VERSION "HNNBNNNYNNNNNNNNNNNNNNNNNNNNNNNNNNNNNNNNNN/4/%%%/4/'%**4NNN///"

NS_ :

BS_:

BU_: BAP_Tester BCM1 Gateway Klima_MSB Lift_VA VAS_L VAS_R

BO_ 960 Klemmen_Status_01: 4 Gateway
 SG_ Klemmen_Status_01_CRC : 0|8@1+ (1,0) [0|255] ""  BCM1,Lift_VA
 SG_ Klemmen_Status_01_BZ : 8|4@1+ (1,0) [0|15] ""  BCM1,Lift_VA
 SG_ RSt_Fahrerhinweise : 12|4@1+ (1.0,0.0) [0.0|15] ""  Vector__XXX
 SG_ ZAS_Kl_S : 16|1@1+ (1.0,0.0) [0.0|1] ""  BCM1,Klima_MSB,VAS_L,VAS_R
 SG_ ZAS_Kl_15 : 17|1@1+ (1.0,0.0) [0.0|1] ""  BCM1,Klima_MSB,Lift_VA,VAS_L,VAS_R
 SG_ ZAS_Kl_X : 18|1@1+ (1.0,0.0) [0.0|1] ""  Vector__XXX
 SG_ ZAS_Kl_50_Startanforderung : 19|1@1+ (1.0,0.0) [0.0|1] ""  BCM1,Klima_MSB
 SG_ BCM_Remotestart_Betrieb : 20|1@1+ (1.0,0.0) [0.0|1] ""  BCM1,Klima_MSB
 SG_ ZAS_Kl_Infotainment : 21|1@1+ (1.0,0.0) [0.0|1] ""  Vector__XXX
 SG_ BCM_Remotestart_KL15_Anf : 22|1@1+ (1.0,0.0) [0.0|1] ""  BCM1
 SG_ BCM_Remotestart_MO_Start : 23|1@1+ (1.0,0.0) [0.0|1] ""  Vector__XXX
 SG_ KST_Warn_P1_ZST_def : 24|1@1+ (1.0,0.0) [0.0|1] ""  Vector__XXX
 SG_ KST_Warn_P2_ZST_def : 25|1@1+ (1.0,0.0) [0.0|1] ""  Vector__XXX
 SG_ KST_Fahrerhinweis_1 : 26|1@1+ (1.0,0.0) [0.0|1] ""  Vector__XXX
 SG_ KST_Fahrerhinweis_2 : 27|1@1+ (1.0,0.0) [0.0|1] ""  Vector__XXX
 SG_ BCM_Ausparken_Betrieb : 28|1@1+ (1.0,0.0) [0.0|1] ""  Vector__XXX
 SG_ KST_Fahrerhinweis_4 : 29|1@1+ (1.0,0.0) [0.0|1] ""  Vector__XXX
 SG_ KST_Fahrerhinweis_5 : 30|1@1+ (1.0,0.0) [0.0|1] ""  Vector__XXX
 SG_ KST_Fahrerhinweis_6 : 31|1@1+ (1.0,0.0) [0.0|1] ""  Vector__XXX

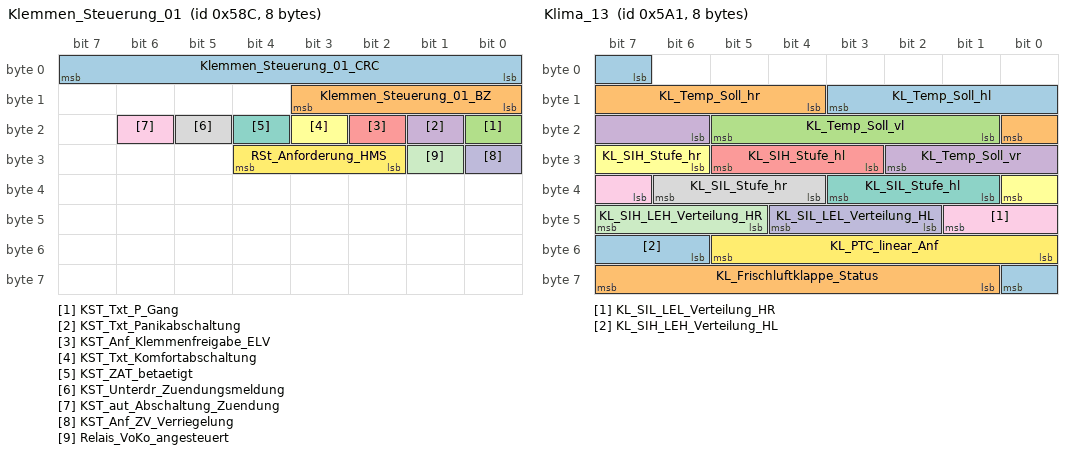
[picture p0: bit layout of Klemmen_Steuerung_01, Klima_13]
BO_ 1420 Klemmen_Steuerung_01: 8 Gateway
 SG_ Klemmen_Steuerung_01_CRC : 0|8@1+ (1,0) [0|255] ""  Vector__XXX
 SG_ Klemmen_Steuerung_01_BZ : 8|4@1+ (1,0) [0|15] ""  Vector__XXX
 SG_ KST_Txt_P_Gang : 16|1@1+ (1.0,0.0) [0.0|1] ""  Vector__XXX
 SG_ KST_Txt_Panikabschaltung : 17|1@1+ (1.0,0.0) [0.0|1] ""  Vector__XXX
 SG_ KST_Anf_Klemmenfreigabe_ELV : 18|1@1+ (1.0,0.0) [0.0|1] ""  Vector__XXX
 SG_ KST_Txt_Komfortabschaltung : 19|1@1+ (1.0,0.0) [0.0|1] ""  Vector__XXX
 SG_ KST_ZAT_betaetigt : 20|1@1+ (1.0,0.0) [0.0|1] ""  Vector__XXX
 SG_ KST_Unterdr_Zuendungsmeldung : 21|1@1+ (1.0,0.0) [0.0|1] ""  Vector__XXX
 SG_ KST_aut_Abschaltung_Zuendung : 22|1@1+ (1.0,0.0) [0.0|1] ""  BCM1
 SG_ KST_Anf_ZV_Verriegelung : 24|1@1+ (1.0,0.0) [0.0|1] ""  Vector__XXX
 SG_ Relais_VoKo_angesteuert : 25|1@1+ (1.0,0.0) [0.0|1] ""  BCM1
 SG_ RSt_Anforderung_HMS : 26|3@1+ (1.0,0.0) [0.0|7] ""  Vector__XXX

BO_ 1646 Klima_03: 8 BCM1
 SG_ KL_STL_aktiv : 0|1@1+ (1.0,0.0) [0.0|1] ""  Gateway
 SG_ KL_STH_aktiv : 1|1@1+ (1.0,0.0) [0.0|1] ""  BCM1,Gateway
 SG_ KL_Solarluefter_aktiv : 2|1@1+ (1.0,0.0) [0.0|1] ""  Gateway
 SG_ KL_Umluft_Taste : 3|1@1+ (1.0,0.0) [0.0|1] ""  Gateway
 SG_ KL_Geblaese_Fond_Status : 4|4@1+ (1.0,0.0) [0.0|15] ""  BCM1,Gateway
 SG_ KL_STH_Ansteuerung : 8|2@1+ (1.0,0.0) [0.0|3] ""  Gateway
 SG_ KL_STH_Betriebsdauer : 10|6@1+ (1,0) [0|60] "Unit_Minut"  Gateway
 SG_ KL_Magnetventil : 16|1@1+ (1.0,0.0) [0.0|1] ""  Gateway
 SG_ KL_WaPu : 17|1@1+ (1.0,0.0) [0.0|1] ""  Gateway
 SG_ KL_Geblaese_Status : 18|4@1+ (1.0,0.0) [0.0|15] ""  BCM1,Gateway
 SG_ KL_Restwaerme_aktiv : 22|1@1+ (1.0,0.0) [0.0|1] ""  Gateway
 SG_ KL_Kompressorkupplung : 23|1@1+ (1.0,0.0) [0.0|1] ""  BCM1,Gateway
 SG_ KL_BCmE_Livetip_Freigabe : 24|1@1+ (1.0,0.0) [0.0|1] ""  Gateway
 SG_ KL_HYB_ASV_hinten_schliessen_Anf : 25|1@1+ (1.0,0.0) [0.0|1] ""  Gateway
 SG_ KL_HYB_ASV_vorne_schliessen_Anf : 26|1@1+ (1.0,0.0) [0.0|1] ""  Gateway
 SG_ KL_ErwVK_Zusatzrelais : 27|1@1+ (1.0,0.0) [0.0|1] ""  Gateway
 SG_ KL_Status_Beduftung : 28|1@1+ (1.0,0.0) [0.0|1] ""  Gateway
 SG_ KL_Status_Ionisator_Front : 29|1@1+ (1.0,0.0) [0.0|1] ""  Gateway
 SG_ KL_STH_Timer_Status : 30|1@1+ (1.0,0.0) [0.0|1] ""  Gateway
 SG_ KL_ErwVK_Anf : 31|1@1+ (1.0,0.0) [0.0|1] ""  BCM1,Gateway
 SG_ KL_Innen_Temp : 32|8@1+ (0.5,-50) [-50.0|76.0] "Unit_DegreCelsi"  BCM1,Gateway
 SG_ KL_I_Geblaese_Fond : 40|8@1+ (0.25,0) [0.00|63.50] "Unit_Amper"  Gateway
 SG_ KL_Anf_AussenspiegelHzg : 48|1@1+ (1.0,0.0) [0.0|1] ""  Gateway
 SG_ KL_Heizkreisventilstellung : 49|2@1+ (1.0,0.0) [0.0|3] ""  Gateway
 SG_ KL_FSH_Automatikbetrieb : 51|1@1+ (1.0,0.0) [0.0|1] ""  Gateway
 SG_ KL_SIH_LEH_Verteilung_VL : 52|3@1+ (1.0,0.0) [0.0|7] ""  BCM1,Gateway
 SG_ KL_SIH_LEL_Verteilung_VL : 55|3@1+ (1.0,0.0) [0.0|7] ""  BCM1,Gateway
 SG_ KL_SIH_LEH_Verteilung_VR : 58|3@1+ (1.0,0.0) [0.0|7] ""  BCM1,Gateway
 SG_ KL_SIH_LEL_Verteilung_VR : 61|3@1+ (1.0,0.0) [0.0|7] ""  BCM1,Gateway

BO_ 1663 Klima_05: 8 BCM1
 SG_ KL_Mod_Display_li : 0|4@1+ (1.0,0.0) [0.0|15] ""  Gateway
 SG_ KL_Mod_Display_re : 4|4@1+ (1.0,0.0) [0.0|15] ""  Gateway
 SG_ KL_Fondbed_vorne_aktiv : 8|1@1+ (1.0,0.0) [0.0|1] ""  Gateway
 SG_ KL_Fond_re_reduziert : 9|1@1+ (1.0,0.0) [0.0|1] ""  Gateway
 SG_ KL_Fond_li_reduziert : 10|1@1+ (1.0,0.0) [0.0|1] ""  Gateway
 SG_ KL_Absperrventil_Fond : 11|1@1+ (1.0,0.0) [0.0|1] ""  Gateway
 SG_ KL_SH_HL_Lastabschaltung : 12|2@1+ (1.0,0.0) [0.0|3] ""  Gateway
 SG_ KL_SH_HR_Lastabschaltung : 14|2@1+ (1.0,0.0) [0.0|3] ""  Gateway
 SG_ KL_Sollausblastemp_HL : 16|10@1+ (0.1,0) [0.0|102.2] "Unit_DegreCelsi"  Gateway
 SG_ KL_Einheiten : 26|1@1+ (1.0,0.0) [0.0|1] ""  Gateway
 SG_ KL_Kindersicherung : 27|1@1+ (1.0,0.0) [0.0|1] ""  Gateway
 SG_ KL_Heizverbraucher_aus : 28|1@1+ (1.0,0.0) [0.0|1] ""  Gateway
 SG_ KL_Heizverbraucher_Notaus : 29|1@1+ (1.0,0.0) [0.0|1] ""  Gateway
 SG_ KL_Gebl_Verst_Abs_Modus : 30|1@1+ (1.0,0.0) [0.0|1] ""  Gateway
 SG_ KL_Sollausblastemp_HR : 32|10@1+ (0.1,0) [0.0|102.2] "Unit_DegreCelsi"  Gateway
 SG_ KL_ICO2_Sensor_defekt : 42|2@1+ (1.0,0.0) [0.0|3] ""  Gateway
 SG_ KL_Umluft : 48|8@1+ (0.5,0) [0.0|100.0] "Unit_PerCent"  Gateway
 SG_ KL_Geblaesespg_Fond : 56|8@1+ (0.1,0) [0.0|25.5] "Unit_Volt"  Gateway

BO_ 1649 Klima_06: 8 BCM1
 SG_ KL_ZZ_Minute : 0|6@1+ (1,0) [0|59] "Unit_Minut"  Gateway
 SG_ KL_ZZ_Status_Timer : 6|2@1+ (1.0,0.0) [0.0|3] ""  Gateway
 SG_ KL_ZZ_Monat : 8|4@1+ (1,0) [1|12] "Unit_Month"  Gateway
 SG_ KL_ZZ_Stunde : 16|5@1+ (1,0) [0|23] "Unit_Hours"  Gateway
 SG_ KL_ZZ_Betriebsmodus : 21|3@1+ (1.0,0.0) [0.0|7] ""  Gateway
 SG_ KL_ZZ_Tag : 24|5@1+ (1,0) [1|31] "Unit_Day"  Gateway
 SG_ KL_Betriebsmodus_FH : 29|3@1+ (1.0,0.0) [0.0|7] ""  Gateway
 SG_ KL_Stopp_Wiederstart_Anz_01 : 32|1@1+ (1.0,0.0) [0.0|1] ""  Gateway
 SG_ KL_Stopp_Wiederstart_Anz_02 : 33|1@1+ (1.0,0.0) [0.0|1] ""  Gateway
 SG_ KL_Stopp_Wiederstart_Anz_03 : 34|1@1+ (1.0,0.0) [0.0|1] ""  Gateway
 SG_ KL_Stopp_Wiederstart_Anz_04 : 35|1@1+ (1.0,0.0) [0.0|1] ""  Gateway
 SG_ KL_Stopp_Wiederstart_Anz_05 : 36|1@1+ (1.0,0.0) [0.0|1] ""  Gateway
 SG_ KL_Stopp_Wiederstart_Anz_06 : 37|1@1+ (1.0,0.0) [0.0|1] ""  Gateway
 SG_ KL_Stopp_Wiederstart_Anz_07 : 38|1@1+ (1.0,0.0) [0.0|1] ""  Gateway
 SG_ KL_Stopp_Wiederstart_Anz_08 : 39|1@1+ (1.0,0.0) [0.0|1] ""  Gateway
 SG_ KL_Stopp_Wiederstart_Anz_09 : 40|1@1+ (1.0,0.0) [0.0|1] ""  Gateway
 SG_ KL_Stopp_Wiederstart_Anz_Std1 : 41|1@1+ (1.0,0.0) [0.0|1] ""  Gateway
 SG_ KL_Stopp_Wiederstart_Anz_Std2 : 42|1@1+ (1.0,0.0) [0.0|1] ""  Gateway

BO_ 1608 Klima_07: 8 BCM1
 SG_ KL_AUTO_HL_Soll : 0|1@1+ (1.0,0.0) [0.0|1] ""  Gateway
 SG_ KL_AUTO_HR_Soll : 1|1@1+ (1.0,0.0) [0.0|1] ""  Gateway
 SG_ KL_AC_Fond_Soll : 2|1@1+ (1.0,0.0) [0.0|1] ""  Gateway
 SG_ KL_Fondbedienung_aktiv : 3|1@1+ (1.0,0.0) [0.0|1] ""  Gateway
 SG_ KL_Status_Soll : 4|1@1+ (1.0,0.0) [0.0|1] ""  Gateway
 SG_ KL_Befehlszaehler_FH : 5|3@1+ (1,0) [0|7] ""  Gateway
 SG_ KL_Luftmenge_HR_Soll : 8|4@1+ (1,0) [0|12] ""  Gateway
 SG_ KL_Luftmenge_HL_Soll : 12|4@1+ (1,0) [0|12] ""  Gateway
 SG_ KL_Luftverteilung_HR_Soll : 16|4@1+ (1.0,0.0) [0.0|15] ""  Gateway
 SG_ KL_Luftverteilung_HL_Soll : 20|4@1+ (1.0,0.0) [0.0|15] ""  Gateway
 SG_ KL_SL_HL_Soll : 24|3@1+ (1,0) [0|6] ""  BCM1,Gateway
 SG_ KL_SL_HR_Soll : 27|3@1+ (1,0) [0|6] ""  BCM1,Gateway
 SG_ KL_SH_HR_Soll : 30|3@1+ (1,0) [0|6] ""  BCM1,Gateway
 SG_ KL_SH_HL_Soll : 33|3@1+ (1,0) [0|6] ""  BCM1,Gateway
 SG_ KL_Temp_HL_Soll : 36|5@1+ (0.5,15.5) [15.5|30.0] "Unit_DegreCelsi"  Gateway
 SG_ KL_Temp_HR_Soll : 41|5@1+ (0.5,15.5) [15.5|30.0] "Unit_DegreCelsi"  Gateway
 SG_ KL_Luftmenge_HR_max : 46|4@1+ (1,0) [0|12] ""  Gateway
 SG_ KL_Luftmenge_HL_max : 50|4@1+ (1,0) [0|12] ""  Gateway
 SG_ KL_Luftmenge_HR_offset : 54|5@1+ (1,-12) [-12|12] ""  Gateway
 SG_ KL_Luftmenge_HL_offset : 59|5@1+ (1,-12) [-12|12] ""  Gateway

BO_ 949 Klima_11: 8 BCM1
 SG_ KL_Drehz_Anh : 0|1@1+ (1.0,0.0) [0.0|1] ""  Gateway
 SG_ KL_Vorwarn_Komp_ein : 1|1@1+ (1.0,0.0) [0.0|1] ""  Gateway
 SG_ KL_AC_Schalter : 2|1@1+ (1.0,0.0) [0.0|1] ""  Gateway
 SG_ KL_Komp_Moment_alt : 3|1@1+ (1.0,0.0) [0.0|1] ""  Gateway
 SG_ KL_Vorwarn_Zuheizer_ein : 6|1@1+ (1.0,0.0) [0.0|1] ""  Gateway
 SG_ KL_Zustand : 7|1@1+ (1.0,0.0) [0.0|1] ""  Gateway
 SG_ KL_Kompressorkupplung_linear : 8|8@1+ (20,0) [0|4000] "Unit_MilliAmper"  BCM1,Gateway
 SG_ KL_Charisma_FahrPr : 16|4@1+ (1.0,0.0) [0.0|15] ""  Gateway
 SG_ KL_Charisma_Status : 20|2@1+ (1.0,0.0) [0.0|3] ""  Gateway
 SG_ KL_nachtr_Stopp_Anf : 22|1@1+ (1.0,0.0) [0.0|1] ""  Gateway
 SG_ KL_T_Charge : 23|1@1+ (1.0,0.0) [0.0|1] ""  Gateway
 SG_ KL_Last_Kompr : 24|8@1+ (0.25,0) [0.00|63.50] "Unit_NewtoMeter"  Gateway
 SG_ KL_Spannungs_Anf : 32|2@1+ (1.0,0.0) [0.0|3] ""  Gateway
 SG_ KL_Thermomanagement : 34|2@1+ (1.0,0.0) [0.0|3] ""  Gateway
 SG_ KL_StartStopp_Info : 36|2@1+ (1.0,0.0) [0.0|3] ""  Gateway
 SG_ KL_Freilauf_Info : 38|2@1+ (1.0,0.0) [0.0|3] ""  Gateway
 SG_ KL_Anf_KL : 40|8@1+ (0.4,0) [0.0|101.6] "Unit_PerCent"  Gateway
 SG_ KL_el_Zuheizer_Stufe : 48|3@1+ (1.0,0.0) [0.0|7] ""  BCM1,Gateway
 SG_ KL_Ausstattung_Klima : 51|3@1+ (1.0,0.0) [0.0|7] ""  BCM1,Gateway
 SG_ KL_Variante_Standheizung : 54|2@1+ (1.0,0.0) [0.0|3] ""  Gateway

BO_ 1640 Klima_12: 8 BCM1
 SG_ KL_LRH_Taster : 0|1@1+ (1.0,0.0) [0.0|1] ""  Gateway
 SG_ KL_LRH_Stufe : 1|2@1+ (1.0,0.0) [0.0|3] ""  Gateway
 SG_ HSH_Taster : 3|2@1+ (1.0,0.0) [0.0|3] ""  Gateway
 SG_ FSH_Taster : 5|1@1+ (1.0,0.0) [0.0|1] ""  Gateway
 SG_ KL_Zuheizer_Freigabe : 6|1@1+ (1.0,0.0) [0.0|1] ""  Gateway
 SG_ KL_Beschlagsgefahr : 7|1@1+ (1.0,0.0) [0.0|1] ""  Gateway
 SG_ KL_SIH_Soll_li : 8|3@1+ (1.0,0.0) [0.0|7] ""  BCM1,Gateway
 SG_ KL_SIH_Soll_re : 11|3@1+ (1.0,0.0) [0.0|7] ""  BCM1,Gateway
 SG_ KRH_Soll_li : 14|2@1+ (1.0,0.0) [0.0|3] ""  Gateway
 SG_ KL_SIL_Soll_li : 16|3@1+ (1.0,0.0) [0.0|7] ""  BCM1,Gateway
 SG_ KL_SIL_Soll_re : 19|3@1+ (1.0,0.0) [0.0|7] ""  BCM1,Gateway
 SG_ KRH_Soll_re : 22|2@1+ (1.0,0.0) [0.0|3] ""  Gateway
 SG_ KL_Geblspng_Soll : 24|8@1+ (0.05,1.45) [1.50|14.00] "Unit_Volt"  Gateway
 SG_ KL_Geblspng_Fond_Soll : 32|8@1+ (0.05,1.45) [1.50|14.00] "Unit_Volt"  Gateway
 SG_ KL_I_Geblaese : 40|8@1+ (0.25,0) [0.00|63.50] "Unit_Amper"  Gateway
 SG_ KL_Kompressorstrom_soll : 48|10@1+ (1,0) [0|1021] ""  BCM1,Gateway
 SG_ KL_Umluftklappe_Status : 58|4@1+ (1.0,0.0) [0.0|15] ""  Gateway
 SG_ KL_PTC_Verbauinfo : 62|2@1+ (1.0,0.0) [0.0|3] ""  Gateway

BO_ 1441 Klima_13: 8 BCM1
 SG_ KL_Temp_Soll_hl : 7|5@1+ (0.5,15.5) [15.5|30.0] "Unit_DegreCelsi"  BCM1,Gateway
 SG_ KL_Temp_Soll_hr : 12|5@1+ (0.5,15.5) [15.5|30.0] "Unit_DegreCelsi"  BCM1,Gateway
 SG_ KL_Temp_Soll_vl : 17|5@1+ (0.5,15.5) [15.5|30.0] "Unit_DegreCelsi"  BCM1,Gateway
 SG_ KL_Temp_Soll_vr : 22|5@1+ (0.5,15.5) [15.5|30.0] "Unit_DegreCelsi"  BCM1,Gateway
 SG_ KL_SIH_Stufe_hl : 27|3@1+ (1,0) [0|6] ""  BCM1,Gateway
 SG_ KL_SIH_Stufe_hr : 30|3@1+ (1,0) [0|6] ""  BCM1,Gateway
 SG_ KL_SIL_Stufe_hl : 33|3@1+ (1,0) [0|6] ""  BCM1,Gateway
 SG_ KL_SIL_Stufe_hr : 36|3@1+ (1,0) [0|6] ""  BCM1,Gateway
 SG_ KL_SIL_LEL_Verteilung_HR : 39|3@1+ (1.0,0.0) [0.0|7] ""  BCM1,Gateway
 SG_ KL_SIL_LEL_Verteilung_HL : 42|3@1+ (1.0,0.0) [0.0|7] ""  BCM1,Gateway
 SG_ KL_SIH_LEH_Verteilung_HR : 45|3@1+ (1.0,0.0) [0.0|7] ""  BCM1,Gateway
 SG_ KL_PTC_linear_Anf : 48|6@1+ (50,0) [0|3100] "Unit_Watt"  Gateway
 SG_ KL_SIH_LEH_Verteilung_HL : 54|3@1+ (1.0,0.0) [0.0|7] ""  BCM1,Gateway
 SG_ KL_Frischluftklappe_Status : 57|7@1+ (1,0) [0|100] "Unit_PerCent"  Gateway

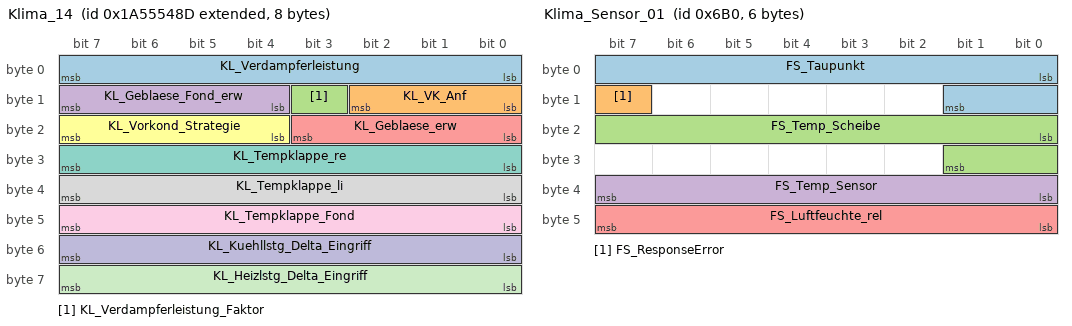
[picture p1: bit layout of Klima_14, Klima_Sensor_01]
BO_ 2589283469 Klima_14: 8 BCM1
 SG_ KL_Verdampferleistung : 0|8@1+ (25,0) [0|6325] "Unit_Watt"  Gateway
 SG_ KL_VK_Anf : 8|3@1+ (1.0,0.0) [0.0|7] ""  Gateway
 SG_ KL_Verdampferleistung_Faktor : 11|1@1+ (1.0,0.0) [0.0|1] ""  Gateway
 SG_ KL_Geblaese_Fond_erw : 12|4@1+ (1.0,0.0) [0.0|15] ""  Gateway
 SG_ KL_Geblaese_erw : 16|4@1+ (1.0,0.0) [0.0|15] ""  Gateway
 SG_ KL_Vorkond_Strategie : 20|4@1+ (1.0,0.0) [0.0|15] ""  Gateway
 SG_ KL_Tempklappe_re : 24|8@1+ (0.5,0) [0.0|100.0] "Unit_PerCent"  Gateway
 SG_ KL_Tempklappe_li : 32|8@1+ (0.5,0) [0.0|100.0] "Unit_PerCent"  Gateway
 SG_ KL_Tempklappe_Fond : 40|8@1+ (0.5,0) [0.0|100.0] "Unit_PerCent"  Gateway
 SG_ KL_Kuehllstg_Delta_Eingriff : 48|8@1+ (50,-6300) [-6300|6350] "Unit_Watt"  Gateway
 SG_ KL_Heizlstg_Delta_Eingriff : 56|8@1+ (50,-6300) [-6300|6350] "Unit_Watt"  Gateway

BO_ 2589283621 Klima_17: 8 BCM1
 SG_ KL_NV_Energie_Anf : 12|8@1+ (10,0) [0|2530] "Unit_WattHour"  Gateway
 SG_ KL_FlHz_Soll_VL : 20|3@1+ (1,0) [0|6] "Unit_None"  BCM1,Gateway
 SG_ KL_FlHz_Soll_HL : 23|3@1+ (1,0) [0|6] "Unit_None"  BCM1,Gateway
 SG_ KL_FlHz_Soll_VR : 26|3@1+ (1,0) [0|6] "Unit_None"  BCM1,Gateway
 SG_ KL_FlHz_Soll_HR : 29|3@1+ (1,0) [0|6] "Unit_None"  BCM1,Gateway
 SG_ KL_Umluft_Connect_status : 32|3@1+ (1.0,0.0) [0.0|7] ""  Gateway
 SG_ KL_ECO_PRO_Aktiv : 35|1@1+ (1.0,0.0) [0.0|1] ""  Gateway
 SG_ KL_QBit_Sonnenintensitaet : 36|1@1+ (1.0,0.0) [0.0|1] ""  Gateway
 SG_ KL_ZR_Anforderung : 37|2@1+ (1.0,0.0) [0.0|3] ""  Gateway
 SG_ KL_ACmax_Aktiv : 39|1@1+ (1.0,0.0) [0.0|1] ""  Gateway
 SG_ KL_Defrost_Aktiv : 40|1@1+ (1.0,0.0) [0.0|1] ""  Gateway
 SG_ KL_ECO_Aktiv : 41|1@1+ (1.0,0.0) [0.0|1] ""  Gateway
 SG_ KL_Status_Klimastil : 42|2@1+ (1.0,0.0) [0.0|3] ""  Gateway
 SG_ KL_Kundeneingriff_Geblaese : 44|1@1+ (1.0,0.0) [0.0|1] ""  Gateway
 SG_ KL_Thermischer_Bedarf : 45|3@1+ (1.0,0.0) [0.0|7] ""  Gateway
 SG_ KL_Eps_Innen : 48|8@1+ (0.5,-50) [-50.0|50.0] "Unit_DegreCelsi"  Gateway
 SG_ KL_Sonnenintensitaet : 56|8@1+ (10,0) [0|1000] "Unit_WattPerMeterSquar"  Gateway

BO_ 992 Klima_hinten_01: 8 BCM1
 SG_ KL_Fond_Fuss_Temp_hl : 0|10@1+ (0.1,-5) [-5.0|97.1] "Unit_DegreCelsi"  Gateway
 SG_ KL_SL_Soll_hl : 10|3@1+ (1.0,0.0) [0.0|7] ""  BCM1,Gateway
 SG_ KL_SL_Soll_hr : 13|3@1+ (1.0,0.0) [0.0|7] ""  BCM1,Gateway
 SG_ KL_Fond_Fuss_Temp_hr : 16|10@1+ (0.1,-5) [-5.0|97.1] "Unit_DegreCelsi"  Gateway
 SG_ KL_SH_Soll_hl : 26|3@1+ (1.0,0.0) [0.0|7] ""  BCM1,Gateway
 SG_ KL_SH_Soll_hr : 29|3@1+ (1.0,0.0) [0.0|7] ""  BCM1,Gateway
 SG_ KL_MA_Temp_hl : 32|10@1+ (0.1,-5) [-5.0|97.1] "Unit_DegreCelsi"  Gateway
 SG_ KL_SIH_Takt_hl : 42|1@1+ (1.0,0.0) [0.0|1] ""  Gateway
 SG_ KL_SIH_Takt_hr : 43|1@1+ (1.0,0.0) [0.0|1] ""  Gateway
 SG_ KL_Fehler_Umluft : 44|1@1+ (1.0,0.0) [0.0|1] ""  Gateway
 SG_ KL_RAB : 45|1@1+ (1.0,0.0) [0.0|1] ""  Gateway
 SG_ KL_Fond_Absperrventil : 46|1@1+ (1.0,0.0) [0.0|1] ""  Gateway
 SG_ KL_Fond_KD_Fehler : 47|1@1+ (1.0,0.0) [0.0|1] ""  Gateway
 SG_ KL_MA_Temp_hr : 48|10@1+ (0.1,-5) [-5.0|97.1] "Unit_DegreCelsi"  Gateway
 SG_ KL_Fehler_Fussraum_Klappen : 58|2@1+ (1.0,0.0) [0.0|3] ""  Gateway
 SG_ KL_Fehler_Temp_Klappen : 60|2@1+ (1.0,0.0) [0.0|3] ""  Gateway
 SG_ KL_Fehler_Temp_MA_Klappen : 62|2@1+ (1.0,0.0) [0.0|3] ""  Gateway

BO_ 1712 Klima_Sensor_01: 6 BCM1
 SG_ FS_Taupunkt : 0|10@1+ (0.1,-39.6) [-39.5|60.4] "Unit_DegreCelsi"  Gateway,Klima_MSB
 SG_ FS_ResponseError : 15|1@1+ (1.0,0.0) [0.0|1] ""  Gateway,Klima_MSB
 SG_ FS_Temp_Scheibe : 16|10@1+ (0.1,-39.6) [-39.5|60.4] "Unit_DegreCelsi"  Gateway,Klima_MSB
 SG_ FS_Temp_Sensor : 32|8@1+ (0.5,-40) [-39.5|87.0] "Unit_DegreCelsi"  Gateway,Klima_MSB
 SG_ FS_Luftfeuchte_rel : 40|8@1+ (0.5,-0.5) [0.0|100.0] "Unit_PerCent"  Gateway,Klima_MSB

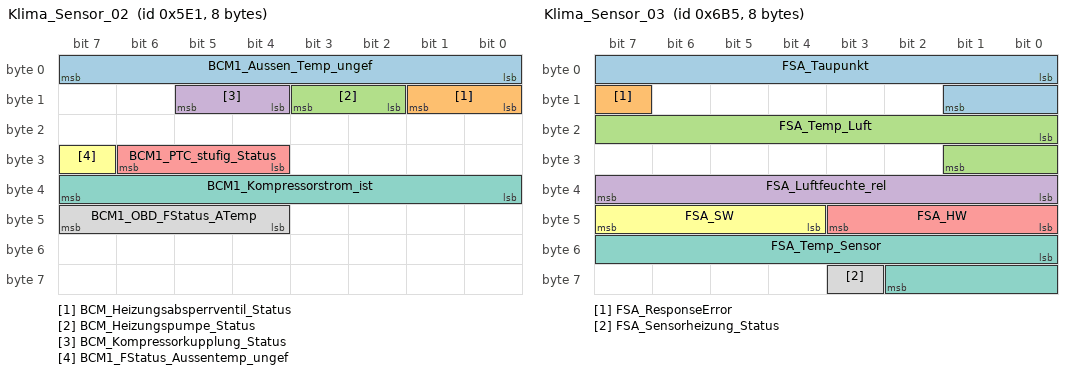
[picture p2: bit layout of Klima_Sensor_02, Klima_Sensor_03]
BO_ 1505 Klima_Sensor_02: 8 BCM1
 SG_ BCM1_Aussen_Temp_ungef : 0|8@1+ (0.5,-50) [-50.0|76.0] "Unit_DegreCelsi"  Gateway,Klima_MSB,VAS_L,VAS_R
 SG_ BCM_Heizungsabsperrventil_Status : 8|2@1+ (1.0,0.0) [0.0|3] ""  Gateway,Klima_MSB
 SG_ BCM_Heizungspumpe_Status : 10|2@1+ (1.0,0.0) [0.0|3] ""  Gateway,Klima_MSB
 SG_ BCM_Kompressorkupplung_Status : 12|2@1+ (1.0,0.0) [0.0|3] ""  Gateway,Klima_MSB
 SG_ BCM1_PTC_stufig_Status : 28|3@1+ (1.0,0.0) [0.0|7] ""  Gateway,Klima_MSB
 SG_ BCM1_FStatus_Aussentemp_ungef : 31|1@1+ (1.0,0.0) [0.0|1] ""  Gateway,Klima_MSB,VAS_L,VAS_R
 SG_ BCM1_Kompressorstrom_ist : 32|8@1+ (4,0) [0|1000] "Unit_MilliAmper"  Gateway,Klima_MSB
 SG_ BCM1_OBD_FStatus_ATemp : 44|4@1+ (1.0,0.0) [0.0|15] ""  Gateway,Klima_MSB

BO_ 1717 Klima_Sensor_03: 8 BCM1
 SG_ FSA_Taupunkt : 0|10@1+ (0.1,-40) [-40.0|60.0] "Unit_DegreCelsi"  Gateway
 SG_ FSA_ResponseError : 15|1@1+ (1.0,0.0) [0.0|1] ""  Gateway
 SG_ FSA_Temp_Luft : 16|10@1+ (0.1,-40) [-40.0|61.0] "Unit_DegreCelsi"  Gateway
 SG_ FSA_Luftfeuchte_rel : 32|8@1+ (0.5,0) [0.0|126.0] "Unit_PerCent"  Gateway
 SG_ FSA_HW : 40|4@1+ (1,0) [0|15] ""  Gateway
 SG_ FSA_SW : 44|4@1+ (1,0) [0|15] ""  Gateway
 SG_ FSA_Temp_Sensor : 48|11@1+ (0.1,-40) [-40.0|90.0] "Unit_DegreCelsi"  Gateway
 SG_ FSA_Sensorheizung_Status : 59|1@1+ (1.0,0.0) [0.0|1] ""  Gateway

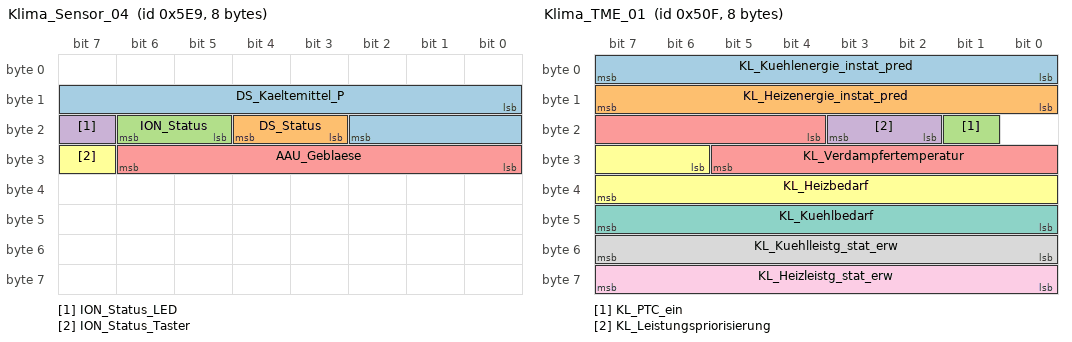
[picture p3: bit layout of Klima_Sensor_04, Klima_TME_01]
BO_ 1513 Klima_Sensor_04: 8 BCM1
 SG_ DS_Kaeltemittel_P : 8|11@1+ (0.0161,0) [0.0000|32.9245] "Unit_Bar"  Gateway
 SG_ DS_Status : 19|2@1+ (1.0,0.0) [0.0|3] ""  Gateway
 SG_ ION_Status : 21|2@1+ (1.0,0.0) [0.0|3] ""  Gateway
 SG_ ION_Status_LED : 23|1@1+ (1.0,0.0) [0.0|1] ""  Gateway
 SG_ AAU_Geblaese : 24|7@1+ (1,0) [0|100] "Unit_PerCent"  Gateway
 SG_ ION_Status_Taster : 31|1@1+ (1.0,0.0) [0.0|1] ""  Gateway

BO_ 1295 Klima_TME_01: 8 BCM1
 SG_ KL_Kuehlenergie_instat_pred : 0|8@1+ (25,0) [0|6325] "Unit_WattHour"  Gateway
 SG_ KL_Heizenergie_instat_pred : 8|8@1+ (25,0) [0|6325] "Unit_WattHour"  Gateway
 SG_ KL_PTC_ein : 17|1@1+ (1.0,0.0) [0.0|1] ""  Gateway
 SG_ KL_Leistungspriorisierung : 18|2@1+ (1.0,0.0) [0.0|3] ""  Gateway
 SG_ KL_Verdampfertemperatur : 20|10@1+ (0.1,-20) [-20.0|70.0] "Unit_DegreCelsi"  Gateway
 SG_ KL_Heizbedarf : 30|10@1+ (0.1,0) [0.1|90.0] "Unit_DegreCelsi"  Gateway
 SG_ KL_Kuehlbedarf : 40|8@1+ (0.1,0) [0.0|25.0] "Unit_DegreCelsi"  Gateway
 SG_ KL_Kuehlleistg_stat_erw : 48|8@1+ (50,0) [0|12650] "Unit_Watt"  Gateway
 SG_ KL_Heizleistg_stat_erw : 56|8@1+ (50,0) [0|12650] "Unit_Watt"  Gateway

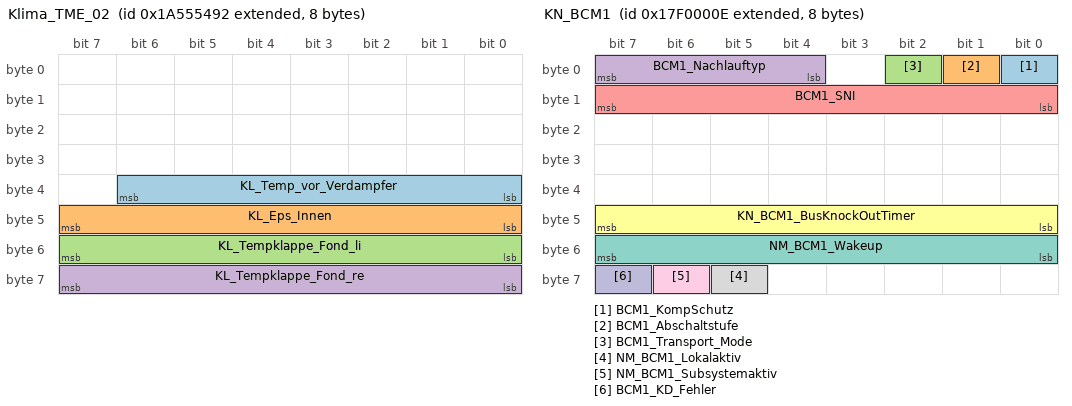
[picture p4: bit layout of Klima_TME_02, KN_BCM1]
BO_ 2589283474 Klima_TME_02: 8 BCM1
 SG_ KL_Temp_vor_Verdampfer : 32|7@1+ (1,-20) [-20|70] "Unit_DegreCelsi"  Gateway
 SG_ KL_Eps_Innen : 40|8@1+ (0.5,-50) [-50.0|50.0] "Unit_DegreCelsi"  Gateway
 SG_ KL_Tempklappe_Fond_li : 48|8@1+ (0.5,0) [0.0|100.0] "Unit_PerCent"  Gateway
 SG_ KL_Tempklappe_Fond_re : 56|8@1+ (0.5,0) [0.0|100.0] "Unit_PerCent"  Gateway

BO_ 2549088270 KN_BCM1: 8 BCM1
 SG_ BCM1_KompSchutz : 0|1@1+ (1.0,0.0) [0.0|1] ""  Vector__XXX
 SG_ BCM1_Abschaltstufe : 1|1@1+ (1.0,0.0) [0.0|1] ""  Vector__XXX
 SG_ BCM1_Transport_Mode : 2|1@1+ (1.0,0.0) [0.0|1] ""  Vector__XXX
 SG_ BCM1_Nachlauftyp : 4|4@1+ (1.0,0.0) [0.0|15] ""  Gateway
 SG_ BCM1_SNI : 8|8@1+ (1.0,0.0) [0.0|255] ""  Gateway
 SG_ KN_BCM1_BusKnockOutTimer : 40|8@1+ (1,0) [0|254] ""  Gateway
 SG_ NM_BCM1_Wakeup : 48|8@1+ (1.0,0.0) [0.0|255] ""  Vector__XXX
 SG_ NM_BCM1_Lokalaktiv : 61|1@1+ (1.0,0.0) [0.0|1] ""  Gateway
 SG_ NM_BCM1_Subsystemaktiv : 62|1@1+ (1.0,0.0) [0.0|1] ""  Gateway
 SG_ BCM1_KD_Fehler : 63|1@1+ (1.0,0.0) [0.0|1] ""  Gateway

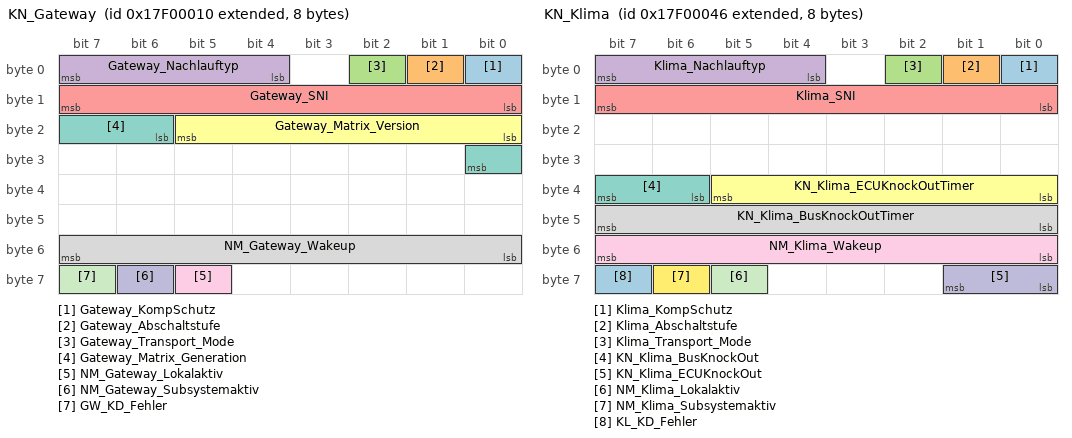
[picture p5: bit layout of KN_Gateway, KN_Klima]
BO_ 2549088272 KN_Gateway: 8 Gateway
 SG_ Gateway_KompSchutz : 0|1@1+ (1.0,0.0) [0.0|1] ""  Vector__XXX
 SG_ Gateway_Abschaltstufe : 1|1@1+ (1.0,0.0) [0.0|1] ""  Vector__XXX
 SG_ Gateway_Transport_Mode : 2|1@1+ (1.0,0.0) [0.0|1] ""  Vector__XXX
 SG_ Gateway_Nachlauftyp : 4|4@1+ (1.0,0.0) [0.0|15] ""  Vector__XXX
 SG_ Gateway_SNI : 8|8@1+ (1.0,0.0) [0.0|255] ""  Vector__XXX
 SG_ Gateway_Matrix_Version : 16|6@1+ (1,0) [0|63] "Unit_None"  Vector__XXX
 SG_ Gateway_Matrix_Generation : 22|3@1+ (1,0) [0|7] "Unit_None"  Vector__XXX
 SG_ NM_Gateway_Wakeup : 48|8@1+ (1.0,0.0) [0.0|255] ""  Vector__XXX
 SG_ NM_Gateway_Lokalaktiv : 61|1@1+ (1.0,0.0) [0.0|1] ""  Vector__XXX
 SG_ NM_Gateway_Subsystemaktiv : 62|1@1+ (1.0,0.0) [0.0|1] ""  Vector__XXX
 SG_ GW_KD_Fehler : 63|1@1+ (1.0,0.0) [0.0|1] ""  Vector__XXX

BO_ 2549088326 KN_Klima: 8 Klima_MSB
 SG_ Klima_KompSchutz : 0|1@1+ (1.0,0.0) [0.0|1] ""  Vector__XXX
 SG_ Klima_Abschaltstufe : 1|1@1+ (1.0,0.0) [0.0|1] ""  Vector__XXX
 SG_ Klima_Transport_Mode : 2|1@1+ (1.0,0.0) [0.0|1] ""  Vector__XXX
 SG_ Klima_Nachlauftyp : 4|4@1+ (1.0,0.0) [0.0|15] ""  Gateway
 SG_ Klima_SNI : 8|8@1+ (1.0,0.0) [0.0|255] ""  Gateway
 SG_ KN_Klima_ECUKnockOutTimer : 32|6@1+ (1,0) [0|62] "Unit_Minut"  Gateway
 SG_ KN_Klima_BusKnockOut : 38|2@1+ (1.0,0.0) [0.0|3] ""  Gateway
 SG_ KN_Klima_BusKnockOutTimer : 40|8@1+ (1,0) [0|254] ""  Gateway
 SG_ NM_Klima_Wakeup : 48|8@1+ (1.0,0.0) [0.0|255] ""  Vector__XXX
 SG_ KN_Klima_ECUKnockOut : 56|2@1+ (1.0,0.0) [0.0|3] ""  Gateway
 SG_ NM_Klima_Lokalaktiv : 61|1@1+ (1.0,0.0) [0.0|1] ""  Gateway
 SG_ NM_Klima_Subsystemaktiv : 62|1@1+ (1.0,0.0) [0.0|1] ""  Gateway
 SG_ KL_KD_Fehler : 63|1@1+ (1.0,0.0) [0.0|1] ""  Gateway

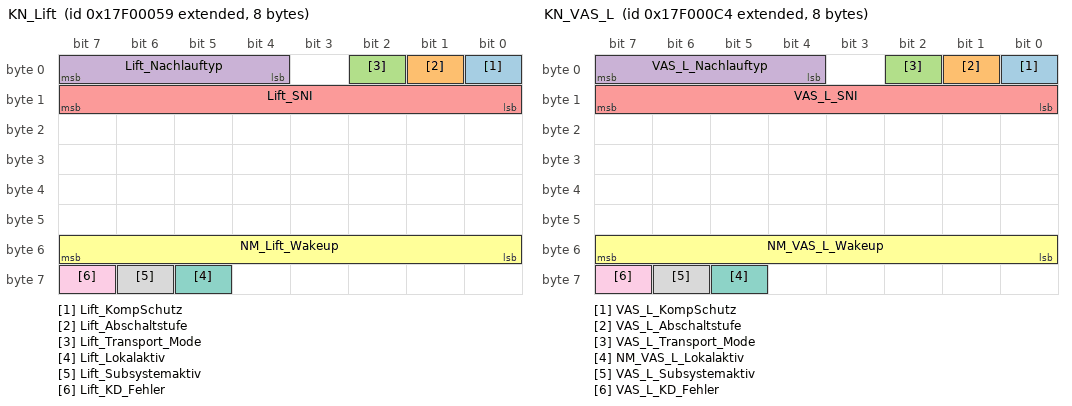
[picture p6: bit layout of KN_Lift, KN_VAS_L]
BO_ 2549088345 KN_Lift: 8 Lift_VA
 SG_ Lift_KompSchutz : 0|1@1+ (1.0,0.0) [0.0|1] ""  Vector__XXX
 SG_ Lift_Abschaltstufe : 1|1@1+ (1.0,0.0) [0.0|1] ""  Vector__XXX
 SG_ Lift_Transport_Mode : 2|1@1+ (1.0,0.0) [0.0|1] ""  Vector__XXX
 SG_ Lift_Nachlauftyp : 4|4@1+ (1.0,0.0) [0.0|15] ""  Gateway
 SG_ Lift_SNI : 8|8@1+ (1.0,0.0) [0.0|255] ""  Gateway
 SG_ NM_Lift_Wakeup : 48|8@1+ (1.0,0.0) [0.0|255] ""  Vector__XXX
 SG_ Lift_Lokalaktiv : 61|1@1+ (1.0,0.0) [0.0|1] ""  Gateway
 SG_ Lift_Subsystemaktiv : 62|1@1+ (1.0,0.0) [0.0|1] ""  Gateway
 SG_ Lift_KD_Fehler : 63|1@1+ (1.0,0.0) [0.0|1] ""  Gateway

BO_ 2549088452 KN_VAS_L: 8 VAS_L
 SG_ VAS_L_KompSchutz : 0|1@1+ (1.0,0.0) [0.0|1] ""  Vector__XXX
 SG_ VAS_L_Abschaltstufe : 1|1@1+ (1.0,0.0) [0.0|1] ""  Vector__XXX
 SG_ VAS_L_Transport_Mode : 2|1@1+ (1.0,0.0) [0.0|1] ""  Vector__XXX
 SG_ VAS_L_Nachlauftyp : 4|4@1+ (1.0,0.0) [0.0|15] ""  Gateway
 SG_ VAS_L_SNI : 8|8@1+ (1.0,0.0) [0.0|255] ""  Gateway
 SG_ NM_VAS_L_Wakeup : 48|8@1+ (1.0,0.0) [0.0|255] ""  Vector__XXX
 SG_ NM_VAS_L_Lokalaktiv : 61|1@1+ (1.0,0.0) [0.0|1] ""  Gateway
 SG_ VAS_L_Subsystemaktiv : 62|1@1+ (1.0,0.0) [0.0|1] ""  Vector__XXX
 SG_ VAS_L_KD_Fehler : 63|1@1+ (1.0,0.0) [0.0|1] ""  Gateway

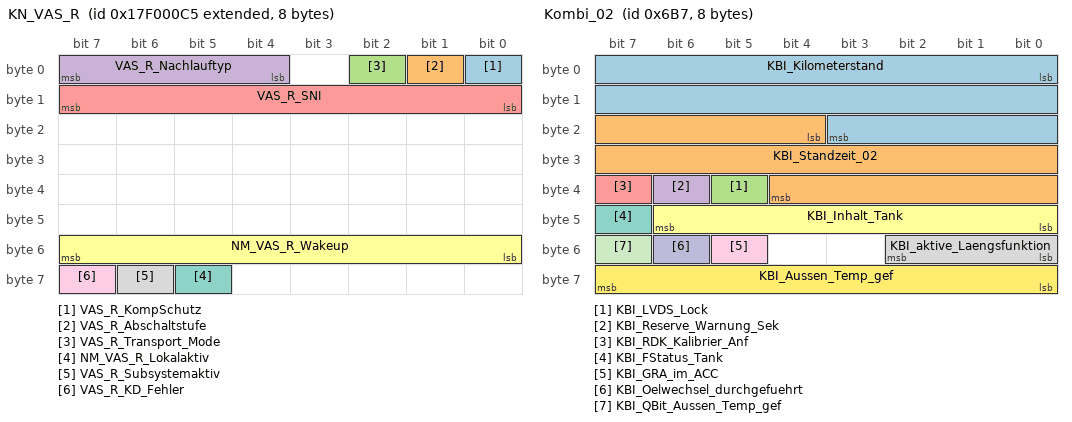
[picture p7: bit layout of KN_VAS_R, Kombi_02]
BO_ 2549088453 KN_VAS_R: 8 VAS_R
 SG_ VAS_R_KompSchutz : 0|1@1+ (1.0,0.0) [0.0|1] ""  Vector__XXX
 SG_ VAS_R_Abschaltstufe : 1|1@1+ (1.0,0.0) [0.0|1] ""  Vector__XXX
 SG_ VAS_R_Transport_Mode : 2|1@1+ (1.0,0.0) [0.0|1] ""  Vector__XXX
 SG_ VAS_R_Nachlauftyp : 4|4@1+ (1.0,0.0) [0.0|15] ""  Gateway
 SG_ VAS_R_SNI : 8|8@1+ (1.0,0.0) [0.0|255] ""  Gateway
 SG_ NM_VAS_R_Wakeup : 48|8@1+ (1.0,0.0) [0.0|255] ""  Vector__XXX
 SG_ NM_VAS_R_Lokalaktiv : 61|1@1+ (1.0,0.0) [0.0|1] ""  Gateway
 SG_ VAS_R_Subsystemaktiv : 62|1@1+ (1.0,0.0) [0.0|1] ""  Vector__XXX
 SG_ VAS_R_KD_Fehler : 63|1@1+ (1.0,0.0) [0.0|1] ""  Gateway

BO_ 779 Kombi_01: 8 Gateway
 SG_ KBI_ABS_Lampe : 0|1@1+ (1.0,0.0) [0.0|1] ""  Vector__XXX
 SG_ KBI_ESP_Lampe : 1|1@1+ (1.0,0.0) [0.0|1] ""  BCM1
 SG_ KBI_BKL_Lampe : 2|1@1+ (1.0,0.0) [0.0|1] ""  Vector__XXX
 SG_ KBI_Airbag_Lampe : 3|1@1+ (1.0,0.0) [0.0|1] ""  Vector__XXX
 SG_ KBI_SILA_gueltig : 4|1@1+ (1.0,0.0) [0.0|1] ""  Vector__XXX
 SG_ KBI_Lenkung_Lampe : 5|1@1+ (1,0) [0|1] ""  Vector__XXX
 SG_ KBI_Vorglueh_System_Lampe : 6|1@1+ (1.0,0.0) [0.0|1] ""  Vector__XXX
 SG_ KBI_NV_in_Anzeige : 7|1@1+ (1.0,0.0) [0.0|1] ""  Vector__XXX
 SG_ Kombi_01_BZ : 8|4@1+ (1,0) [0|15] ""  Vector__XXX
 SG_ KBI_Anzeigestatus_ACC : 12|1@1+ (1.0,0.0) [0.0|1] ""  Vector__XXX
 SG_ KBI_Anzeigestatus_GRA : 13|2@1+ (1.0,0.0) [0.0|3] ""  Vector__XXX
 SG_ KBI_Tankwarnung : 16|1@1+ (1.0,0.0) [0.0|1] ""  BCM1,Klima_MSB
 SG_ KBI_MFA_v_Einheit_01 : 17|1@1+ (1.0,0.0) [0.0|1] ""  Vector__XXX
 SG_ KBI_im_Stellgliedtest : 18|1@1+ (1.0,0.0) [0.0|1] ""  Vector__XXX
 SG_ KBI_Anzeigefehler_LDW : 19|2@1+ (1.0,0.0) [0.0|3] ""  Vector__XXX
 SG_ KBI_Tankwarnung_ungueltig : 21|1@1+ (1.0,0.0) [0.0|1] ""  Vector__XXX
 SG_ KBI_Handbremse : 23|1@1+ (1.0,0.0) [0.0|1] ""  Vector__XXX
 SG_ KBI_V_Digital : 24|9@1+ (1,0) [0|511] ""  Vector__XXX
 SG_ KBI_PLA_in_Anzeige : 33|1@1+ (1.0,0.0) [0.0|1] ""  BCM1
 SG_ KBI_Anzeigefehler_NV : 34|1@1+ (1.0,0.0) [0.0|1] ""  Vector__XXX
 SG_ KBI_Anzeigestatus_LIM : 35|2@1+ (1.0,0.0) [0.0|3] ""  Vector__XXX
 SG_ KBI_ARA_in_Anzeige : 37|1@1+ (1.0,0.0) [0.0|1] ""  BCM1
 SG_ KBI_Taster_Lift : 38|1@1+ (1.0,0.0) [0.0|1] ""  Vector__XXX
 SG_ KBI_Taster_Fahrwerk : 39|1@1+ (1.0,0.0) [0.0|1] ""  Vector__XXX
 SG_ KBI_angez_Geschw : 48|10@1+ (0.32,0) [0.00|325.12] "Unit_KiloMeterPerHour"  Vector__XXX
 SG_ KBI_Einheit_Tacho : 58|1@1+ (1.0,0.0) [0.0|1] ""  Vector__XXX
 SG_ KBI_Konsistenz_ACC : 59|1@1+ (1.0,0.0) [0.0|1] ""  Vector__XXX
 SG_ KBI_Fehler_Anzeige_ACC : 60|1@1+ (1.0,0.0) [0.0|1] ""  Vector__XXX
 SG_ KBI_Anzeigefehler_SWA : 61|2@1+ (1.0,0.0) [0.0|3] ""  Vector__XXX
 SG_ KBI_Systemstatus : 63|1@1+ (1.0,0.0) [0.0|1] ""  Vector__XXX

BO_ 1719 Kombi_02: 8 Gateway
 SG_ KBI_Kilometerstand : 0|20@1+ (1,0) [0|1048573] "Unit_KiloMeter"  VAS_R
 SG_ KBI_Standzeit_02 : 20|17@1+ (1,0) [0|131068] "Unit_Secon"  BCM1,Klima_MSB
 SG_ KBI_LVDS_Lock : 37|1@1+ (1.0,0.0) [0.0|1] ""  Vector__XXX
 SG_ KBI_Reserve_Warnung_Sek : 38|1@1+ (1.0,0.0) [0.0|1] ""  Vector__XXX
 SG_ KBI_RDK_Kalibrier_Anf : 39|1@1+ (1.0,0.0) [0.0|1] ""  Vector__XXX
 SG_ KBI_Inhalt_Tank : 40|7@1+ (1,0) [0|125] "Unit_Liter"  Vector__XXX
 SG_ KBI_FStatus_Tank : 47|1@1+ (1.0,0.0) [0.0|1] ""  Vector__XXX
 SG_ KBI_aktive_Laengsfunktion : 48|3@1+ (1.0,0.0) [0.0|7] ""  Vector__XXX
 SG_ KBI_GRA_im_ACC : 53|1@1+ (1.0,0.0) [0.0|1] ""  Vector__XXX
 SG_ KBI_Oelwechsel_durchgefuehrt : 54|1@1+ (1.0,0.0) [0.0|1] ""  Vector__XXX
 SG_ KBI_QBit_Aussen_Temp_gef : 55|1@1+ (1.0,0.0) [0.0|1] ""  BCM1,Klima_MSB
 SG_ KBI_Aussen_Temp_gef : 56|8@1+ (0.5,-50) [-50.0|75.0] "Unit_DegreCelsi"  BCM1,Klima_MSB,Lift_VA,VAS_L,VAS_R

BO_ 2549874958 KS_BCM1_Req: 8 Gateway
 SG_ KS_BCM1_Req_Data : 0|64@1+ (1.0,0.0) [0.0|18446744073709551615] ""  BCM1

BO_ 2550006030 KS_BCM1_Resp: 8 BCM1
 SG_ KS_BCM1_Resp_Data : 0|64@1+ (1.0,0.0) [0.0|18446744073709551615] ""  Gateway

BO_ 2549875140 KS_VAS_L_Req: 8 Gateway
 SG_ KS_VAS_L_Req_Data : 0|64@1+ (1,0) [0|1] ""  VAS_L

BO_ 2550006212 KS_VAS_L_Resp: 8 VAS_L
 SG_ KS_VAS_L_Resp_Data : 0|64@1+ (1,0) [0|1] ""  Gateway

BO_ 2549875141 KS_VAS_R_Req: 8 Gateway
 SG_ KS_VAS_R_Req_Data : 0|64@1+ (1,0) [0|1] ""  VAS_R

BO_ 2550006213 KS_VAS_R_Resp: 8 VAS_R
 SG_ KS_VAS_R_Resp_Data : 0|64@1+ (1,0) [0|1] ""  Gateway

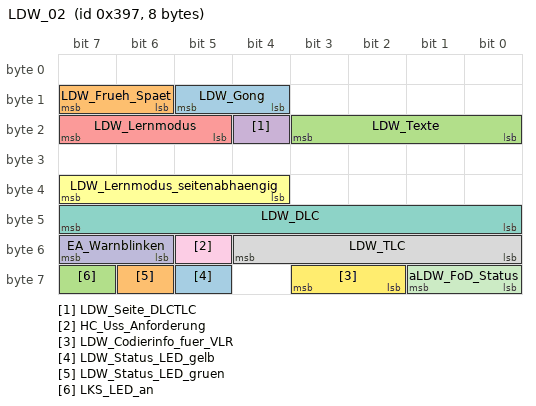
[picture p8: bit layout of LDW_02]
BO_ 919 LDW_02: 8 Gateway
 SG_ LDW_Gong : 12|2@1+ (1.0,0.0) [0.0|3] ""  Vector__XXX
 SG_ LDW_Frueh_Spaet : 14|2@1+ (1.0,0.0) [0.0|3] ""  Vector__XXX
 SG_ LDW_Texte : 16|4@1+ (1.0,0.0) [0.0|15] ""  Vector__XXX
 SG_ LDW_Seite_DLCTLC : 20|1@1+ (1.0,0.0) [0.0|1] ""  Vector__XXX
 SG_ LDW_Lernmodus : 21|3@1+ (1.0,0.0) [0.0|7] ""  Vector__XXX
 SG_ LDW_Lernmodus_seitenabhaengig : 36|4@1+ (1.0,0.0) [0.0|15] ""  Vector__XXX
 SG_ LDW_DLC : 40|8@1+ (0.01,-1.25) [-1.25|1.25] "Unit_Meter"  Vector__XXX
 SG_ LDW_TLC : 48|5@1+ (0.1,0) [0.0|3.0] "Unit_Secon"  Vector__XXX
 SG_ HC_Uss_Anforderung : 53|1@1+ (1.0,0.0) [0.0|1] ""  BCM1
 SG_ EA_Warnblinken : 54|2@1+ (1.0,0.0) [0.0|3] ""  Vector__XXX
 SG_ aLDW_FoD_Status : 56|2@1+ (1.0,0.0) [0.0|3] ""  Vector__XXX
 SG_ LDW_Codierinfo_fuer_VLR : 58|2@1+ (1.0,0.0) [0.0|3] ""  Vector__XXX
 SG_ LDW_Status_LED_gelb : 61|1@1+ (1.0,0.0) [0.0|1] ""  Vector__XXX
 SG_ LDW_Status_LED_gruen : 62|1@1+ (1.0,0.0) [0.0|1] ""  Vector__XXX
 SG_ LKS_LED_an : 63|1@1+ (1.0,0.0) [0.0|1] ""  BCM1

BO_TX_BU_ 1646 :BCM1,Klima_MSB;
BO_TX_BU_ 1649 :BCM1,Klima_MSB;
BO_TX_BU_ 1608 :BCM1,Klima_MSB;
BO_TX_BU_ 949 :BCM1,Klima_MSB;
BO_TX_BU_ 1640 :BCM1,Klima_MSB;
BO_TX_BU_ 1441 :BCM1,Klima_MSB;
BO_TX_BU_ 2589283469 :BCM1,Klima_MSB;
BO_TX_BU_ 2589283621 :BCM1,Klima_MSB;
BO_TX_BU_ 1717 :BCM1,Klima_MSB;
BO_TX_BU_ 1513 :BCM1,Klima_MSB;
BO_TX_BU_ 1295 :BCM1,Klima_MSB;
BO_TX_BU_ 2589283474 :BCM1,Klima_MSB;
CM_ BO_ 960 "MQB";
CM_ BO_ 1646 "ab MQB 7.3";
CM_ BO_ 1663 "Klima";
CM_ BO_ 949 "ab MQB 7.4";
CM_ BO_ 1640 "ab MQB IS-4";
CM_ BO_ 1712 "D4 und B8-PA

1:1 LIN-CAN Botschaft, nur bei Kl.15 EIN gesendet";
CM_ BO_ 1505 "ab MQB 7.3";
CM_ BO_ 1717 "ab D4 gültig  --  geänderter Wertebereich und Signalnamen
1:1 LIN-CAN Botschaft vom BCM1, nur bei Kl.15 EIN gesendet";
CM_ BO_ 779 "MQB";
CM_ BO_ 919 "ab MQB ohne CHK/BZ, LDW_SW_Warnung_links/rechts, KD-Fehler und mit Zyklus 100ms";

CM_ SG_ 960 BCM_Ausparken_Betrieb "Anforderung zur erneuten Lampenaufprüfung und Anzeige von Warnhinweisen nach einem pilotierten Ausparkvorgang (Trigger: fallende Flanke)";
CM_ SG_ 960 BCM_Remotestart_Betrieb "Zeigt den Status des RemoteStarts an, d.h. KL15_RSt ist aktiviert und der Motorlauf ist im RSt-Betrieb aktiv.";
CM_ SG_ 960 BCM_Remotestart_KL15_Anf "Zeigt den Status der Aktivierung der KL15_RST durch das BCM an.";
CM_ SG_ 960 BCM_Remotestart_MO_Start "Nachdem das BCM die Remotestart MSG Freigabe sicher erkannt hat, fordert das BCM wiederum über dieses Signal vom MSG einen Motorstart durchzuführen.";
CM_ SG_ 960 Klemmen_Status_01_BZ "4bit Botschaftszaehler; wird in jeder Sendebotschaft inkrementiert";
CM_ SG_ 960 Klemmen_Status_01_CRC "Für MLB:
'Berechnung siehe Lastenheft 'Kommunikationsabsicherung für FlexRay und CAN''

Ab MQB und MLBevo:
'Berechnung siehe Lastenheft 'End-to-End Kommunikationsabsicherung''

Endwerte siehe Begleitdokument 'S-PDU Kennungsfolgen'";
CM_ SG_ 960 KST_Fahrerhinweis_1 "Signalisierung Fahrerhinweis 1 der Klemmensteuerung an das Kombi";
CM_ SG_ 960 KST_Fahrerhinweis_2 "Signalisierung Fahrerhinweis 2 der Klemmensteuerung an das Kombi";
CM_ SG_ 960 KST_Fahrerhinweis_4 "Signalisierung Fahrerhinweis 4 der Klemmensteuerung an das Kombi";
CM_ SG_ 960 KST_Fahrerhinweis_5 "Anzeigesignal für RemoteStart";
CM_ SG_ 960 KST_Fahrerhinweis_6 "Signal aktiviert die Kombi-Anzeigeinstrumente (Drehzahl, Tankinhalt, Kühlmitteltemperatur) während aktiviertem RemoteStart-Betrieb";
CM_ SG_ 960 KST_Warn_P1_ZST_def "Kombi Prio Warnung Klemmensteuerung 
Zündschloß defekt, Service aufsuchen!";
CM_ SG_ 960 KST_Warn_P2_ZST_def "Kombi Prio Warnung Klemmensteuerung
Zündschloß defekt!
";
CM_ SG_ 960 RSt_Fahrerhinweise "Über das Signal fordert das BCM Fahrerhinweise im Kombi für die Funktion RemoteStart an.";
CM_ SG_ 960 ZAS_Kl_15 "Klemme 15: Zuendung (SW-Kl.15)
";
CM_ SG_ 960 ZAS_Kl_50_Startanforderung "Klemme 50: Startwunsch Fahrer
";
CM_ SG_ 960 ZAS_Kl_Infotainment "Separate Klemmeninformation für das Infotainment. Signal entspricht im wesentlichen einer Klemme S Information, kann aber über einen Vor - bzw. Nachlauf zu Klemme S verfügen. 
Ein konkreter Anwendungsfall für einen Nachlauf ist die Abschaltung der Klemme";
CM_ SG_ 960 ZAS_Kl_S "Klemme S: S-Kontakt (Schluessel steckt)
";
CM_ SG_ 960 ZAS_Kl_X "Klemme 75
";

CM_ SG_ 1420 Klemmen_Steuerung_01_BZ "4bit Botschaftszaehler; wird in jeder Sendebotschaft inkrementiert";
CM_ SG_ 1420 Klemmen_Steuerung_01_CRC "Ab MQB und MLBevo:
'Berechnung siehe Lastenheft 'End-to-End Kommunikationsabsicherung''

Endwerte siehe Begleitdokument 'S-PDU Kennungsfolgen'";
CM_ SG_ 1420 KST_Anf_Klemmenfreigabe_ELV "Klemmensteuerung fordert Klemmen-Freigabe durch die ELV an.";
CM_ SG_ 1420 KST_Anf_ZV_Verriegelung "Neuer Verriegelungstrigger für die ZV nach der automatischen Klemmenabschaltung.

Wird bei Kessyfahrzeugen mit StartStop ein aktiver Stop-Mode und Fahrerverlassen erkannt, startet ein 30 Sekunden-Timer. Innerhalb dieser 30 Sekunden hat der Fahrer die Mö";
CM_ SG_ 1420 KST_aut_Abschaltung_Zuendung "Falls bei eingeschalteter Zündung das Abblendlicht aktiv war, muss nach der automatischen Abschaltung der Kl_15 & Kl_S, dass Standlicht aktiv bleiben. Das Signal sendet die Information, dass eine automatische Abschaltung der Kl_15 und Kl_S erfogt.";
CM_ SG_ 1420 KST_Txt_Komfortabschaltung "Dieses Signal fordert im Kombi die Meldung an, die den Fahrer über die ausgeführte automatische Zündungsabschaltung informiert. Signal wird für10s gesendet.";
CM_ SG_ 1420 KST_Txt_P_Gang "Text: 'Wählhebel in Position P bringen!'";
CM_ SG_ 1420 KST_Txt_Panikabschaltung "Text: 'Notabschaltung''";
CM_ SG_ 1420 KST_Unterdr_Zuendungsmeldung "Bei aktivem Signal soll die Zündungsmeldung durch das Kombi unterdrückt werden.";
CM_ SG_ 1420 KST_ZAT_betaetigt "Zündanlass-Taster (ZAT) betätigt";
CM_ SG_ 1420 Relais_VoKo_angesteuert "Signal zur Rückmeldung, ob das Relais für die Verbraucher von erweiterte Voko / RemoteStart angesteuert wird.";
CM_ SG_ 1420 RSt_Anforderung_HMS "Anforderung vom RSt (Remote Start) an das HMS (Haltemanagement System)";

CM_ SG_ 1646 KL_Anf_AussenspiegelHzg "Anforderung Außenspiegelheizung seitens Klimafunktion (z.B. bei Erweiterter VoKo)";
CM_ SG_ 1646 KL_BCmE_Livetip_Freigabe "Status der Klimaanlage. 
Zeigt an, ob der Livetip 'Fenster schließen wegen Ineffizienz Klimaanlage' sinvollerweise angezeigt werden soll

MQB: nur Audi relevant";
CM_ SG_ 1646 KL_ErwVK_Anf "Erweiterte Voko angefordertert / aktiv";
CM_ SG_ 1646 KL_ErwVK_Zusatzrelais "Steuerung Zusatzrelais für Erweiterte Voko";
CM_ SG_ 1646 KL_FSH_Automatikbetrieb "Ermöglicht eine Unterscheidung von Anforderung FSH durch Kundenwunsch und Anforderung FSH durch Regelung des Klimasteuergeräts.
Das Signal liegt als Pegel an.";
CM_ SG_ 1646 KL_Geblaese_Fond_Status "Status Geblaese









";
CM_ SG_ 1646 KL_Geblaese_Status "Status Geblaese









";
CM_ SG_ 1646 KL_Heizkreisventilstellung "Bei MQB PHEV: Stellung Heizkreisventil Motor";
CM_ SG_ 1646 KL_HYB_ASV_hinten_schliessen_Anf "Anforderung der Klima an das BMS, das Absperrventil des Kältemittelkreislaufs zur Batteriekühlung zu schliessen";
CM_ SG_ 1646 KL_HYB_ASV_vorne_schliessen_Anf "Anforderung der Klima an das BMS, das Absperrventil des Kältemittelkreislaufs der Klimaanlage zu schliessen";
CM_ SG_ 1646 KL_I_Geblaese_Fond "Stromaufnahme Gebläse Heck";
CM_ SG_ 1646 KL_Innen_Temp "Innentemperatur

";
CM_ SG_ 1646 KL_Kompressorkupplung "Signal zur Aktivierung/Deaktivierung der Kompressorkupplung";
CM_ SG_ 1646 KL_Magnetventil "Anforderung des Bypassventils.";
CM_ SG_ 1646 KL_Restwaerme_aktiv "Signal zur Aktivierung/Deaktivierung der Wasserpumpe bei Restwärme; 
reduzierte IRÜ Empfindlichkeit";
CM_ SG_ 1646 KL_SIH_LEH_Verteilung_VL "Vom Kunden eingestellte Aufteilung der Heizleistung auf Sitzfläche und Lehnefläche für Sitz vorne links";
CM_ SG_ 1646 KL_SIH_LEH_Verteilung_VR "Vom Kunden eingestellte Aufteilung der Heizleistung auf Sitzfläche und Lehnefläche für Sitz vorne rechts";
CM_ SG_ 1646 KL_SIH_LEL_Verteilung_VL "Vom Kunden eingestellte Aufteilung der Lüftungsleistung auf Sitzfläche und Lehnenfläche für Sitz vorne links";
CM_ SG_ 1646 KL_SIH_LEL_Verteilung_VR "Vom Kunden eingestellte Aufteilung der Lüftungsleistung auf Sitzfläche und Lehnenfläche für Sitz vorne rechts";
CM_ SG_ 1646 KL_Solarluefter_aktiv "Betriebsstatus Solarluefter
";
CM_ SG_ 1646 KL_Status_Beduftung "Status der Beduftung";
CM_ SG_ 1646 KL_Status_Ionisator_Front "Status des Ionisator Front";
CM_ SG_ 1646 KL_STH_aktiv "Betriebsstatus Standheizung
";
CM_ SG_ 1646 KL_STH_Ansteuerung "Ansteuerung STH

";
CM_ SG_ 1646 KL_STH_Betriebsdauer "Betriebsdauer STH";
CM_ SG_ 1646 KL_STH_Timer_Status "Status des Standheizungstimers (für VW621 initial zur Übermittelung der Information von KlimaMSB zu Kombi)
Zur Anzeige im Kombi für 10 Sekunden nach Kl.15 aus;";
CM_ SG_ 1646 KL_STL_aktiv "Betriebsstatus Standlueftung
";
CM_ SG_ 1646 KL_Umluft_Taste "Betaetigung Umlufttaste
";
CM_ SG_ 1646 KL_WaPu "Ansteuerung der Standheizungswasserpumpe";

CM_ SG_ 1663 KL_Absperrventil_Fond "nur im D4 verwendet";
CM_ SG_ 1663 KL_Fond_li_reduziert "Vorhalt fuer VW, nicht B8";
CM_ SG_ 1663 KL_Fond_re_reduziert "Vorhalt fuer VW, nicht B8";
CM_ SG_ 1663 KL_Fondbed_vorne_aktiv "Fondbedienung von vorne
Im D4 nicht unterstützt    siehe Klima_07, Synchronisierunganforderung
";
CM_ SG_ 1663 KL_Gebl_Verst_Abs_Modus "Gebläseverstellung im Absolutmodus";
CM_ SG_ 1663 KL_Geblaesespg_Fond "Geläsespannung Fond";
CM_ SG_ 1663 KL_Heizverbraucher_aus "Signal ans Fondgerät, alle Heizverbraucher zu deaktivieren";
CM_ SG_ 1663 KL_Heizverbraucher_Notaus "Signal ans Fondgerät, alle Heizverbraucher zu deaktivieren";
CM_ SG_ 1663 KL_ICO2_Sensor_defekt "Funktionszustand vom CO2 Sensor";
CM_ SG_ 1663 KL_Mod_Display_li "Modus des Display links";
CM_ SG_ 1663 KL_Mod_Display_re "Modus des Display rechts
";
CM_ SG_ 1663 KL_SH_HL_Lastabschaltung "Abschaltung der Sitzheizung hinten links wegen BEM, auch Taktung möglich
";
CM_ SG_ 1663 KL_SH_HR_Lastabschaltung "Abschaltung der Sitzheizung hinten rechts wegen BEM, auch Taktung möglich
";
CM_ SG_ 1663 KL_Sollausblastemp_HL "Sollausblastemperatur hinten links (0°C .. 85°C)

Vorhalt";
CM_ SG_ 1663 KL_Sollausblastemp_HR "Sollausblastemperatur hinten rechts (0°C .. 85°C)

Vorhalt";
CM_ SG_ 1663 KL_Umluft "Sollwert für Umluftklappe Fondraum";

CM_ SG_ 1649 KL_Betriebsmodus_FH "Synchronisation des Betriebsmodus zwischen Front und Fond";
CM_ SG_ 1649 KL_Stopp_Wiederstart_Anz_01 "Dieses Signal gibt die detaillierte Begründung für eine Stoppverbot-/Wiederstartanfrage der Klima-SG an.";
CM_ SG_ 1649 KL_Stopp_Wiederstart_Anz_02 "Dieses Signal gibt die detaillierte Begründung für eine Stoppverbot-/Wiederstartanfrage der Klima-SG an.";
CM_ SG_ 1649 KL_Stopp_Wiederstart_Anz_03 "Dieses Signal gibt die detaillierte Begründung für eine Stoppverbot-/Wiederstartanfrage der Klima-SG an.";
CM_ SG_ 1649 KL_Stopp_Wiederstart_Anz_04 "Dieses Signal gibt die detaillierte Begründung für eine Stoppverbot-/Wiederstartanfrage der Klima-SG an.";
CM_ SG_ 1649 KL_Stopp_Wiederstart_Anz_05 "Dieses Signal gibt die detaillierte Begründung für eine Stoppverbot-/Wiederstartanfrage der Klima-SG an.";
CM_ SG_ 1649 KL_Stopp_Wiederstart_Anz_06 "Dieses Signal gibt die detaillierte Begründung für eine Stoppverbot-/Wiederstartanfrage der Klima-SG an.";
CM_ SG_ 1649 KL_Stopp_Wiederstart_Anz_07 "Dieses Signal gibt die detaillierte Begründung für eine Stoppverbot-/Wiederstartanfrage der Klima-SG an.";
CM_ SG_ 1649 KL_Stopp_Wiederstart_Anz_08 "Dieses Signal gibt die detaillierte Begründung für eine Stoppverbot-/Wiederstartanfrage der Klima-SG an.";
CM_ SG_ 1649 KL_Stopp_Wiederstart_Anz_09 "Dieses Signal gibt die detaillierte Begründung für eine Stoppverbot-/Wiederstartanfrage der Klima-SG an.";
CM_ SG_ 1649 KL_Stopp_Wiederstart_Anz_Std1 "Dieses Signal gibt die detaillierte Begründung für eine Stoppverbot-/Wiederstartanfrage der Klima-SG an.";
CM_ SG_ 1649 KL_Stopp_Wiederstart_Anz_Std2 "Dieses Signal gibt die detaillierte Begründung für eine Stoppverbot-/Wiederstartanfrage der Klima-SG an.";
CM_ SG_ 1649 KL_ZZ_Betriebsmodus "Betriebsdauerberechnung anhand Aussentemperaturauswertung mit Faktor 'ZZ_Betriebsmodus'";
CM_ SG_ 1649 KL_ZZ_Minute "Zielzeittimeranzeige im Display der Funkfernbedienung (Minute); Initwert ist der zuletzt gültige Wert";
CM_ SG_ 1649 KL_ZZ_Monat "Zielzeittimeranzeige im Display der Funkfernbedienung (Datum, Monat); Initwert ist der zuletzt gültige Wert";
CM_ SG_ 1649 KL_ZZ_Status_Timer "Timerstatusanzeige im Display der Funkfernbedienung (Timer aktiv/n.aktiv)";
CM_ SG_ 1649 KL_ZZ_Stunde "Zielzeittimeranzeige im Display der Funkfernbedienung (Stunde); Initwert ist der zuletzt gültige Wert";
CM_ SG_ 1649 KL_ZZ_Tag "Zielzeittimeranzeige im Display der Funkfernbedienung (Datum, Tag); Initwert ist der zuletzt gültige Wert";

CM_ SG_ 1608 KL_Befehlszaehler_FH "Befehlszähler zur Synchronisation Front & Fond";
CM_ SG_ 1608 KL_Luftmenge_HL_max "Vorgabe der maximal auswählbaren Gebläsestufe für Zone HL";
CM_ SG_ 1608 KL_Luftmenge_HL_offset "Abweichung der Gebläsespannung bei manueller Gebläsevorgabe zum Arbeitspunkt im Auto-Modus für Zone HL";
CM_ SG_ 1608 KL_Luftmenge_HL_Soll "Sollwertvorgabe für Luftmenge hinten links";
CM_ SG_ 1608 KL_Luftmenge_HR_max "Vorgabe der maximal auswählbaren Gebläsestufe für Zone HR";
CM_ SG_ 1608 KL_Luftmenge_HR_offset "Abweichung der Gebläsespannung bei manueller Gebläsevorgabe zum Arbeitspunkt im Auto-Modus für Zone HR";
CM_ SG_ 1608 KL_Luftmenge_HR_Soll "Sollwertvorgabe für Luftmenge hinten rechts";
CM_ SG_ 1608 KL_SH_HL_Soll "Sollwertvorgabe für Sitzheizung hinten links";
CM_ SG_ 1608 KL_SH_HR_Soll "Sollwertvorgabe für Sitzheizung hinten rechts";
CM_ SG_ 1608 KL_SL_HL_Soll "Sollwertvorgabe für Sitzlüftung hinten links";
CM_ SG_ 1608 KL_SL_HR_Soll "Sollwertvorgabe für Sitzlüftung hinten rechts";
CM_ SG_ 1608 KL_Temp_HL_Soll "Audi  bis   28°C
VW    bis   29,5°C";
CM_ SG_ 1608 KL_Temp_HR_Soll "Audi  bis   28°C
VW    bis   29,5°C";

CM_ SG_ 949 KL_AC_Schalter "AC Schalter
";
CM_ SG_ 949 KL_Anf_KL "Anforderung Kühlerlüfter der Klimaanlage in Prozent

";
CM_ SG_ 949 KL_Ausstattung_Klima "Austtattungsart der Klimabedienung";
CM_ SG_ 949 KL_Charisma_FahrPr "MLBevo: Aktuelles Fahrprogramm des Charisma-Teilnehmers (siehe Systemlastenheft Drive Select)
MQB: Istwert der Kennlinie (siehe Systemlastenheft MQB FPA)";
CM_ SG_ 949 KL_Charisma_Status "Charisma Systemstatus des Charisma-Teilnehmers

Wert 0x3 ist nur für Fahrzeuge ab MQB relevant";
CM_ SG_ 949 KL_Drehz_Anh "Drehzahlanhebung vom Motor angefordert

";
CM_ SG_ 949 KL_el_Zuheizer_Stufe "Vorgabe für Motorsteuergeraet PTC-Stufe; im MLB-B8 und MQB nur Stufe 0...3

";
CM_ SG_ 949 KL_Freilauf_Info "Freilauf Informationssignal von Klima zum Freilaufkoordinator. Klima kann über dieses Signal den Freilauf freigeben, verhindern bzw. explizit anfordern.";
CM_ SG_ 949 KL_Kompressorkupplung_linear "Sollwert zur Ansteuerung der Kompressorkupplung";
CM_ SG_ 949 KL_Last_Kompr "Aktuelles Verlustmoment der Klimaanlage bezogen auf die Kurbelwelle. Wird der Klimakompressor nicht angesteuert, ist das Schleppmoment bezogen auf die Kurbelwelle zu senden.";
CM_ SG_ 949 KL_nachtr_Stopp_Anf "Dieses Signal dient dem Motor als Trigger, dass ein nachträglicher Motorstopp eingeleitet werden kann, wenn es die Bedingungen des StSt Koordinators dies zulassen. ";
CM_ SG_ 949 KL_Spannungs_Anf "Forderung des Klima-SG's zur Spannungsanhebung.";
CM_ SG_ 949 KL_StartStopp_Info "Stopp-Freigabe und Start-Anforderung an den Start-Stopp-Koordinator";
CM_ SG_ 949 KL_T_Charge "Signal für Tastenbetätigung Charge-Taste (SOC Increasing)";
CM_ SG_ 949 KL_Thermomanagement "Stufen des Thermomanagements;
Bei Klemme 15 AUS und erkannten Timeout zum Klimabedienteil (z.B. Klimabedienteil während des Motorsteuergeräte-Kommunikations-Nachlaufs bereits im NM-Zustand ¿Bus Sleep¿)
erfolgt keine Ansteuerung der Wasserpumpe durch die";
CM_ SG_ 949 KL_Variante_Standheizung "Identifikation der Variante der Standheizungen zur Berechnung der energetischen Zielzeit";
CM_ SG_ 949 KL_Vorwarn_Komp_ein "Vorwarnung Kompressor ein; 140ms vorher; Information für Motor zum Aufbau Momentenreserve";
CM_ SG_ 949 KL_Vorwarn_Zuheizer_ein "Vorwarnung Zuheizerbetrieb
";
CM_ SG_ 949 KL_Zustand "Beschreibt den Zustand des Klima-/Heizungsbedienteils. (OFF-Mode Bedienteil)

PAG (MLB): Beschreibt den Zustand des Kompressors";

CM_ SG_ 1640 FSH_Taster "Tasterbetätigung Frontscheibenheizung
";
CM_ SG_ 1640 HSH_Taster "An-/Abforderung Heckscheibenheizung über spezielles Tastersignal
";
CM_ SG_ 1640 KL_Beschlagsgefahr "Beschlagsgefahr auf der Frontscheibe im Bereich des Spiegelfusses. Dient zur präventiven Ansteuerung der  Kamera-Scheibenheizung, um Kamera-Blindheit zu vermeiden
PHEV: volle Leistungsfreigabe 
HV Heizer und HV EKK bei Scheibenbeschlag ";
CM_ SG_ 1640 KL_Geblspng_Fond_Soll "Ausgabe des Sollwertes für die Spannung des Klimagebläsemotores hinten.






";
CM_ SG_ 1640 KL_Geblspng_Soll "Ausgabe des Sollwertes für die Spannung des Klimagebläsemotores vorne.







";
CM_ SG_ 1640 KL_I_Geblaese "Stromaufnahme Gebläse";
CM_ SG_ 1640 KL_Kompressorstrom_soll "Sollvorgabe Klima-Kompressorstrom";
CM_ SG_ 1640 KL_LRH_Stufe "Eingestellte Temperaturstufe der Lenkradheizung";
CM_ SG_ 1640 KL_LRH_Taster "Tasterbetätigung Lenkradheizung";
CM_ SG_ 1640 KL_PTC_Verbauinfo "Im Klima- bzw. Heizungsbedienteil wird der Verbau eines PTCs und dessen elektr. Leistungsklasse codiert";
CM_ SG_ 1640 KL_SIH_Soll_li "Einstellung Sitzheizung Fahrer (0...6)";
CM_ SG_ 1640 KL_SIH_Soll_re "Einstellung Sitzheizung Beifahrer (0...6)";
CM_ SG_ 1640 KL_SIL_Soll_li "Einstellung Sitzlüftung Fahrer (0...6)";
CM_ SG_ 1640 KL_SIL_Soll_re "Einstellung Sitzlüftung Beifahrer (0...6)";
CM_ SG_ 1640 KL_Umluftklappe_Status "Status Umluftklappe";
CM_ SG_ 1640 KL_Zuheizer_Freigabe "Freigabe Zuheizer
";
CM_ SG_ 1640 KRH_Soll_li "Ausgabe des Sollwertes für die Kopfraumheizung links.";
CM_ SG_ 1640 KRH_Soll_re "Ausgabe des Sollwertes für die Kopfraumheizung rechts.";

CM_ SG_ 1441 KL_Frischluftklappe_Status "Aktuelle Position der Frischluftklappe";
CM_ SG_ 1441 KL_PTC_linear_Anf "Kundenanforderung des PTC (linear)";
CM_ SG_ 1441 KL_SIH_LEH_Verteilung_HL "Vom Kunden eingestellte Aufteilung der Heizleistung auf Sitz und Lehne für Sitz hinten links";
CM_ SG_ 1441 KL_SIH_LEH_Verteilung_HR "Vom Kunden eingestellte Aufteilung der Heizleistung auf Sitz und Lehne für Sitz hinten rechts.";
CM_ SG_ 1441 KL_SIH_Stufe_hl "Eingestellte Sitzheizungsstufe hinten links für verteilte Komfortfunktionen";
CM_ SG_ 1441 KL_SIH_Stufe_hr "Eingestellte Sitzheizungsstufe hinten rechts für verteilte Komfortfunktionen";
CM_ SG_ 1441 KL_SIL_LEL_Verteilung_HL "Vom Kunden eingestellte Aufteilung der Lüftungsleistung auf Sitzfläche und Lehnenfläche für Sitz hinten links";
CM_ SG_ 1441 KL_SIL_LEL_Verteilung_HR "Vom Kunden eingestellte Aufteilung der Lüftungsleistung auf Sitzfläche und Lehnenfläche für Sitz hinten rechts";
CM_ SG_ 1441 KL_SIL_Stufe_hl "Eingestellte Sitzlüftungsstufe hinten links für verteilte Komfortfunktionen";
CM_ SG_ 1441 KL_SIL_Stufe_hr "Eingestellte Sitzlüftungsstufe hinten rechts für verteilte Komfortfunktionen";
CM_ SG_ 1441 KL_Temp_Soll_hl "Eingestellte Solltemperatur hinten links für verteilte Komfortfunktionen";
CM_ SG_ 1441 KL_Temp_Soll_hr "Eingestellte Solltemperatur hinten rechts für verteilte Komfortfunktionen";
CM_ SG_ 1441 KL_Temp_Soll_vl "Eingestellte Solltemperatur vorne links für verteilte Komfortfunktionen";
CM_ SG_ 1441 KL_Temp_Soll_vr "Eingestellte Solltemperatur vorne rechts für verteilte Komfortfunktionen";

CM_ SG_ 2589283469 KL_Geblaese_erw "Erwarteter Gebläsestatus im eingeschwungenen Zustand";
CM_ SG_ 2589283469 KL_Geblaese_Fond_erw "Erwarteter Fond-Gebläsestatus im eingeschwungenen Zustand";
CM_ SG_ 2589283469 KL_Heizlstg_Delta_Eingriff "Durch Kundeneingriff erwartete Veränderung der  Heizleistung bei aktuellen klimatischen Bedingungen";
CM_ SG_ 2589283469 KL_Kuehllstg_Delta_Eingriff "Durch Kundeneingriff erwartete Veränderung der  Kühlleistung bei aktuellen klimatischen Bedingungen";
CM_ SG_ 2589283469 KL_Tempklappe_Fond "Sollwert der Temperaturklappe Fond";
CM_ SG_ 2589283469 KL_Tempklappe_li "Sollwert der Temperaturklappe links (2 zonig)
Sollwert der Temperaturklappe (1-zonig)";
CM_ SG_ 2589283469 KL_Tempklappe_re "Sollwert der Temperaturklappe rechts";
CM_ SG_ 2589283469 KL_Verdampferleistung "Ist-Kühlleistung am Verdampfer
Bei KL_Verdampferleistung_Faktor = 1 wird der Signalwert mit dem Faktor 2 multipliziert.";
CM_ SG_ 2589283469 KL_Verdampferleistung_Faktor "Faktor für Signal KL_Verdampferleistung, 
Bei Signalwert 1 wird das Signal KL_Verdampferleistung mit dem Faktor 2 Multipliziert";
CM_ SG_ 2589283469 KL_VK_Anf "Starten einer Standklimatisierung ausgehend von der Climatronic Richtung Lademanagment.";
CM_ SG_ 2589283469 KL_Vorkond_Strategie "Strategie der Vorkonditionierung des Innenraums";

CM_ SG_ 2589283621 KL_ACmax_Aktiv "Funktion ACmax durch Kundeneingriff aktiviert";
CM_ SG_ 2589283621 KL_Defrost_Aktiv "Funktion Defrost durch Kundeneingriff aktiviert";
CM_ SG_ 2589283621 KL_ECO_Aktiv "Funktion Eco durch Kundeneingriff aktiviert";
CM_ SG_ 2589283621 KL_ECO_PRO_Aktiv "Funktion ECO-PRO durch Kundeneingriff aktiviert";
CM_ SG_ 2589283621 KL_Eps_Innen "mittlerer Wert der Klima Regelabweichung";
CM_ SG_ 2589283621 KL_FlHz_Soll_HL "Sollwertvorgabe für Flächenheizung hinten links";
CM_ SG_ 2589283621 KL_FlHz_Soll_HR "Sollwertvorgabe für Flächenheizung hinten rechts";
CM_ SG_ 2589283621 KL_FlHz_Soll_VL "Sollwertvorgabe für Flächenheizung vorne links";
CM_ SG_ 2589283621 KL_FlHz_Soll_VR "Sollwertvorgabe für Flächenheizung vorne rechts";
CM_ SG_ 2589283621 KL_Kundeneingriff_Geblaese "Manueller Kundeneingriff in die Geblaeseregelung";
CM_ SG_ 2589283621 KL_NV_Energie_Anf "Benötigte Energie (12V) für die Erweiterte Vorkonditionierung";
CM_ SG_ 2589283621 KL_QBit_Sonnenintensitaet "Gültigkeitsbit für Signal KL_Sonenintensität
Gesetzt bei Ersatzwert, Init oder Fehler.";
CM_ SG_ 2589283621 KL_Sonnenintensitaet "gemittelte eingestrahlte Leistung in W/m2";
CM_ SG_ 2589283621 KL_Status_Klimastil "Signal für aktuelles Programm des KBT";
CM_ SG_ 2589283621 KL_Thermischer_Bedarf "Temperierungsbedarf zur Innenraumklimatisierung";
CM_ SG_ 2589283621 KL_Umluft_Connect_status "Umluft Status zum Backend Server";
CM_ SG_ 2589283621 KL_ZR_Anforderung "Anforderung an MIB die Displays zu aktivieren";

CM_ SG_ 992 KL_Fehler_Fussraum_Klappen "Fehler in den Fußraumklappen werden gemeldet";
CM_ SG_ 992 KL_Fehler_Temp_Klappen "Fehler in den Temperaturklappen werden gemeldet";
CM_ SG_ 992 KL_Fehler_Temp_MA_Klappen "Fehler in den MA-Klappen werden gemeldet";
CM_ SG_ 992 KL_Fehler_Umluft "Status Umluftklappe";
CM_ SG_ 992 KL_Fond_Absperrventil "Absperrventil";
CM_ SG_ 992 KL_Fond_Fuss_Temp_hl "Fussraumtemperatur hinten links";
CM_ SG_ 992 KL_Fond_Fuss_Temp_hr "Fussraumtemperatur hinten rechts";
CM_ SG_ 992 KL_Fond_KD_Fehler "Status Kundendienstfehlerspeichereinträge

";
CM_ SG_ 992 KL_MA_Temp_hl "Mannanstroemer hinten links Temperatur";
CM_ SG_ 992 KL_MA_Temp_hr "Mannanstroemer hinten rechts Temperatur";
CM_ SG_ 992 KL_RAB "Risiko-Abschätzungs- und Bewertungs-Bit";
CM_ SG_ 992 KL_SH_Soll_hl "Einstellung Sitzheizung hinten links (0...6)";
CM_ SG_ 992 KL_SH_Soll_hr "Einstellung Sitzheizung hinten rechts (0...6)";
CM_ SG_ 992 KL_SIH_Takt_hl "Ein-Aus Taktung Sitzheizung hinten links";
CM_ SG_ 992 KL_SIH_Takt_hr "Ein-Aus Taktung Sitzheizung hinten rechts";
CM_ SG_ 992 KL_SL_Soll_hl "Einstellung Sitzlüftung hinten links (0...6)";
CM_ SG_ 992 KL_SL_Soll_hr "Einstellung Sitzlüftung hinten rechts (0...6)";

CM_ SG_ 1712 FS_ResponseError "siehe LIN2.0-Specification
(Darf nicht über ein Fehlergueltigkeitsbit abgesichtert werden!)";

CM_ SG_ 1505 BCM1_Aussen_Temp_ungef "ungefilterter Wert des Aussentemperatursensors
";
CM_ SG_ 1505 BCM1_FStatus_Aussentemp_ungef "Fehlerstatus für Aussentemperatur (Kombianzeige)";
CM_ SG_ 1505 BCM1_Kompressorstrom_ist "IST-Strom vom Klima-Kompressor";
CM_ SG_ 1505 BCM1_OBD_FStatus_ATemp "Fehlerstatus Umgebungstemperatursensor (OBD relevanter Sensor)
";
CM_ SG_ 1505 BCM1_PTC_stufig_Status "Status des BCM1-Heizverbrauchers PTC (stufig)";
CM_ SG_ 1505 BCM_Heizungsabsperrventil_Status "Das Signal beschreibt den Zustand des Heizungsabsperrventils, welches als Portexpander vom BCM1 elektrisch angesteuert wird.";
CM_ SG_ 1505 BCM_Heizungspumpe_Status "Das Signal beschreibt den Zustand der Heizungspumpe, welche als Portexpander vom BCM1 elektrisch angesteuert wird.";
CM_ SG_ 1505 BCM_Kompressorkupplung_Status "Das Signal beschreibt den Zustand der Klimakompressorkupplung, welche als Portexpander vom BCM1 elektrisch angesteuert wird.";

CM_ SG_ 1717 FSA_HW "Hardwarestand";
CM_ SG_ 1717 FSA_Luftfeuchte_rel "Maximaler Feuchtebereich bis 126% für theoretisch errechnete Feuchtewerte des Sensors. Signalwerte >100% bedeuten  rel. Feuchte = 100%";
CM_ SG_ 1717 FSA_ResponseError "siehe LIN2.0-Specification
(Darf nicht über ein Fehlergueltigkeitsbit abgesichtert werden!)";
CM_ SG_ 1717 FSA_Sensorheizung_Status "Status der Heizung im Feuchteelement (z.B. SHT10).
0 (=inaktiv) auch bei nicht verbaut";
CM_ SG_ 1717 FSA_SW "Softwarestand";
CM_ SG_ 1717 FSA_Taupunkt "'Init' falls nicht verbaut";
CM_ SG_ 1717 FSA_Temp_Luft "gemessene Temperatur im Luftstrom (z.B. NTC am Sensor)
'Init' falls nicht verbaut
(+61°C bedeutet: Temp_Luft > 60,9°C !)";

CM_ SG_ 1513 AAU_Geblaese "Ansteuergrad des Gebläses";
CM_ SG_ 1513 DS_Kaeltemittel_P "Drucksensor Kältemittel Druck, das Signal wird bei Kl.15 AUS mit dem letzten empfangenen Wert gesendet";
CM_ SG_ 1513 DS_Status "Status des Drucksensors (= LIN-Slave BCM1);
bei Kl.15 AUS wird für 4s noch der letzte Wert gesendet, danach wird das Signal mit dem Wert 3 (= Fehler) gesendet";
CM_ SG_ 1513 ION_Status_LED "Status Funktions LED";
CM_ SG_ 1513 ION_Status_Taster "Status Kundenwunsch (Bedientaster) Ionisator";

CM_ SG_ 1295 KL_Heizbedarf "Bedarf an Heizmenge für Innenraumklimatisierung";
CM_ SG_ 1295 KL_Heizenergie_instat_pred "Erwartete thermische Energie für den instationären Heizbetrieb bis zum Übergang in den stationären Betrieb";
CM_ SG_ 1295 KL_Heizleistg_stat_erw "Erwartete thermische Heizleistungsaufnahme für den stationären Klimabetrieb bei aktuellen klimatischen Bedingungen";
CM_ SG_ 1295 KL_Kuehlbedarf "Bedarf an Kühlmenge für Innenraumklimatisierung";
CM_ SG_ 1295 KL_Kuehlenergie_instat_pred "Erwartete thermische Energie für den instationären Kühlbetrieb bis zum Übergang in den stationären Betrieb";
CM_ SG_ 1295 KL_Kuehlleistg_stat_erw "Erwartete thermische Kühlleistungsaufnahme für den stationären Klimabetrieb bei aktuellen klimatischen Bedingungen";
CM_ SG_ 1295 KL_Leistungspriorisierung "Priorisierungsvorgaben";
CM_ SG_ 1295 KL_PTC_ein "PTC Aus/Ein";
CM_ SG_ 1295 KL_Verdampfertemperatur "Istwert der Verdampfertemperatur";

CM_ SG_ 2589283474 KL_Eps_Innen "mittlerer Wert der Klima Regelabweichung";
CM_ SG_ 2589283474 KL_Temp_vor_Verdampfer "Ist Lufttemperatur vor Verdampfer";
CM_ SG_ 2589283474 KL_Tempklappe_Fond_li "Sollwert der Temperaturklappe Fond links";
CM_ SG_ 2589283474 KL_Tempklappe_Fond_re "Sollwert der Temperaturklappe Fond rechts";

CM_ SG_ 2549088270 BCM1_Abschaltstufe "Funktionseinschränkung aufgrund aktiver Abschaltstufe";
CM_ SG_ 2549088270 BCM1_KD_Fehler "Status Kundendienstfehlerspeichereinträge
";
CM_ SG_ 2549088270 BCM1_KompSchutz "Funktionseinschränkung aufgrund Komponentenschutz aktiv";
CM_ SG_ 2549088270 BCM1_Nachlauftyp "Abgebildet wird die von der Hardware vorgegebene Möglichkeit, die Kommunikation nach Klemme 15 = AUS aufrecht zu erhalten. Es wird ein Init-Wert gesendet.
0 = Kommunikation nur bei KL15=EIN (kein Nachlauf, nicht weckfähig)
1 = Kommunikation nach KL15=AU";
CM_ SG_ 2549088270 BCM1_SNI "Das Signal beinhaltet den Source Node Identifier (Knotenadresse, die auch in der Abbildungsvorschrift zur CAN-ID für die NM-High Botschaft verwendet wird).";
CM_ SG_ 2549088270 BCM1_Transport_Mode "Funktionseinschränkung aufgrund aktivem Transport Mode und/oder Transport Schutz";
CM_ SG_ 2549088270 KN_BCM1_BusKnockOutTimer "Ausgabe des BusKnockOut-Timer in der Knotenbotschaft";
CM_ SG_ 2549088270 NM_BCM1_Lokalaktiv "Zeigt an ob das SG nach Klemme15 AUS und nach entsprechender MAX Aktivzeit noch aktiv war";
CM_ SG_ 2549088270 NM_BCM1_Subsystemaktiv "Zeigt an ob ein Subsystem des SGs nach Klemme15 AUS und nach entsprechender MAX Aktivzeit noch aktiv war";
CM_ SG_ 2549088270 NM_BCM1_Wakeup "enthält die Weckursache; stehen mehrere Weckursachen parallel an, dann muss der kleinste Wert übertragen werden";

CM_ SG_ 2549088272 Gateway_Abschaltstufe "Funktionseinschränkung aufgrund aktiver Abschaltstufe";
CM_ SG_ 2549088272 Gateway_KompSchutz "Funktionseinschränkung aufgrund Komponentenschutz aktiv";
CM_ SG_ 2549088272 Gateway_Matrix_Generation "Signal gibt an welche Matrix-Generation umgesetzt ist";
CM_ SG_ 2549088272 Gateway_Matrix_Version "Signal gibt an welche Matrix-Version des Baukasten umgesetzt ist.
z.B. V.08.xx, das Signal gibt den Wert für xx an";
CM_ SG_ 2549088272 Gateway_Nachlauftyp "Abgebildet wird die von der Hardware vorgegebene Möglichkeit, die Kommunikation nach Klemme 15 = AUS aufrecht zu erhalten. Es wird ein Init-Wert gesendet.
0 = Kommunikation nur bei KL15=EIN (kein Nachlauf, nicht weckfähig)
1 = Kommunikation nach KL15=AU";
CM_ SG_ 2549088272 Gateway_SNI "Das Signal beinhaltet den Source Node Identifier (Knotenadresse, die auch in der Abbildungsvorschrift zur CAN-ID für die NM-High Botschaft verwendet wird).";
CM_ SG_ 2549088272 Gateway_Transport_Mode "Funktionseinschränkung aufgrund aktivem Transport Mode und/oder Transport Schutz";
CM_ SG_ 2549088272 GW_KD_Fehler "Kundendienstfehlerbit Gateway zur Anzeige eines im Gateway abgelegten Fehlerspeichereintrages.";
CM_ SG_ 2549088272 NM_Gateway_Lokalaktiv "Zeigt an ob das SG nach Klemme15 AUS und nach entsprechender MAX Aktivzeit noch aktiv war";
CM_ SG_ 2549088272 NM_Gateway_Subsystemaktiv "Zeigt an ob ein Subsystem des SGs nach Klemme15 AUS und nach entsprechender MAX Aktivzeit noch aktiv war";
CM_ SG_ 2549088272 NM_Gateway_Wakeup "enthält die Weckursache; stehen mehrere Weckursachen parallel an, dann muss der kleinste Wert übertragen werden";

CM_ SG_ 2549088326 KL_KD_Fehler "Status Kundendienstfehlerspeichereinträge

";
CM_ SG_ 2549088326 Klima_Abschaltstufe "Funktionseinschränkung aufgrund aktiver Abschaltstufe";
CM_ SG_ 2549088326 Klima_KompSchutz "Funktionseinschränkung aufgrund Komponentenschutz aktiv";
CM_ SG_ 2549088326 Klima_Nachlauftyp "Abgebildet wird die von der Hardware vorgegebene Möglichkeit, die Kommunikation nach Klemme 15 = AUS aufrecht zu erhalten. Es wird ein Init-Wert gesendet.
0 = Kommunikation nur bei KL15=EIN (kein Nachlauf, nicht weckfähig)
1 = Kommunikation nach KL15=AU";
CM_ SG_ 2549088326 Klima_SNI "Das Signal beinhaltet den Source Node Identifier (Knotenadresse, die auch in der Abbildungsvorschrift zur CAN-ID für die NM-High Botschaft verwendet wird).";
CM_ SG_ 2549088326 Klima_Transport_Mode "Funktionseinschränkung aufgrund aktivem Transport Mode und/oder Transport Schutz";
CM_ SG_ 2549088326 KN_Klima_BusKnockOut "Ausgabe des BusKnockout-Status in der Knotenbotschaft";
CM_ SG_ 2549088326 KN_Klima_BusKnockOutTimer "Ausgabe des BusKnockOut-Timer in der Knotenbotschaft";
CM_ SG_ 2549088326 KN_Klima_ECUKnockOut "Ausgabe des ECUKnockout-Status in der Knotenbotschaft";
CM_ SG_ 2549088326 KN_Klima_ECUKnockOutTimer "Ausgabe des ECUKnockOut-Timer in der Knotenbotschaft";
CM_ SG_ 2549088326 NM_Klima_Lokalaktiv "Zeigt an ob das SG nach Klemme15 AUS und nach entsprechender MAX Aktivzeit noch aktiv war";
CM_ SG_ 2549088326 NM_Klima_Subsystemaktiv "Zeigt an ob ein Subsystem des SGs nach Klemme15 AUS und nach entsprechender MAX Aktivzeit noch aktiv war";
CM_ SG_ 2549088326 NM_Klima_Wakeup "enthält die Weckursache; stehen mehrere Weckursachen parallel an, dann muss der kleinste Wert übertragen werden";

CM_ SG_ 2549088345 Lift_Abschaltstufe "Funktionseinschränkung aufgrund aktiver Abschaltstufe";
CM_ SG_ 2549088345 Lift_KompSchutz "Funktionseinschränkung aufgrund Komponentenschutz aktiv";
CM_ SG_ 2549088345 Lift_Lokalaktiv "Zeigt an ob das SG nach Klemme15 AUS und nach entsprechender MAX Aktivzeit noch aktiv war";
CM_ SG_ 2549088345 Lift_Nachlauftyp "Abgebildet wird die von der Hardware vorgegebene Möglichkeit, die Kommunikation nach Klemme 15 = AUS aufrecht zu erhalten. Es wird ein Init-Wert gesendet.
0 = Kommunikation nur bei KL15=EIN (kein Nachlauf, nicht weckfähig)
1 = Kommunikation nach KL15=AU";
CM_ SG_ 2549088345 Lift_SNI "Das Signal beinhaltet den Source Node Identifier (Knotenadresse, die auch in der Abbildungsvorschrift zur CAN-ID für die NM-High Botschaft verwendet wird).";
CM_ SG_ 2549088345 Lift_Subsystemaktiv "Zeigt an ob ein Subsystem des SGs nach Klemme15 AUS und nach entsprechender MAX Aktivzeit noch aktiv war";
CM_ SG_ 2549088345 Lift_Transport_Mode "Funktionseinschränkung aufgrund aktivem Transport Mode und/oder Transport Schutz";
CM_ SG_ 2549088345 NM_Lift_Wakeup "enthält die Weckursache; stehen mehrere Weckursachen parallel an, dann muss der kleinste Wert übertragen werden";

CM_ SG_ 2549088452 NM_VAS_L_Lokalaktiv "Zeigt an, ob das SG nach Klemme15 AUS noch aktiv war. LAH.DUM.907.T.1_Abschaltungen Ruhestrommgm MLBevo";
CM_ SG_ 2549088452 NM_VAS_L_Wakeup "enthält die Weckursache; stehen mehrere Weckursachen parallel an, dann muss der kleinste Wert übertragen werden";
CM_ SG_ 2549088452 VAS_L_Abschaltstufe "Funktionseinschränkung aufgrund aktiver Abschaltstufe";
CM_ SG_ 2549088452 VAS_L_KD_Fehler "Bei gesetztem Bit ist mindestens ein Kundendienstfehler eingetragen";
CM_ SG_ 2549088452 VAS_L_KompSchutz "Funktionseinschränkung aufgrund Komponentenschutz aktiv";
CM_ SG_ 2549088452 VAS_L_Nachlauftyp "Abgebildet wird die von der Hardware vorgegebene Möglichkeit, die Kommunikation nach Klemme 15 = AUS aufrecht zu erhalten. Es wird ein Init-Wert gesendet.
0 = Kommunikation nur bei KL15=EIN (kein Nachlauf, nicht weckfähig)
1 = Kommunikation nach KL15=AU";
CM_ SG_ 2549088452 VAS_L_SNI "Das Signal beinhaltet den Source Node Identifier (Knotenadresse, die auch in der Abbildungsvorschrift zur CAN-ID für die NM-High Botschaft verwendet wird).";
CM_ SG_ 2549088452 VAS_L_Subsystemaktiv "Zeigt an ob ein Subsystem des SGs nach Klemme15 AUS und nach entsprechender MAX Aktivzeit noch aktiv war";
CM_ SG_ 2549088452 VAS_L_Transport_Mode "Funktionseinschränkung aufgrund aktivem Transport Mode und/oder Transport Schutz";

CM_ SG_ 2549088453 NM_VAS_R_Lokalaktiv "Zeigt an, ob das SG nach Klemme15 AUS noch aktiv war. LAH.DUM.907.T.1_Abschaltungen Ruhestrommgm MLBevo";
CM_ SG_ 2549088453 NM_VAS_R_Wakeup "enthält die Weckursache; stehen mehrere Weckursachen parallel an, dann muss der kleinste Wert übertragen werden";
CM_ SG_ 2549088453 VAS_R_Abschaltstufe "Funktionseinschränkung aufgrund aktiver Abschaltstufe";
CM_ SG_ 2549088453 VAS_R_KD_Fehler "Bei gesetztem Bit ist mindestens ein Kundendienstfehler eingetragen";
CM_ SG_ 2549088453 VAS_R_KompSchutz "Funktionseinschränkung aufgrund Komponentenschutz aktiv";
CM_ SG_ 2549088453 VAS_R_Nachlauftyp "Abgebildet wird die von der Hardware vorgegebene Möglichkeit, die Kommunikation nach Klemme 15 = AUS aufrecht zu erhalten. Es wird ein Init-Wert gesendet.
0 = Kommunikation nur bei KL15=EIN (kein Nachlauf, nicht weckfähig)
1 = Kommunikation nach KL15=AU";
CM_ SG_ 2549088453 VAS_R_SNI "Das Signal beinhaltet den Source Node Identifier (Knotenadresse, die auch in der Abbildungsvorschrift zur CAN-ID für die NM-High Botschaft verwendet wird).";
CM_ SG_ 2549088453 VAS_R_Subsystemaktiv "Zeigt an ob ein Subsystem des SGs nach Klemme15 AUS und nach entsprechender MAX Aktivzeit noch aktiv war";
CM_ SG_ 2549088453 VAS_R_Transport_Mode "Funktionseinschränkung aufgrund aktivem Transport Mode und/oder Transport Schutz";

CM_ SG_ 779 KBI_ABS_Lampe "ABS-Sicherheits-Lampe wurde eingeschaltet.";
CM_ SG_ 779 KBI_Airbag_Lampe "Airbag Sicherheits-Lampe wurde eingeschaltet ";
CM_ SG_ 779 KBI_angez_Geschw "Im Tacho angezeigte Geschwindigkeit inklusive der Voreilung

";
CM_ SG_ 779 KBI_Anzeigefehler_NV "Über dieses Signal teilt das Kombiinstrument dem Nightvision-Steuergerät mit, dass ein Fehler vom Kombiinstrument diagnostiziert wurde, der zur Abschaltung der Nightvision-Funktion führen muss.";
CM_ SG_ 779 KBI_Anzeigefehler_SWA "Signal bezieht sich nur auf die SWA-Lampe, Vorhalt für Kombis mit SWA-Lampe. ";
CM_ SG_ 779 KBI_Anzeigestatus_ACC "Status der ACC-Anzeige im nicht permanenten Displaybereich";
CM_ SG_ 779 KBI_Anzeigestatus_GRA "Anzeigestatus der GRA High Wunschgeschwindigkeitsanzeige im Kombiinstrument.
Bei VW bedeutet 'nicht vorhanden' GRA-low fähig (LED immer verbaut).
0 = nicht vorhanden
1 = Wunschgeschwindigkeits-Anzeigemöglichkeit vorhanden
2 = reserviert
3 = Fehler (B";
CM_ SG_ 779 KBI_Anzeigestatus_LIM "Anzeigestatus der Speedlimiter Wunschgeschwindigkeitsanzeige im Kombiinstrument (permanenter Anzeigebereich)
0 = nicht vorhanden
1 = Wunschgeschwindigkeits-Anzeigemöglichkeit vorhanden
2 = reserviert
3 = Fehler (Botschaftsüberwachung, Timeout, Akustik";
CM_ SG_ 779 KBI_ARA_in_Anzeige "Anzeige von ARA im Kombi aktiv";
CM_ SG_ 779 KBI_BKL_Lampe "Sicherheits-Lampe Bremskontrolle wurde eingeschaltet;
";
CM_ SG_ 779 KBI_Einheit_Tacho "Information, ob es sich um Meilen- oder Kmh-Kombi handelt, Einheit des Tachos entspricht dem Zifferblatt, Grösse ist nicht veränderlich";
CM_ SG_ 779 KBI_ESP_Lampe "ESP-Sicherheits-Lampe wurde eingeschaltet ";
CM_ SG_ 779 KBI_Fehler_Anzeige_ACC "Rückmeldung an ACC, dass mindestens eine der ACC-relevanten Anzeigen -rote Fahrerübernahme, Mitteldisplay, Gong - fehlerhaft sind.";
CM_ SG_ 779 KBI_Handbremse "Handbremsen-Information vom Kombi.
Das Signal bezieht sich ausschließlich auf den Zustand der konventionellen Handbremse.";
CM_ SG_ 779 KBI_im_Stellgliedtest "Kombi im Stellgliedtest, Signal muss eingelesen werden, um Fehlfunktion aufgrund der Bewegung der Stellglieder (Drehzahlmesser, Tacho) des Kombis zu verhindern";
CM_ SG_ 779 KBI_Konsistenz_ACC "Rückmeldung an ACC, dass die Botschaften zur Ansteuerung von Anzeigen nicht bzw. nicht konsistent empfangen wurden (Timeout-, BZ-, CHK- und DLC-Fehler)                                                                                                        ";
CM_ SG_ 779 KBI_Lenkung_Lampe "Sicherheits-Lampe der Lenkung (Lenkhilfe EPS, Audi-Dynamic-Steering ...) wurde eingeschaltet.

0x0 = Lenkungs-Lampe aus
0x1 = Lenkungs-Lampe ein";
CM_ SG_ 779 KBI_MFA_v_Einheit_01 "Einheit der Geschwindigkeit, die vom Fahrer im Car-Menü gewählt wurde. Veränderliche Grösse, im Gegensatz zur Einheit des Tachokranzes.";
CM_ SG_ 779 KBI_NV_in_Anzeige "Das Bit gibt dem NV die Information, ob NV-Bild im Kombi in der Anzeige ist. (Information ist notwendig um Kontrasverstellungen nur dann zuzulassen, wenn der Fahrer das Feedback über das  Kombidisplay bekommt.)";
CM_ SG_ 779 KBI_PLA_in_Anzeige "Das Signal wird als aktive Rückmeldung genutzt, ob die Info des PLA im Kombi angezeigt wird. Wenn nach Anforderung des Displays das Signal zweimal auf 0 ist, wird der Parkvorgang abgebrochen.
Ein Kombi, dass PLA Anzeige nicht unterstützt, schickt dauerha";
CM_ SG_ 779 KBI_SILA_gueltig "Rückmeldeinformation (Bit 1-6) ist gültig";
CM_ SG_ 779 KBI_Systemstatus "Signalisiert erkannte FuSi-relevante Fehler im Kombi
(keinen Ausfall der Akustik oder des Displays)";
CM_ SG_ 779 KBI_Tankwarnung "Fahrer wird gewarnt, dass er den Reservebereich erreicht hat. Fzg.spezifische Warnschwelle";
CM_ SG_ 779 KBI_Tankwarnung_ungueltig "Validiert den Inhalt des Signales KBI_Tankwarnung";
CM_ SG_ 779 KBI_Taster_Fahrwerk "Betätigung Taster 'Fahrwerk' im Kombi";
CM_ SG_ 779 KBI_Taster_Lift "Betätigung Taster 'Lift' im Kombi J1 zur Verarbeitung im Porsche EFP Steuergerät";
CM_ SG_ 779 KBI_V_Digital "Ausgabe der im Kombi angezeigten digitalen Geschwindigkeit.

Einheit ist im KBI_MFA_v_Einheit_01 definiert";
CM_ SG_ 779 KBI_Vorglueh_System_Lampe "Rückmeldung der Vorglühlampe bzw. Motor Systemlampe (MO_Systemlampe) an den Motor (bei Diesel und Otto!). Hardwaremässig gleiche LED im Kombi (EPC- oder Glühwendel), Unterscheidung nur über Ziffernblatt.";
CM_ SG_ 779 Kombi_01_BZ "Botschaft asynchron geroutet. Zählerwert kann springen.";

CM_ SG_ 1719 KBI_aktive_Laengsfunktion "Auswahl, der vom Fahrer gewünschten Laengsregelfunktion";
CM_ SG_ 1719 KBI_FStatus_Tank "Signal wird gesetzt:

a) Während der Fehlerentprellzeit (20 s Entprellung)

b) Bei erkanntem Fehler wird der Tankinhalt während der laufenden KL15-Phase über den 
    Verbrauch zurückgerechnet. In dieser Zeit ist das Bit ebenfalls gesetzt. Nach einem";
CM_ SG_ 1719 KBI_GRA_im_ACC "Gibt den vom Fahrer ausgewählten Modus (ACC oder GRA_im_ACC) an.";
CM_ SG_ 1719 KBI_Inhalt_Tank "Restmenge 2 bzw. 2,5l nicht auflösbar

";
CM_ SG_ 1719 KBI_Kilometerstand "Fehler wird ausgegeben, falls Kilometerstand nicht restaurierbar
";
CM_ SG_ 1719 KBI_LVDS_Lock "Dient zur Synchronisation der Anzeige zwischen Kombi und ZR";
CM_ SG_ 1719 KBI_Oelwechsel_durchgefuehrt "Nach einen Ölwechsel (Service) ist die Ethanol Warmfahrwarnung zu unterdrücken.";
CM_ SG_ 1719 KBI_QBit_Aussen_Temp_gef "0x0 = gültiger Wert
0x1 = Ersatz-, Init- oder Fehlerwert";
CM_ SG_ 1719 KBI_RDK_Kalibrier_Anf "Bei gesetztem Bit soll die RDK die aktuellen Istdrücke zu Solldrücken übernehmen (nur bei Nichtverbau einer Headunit erforderlich).";
CM_ SG_ 1719 KBI_Reserve_Warnung_Sek "Signalisiert die Reservewarnung für die Energiespeicher CNG, LPG, HV-Batterie.
Fahrer wird gewarnt, dass er den Reservebereich erreicht hat. Fzg.spezifische Warnschwelle.";
CM_ SG_ 1719 KBI_Standzeit_02 "Zähler welcher die Standzeit des Motors wiedergibt.
Das Signal beschreibt den Anteil der Motor-Standzeit zwischen Zündung aus und nächstem Motorstart.";

CM_ SG_ 2549874958 KS_BCM1_Req_Data "Komponentenschutz (Funktion 01h). Request mit NA des Slaves.";

CM_ SG_ 2550006030 KS_BCM1_Resp_Data "Komponentenschutz (Funktion 01h). Response mit eigener NA.";

CM_ SG_ 2549875140 KS_VAS_L_Req_Data "Komponentenschutz (Funktion 01h). Request mit NA des Slaves.";

CM_ SG_ 2550006212 KS_VAS_L_Resp_Data "Komponentenschutz (Funktion 01h). Response mit eigener NA.";

CM_ SG_ 2549875141 KS_VAS_R_Req_Data "Komponentenschutz (Funktion 01h). Request mit NA des Slaves.";

CM_ SG_ 2550006213 KS_VAS_R_Resp_Data "Komponentenschutz (Funktion 01h). Response mit eigener NA.";

CM_ SG_ 919 aLDW_FoD_Status "Im CBEV wird aLDW durch FoD geschützt sein und so reicht für Kombi und HUd die PR/Zieldatencontainer basierte Codierung nicht mehr aus.

Aus diesem Grund brauch wir ein separates Signal, dass uns den Freischaltezustand mitteilt.";
CM_ SG_ 919 EA_Warnblinken "Anforderung Warnblinken durch Funktion Emergency Alert";
CM_ SG_ 919 HC_Uss_Anforderung "Ansteuerung der vorderen PLA (VLS, VRS) und APS Sensoren (VL, VR)
0 = Ultraschallsensoren Aus
1 = Ultraschallsensoren An";
CM_ SG_ 919 LDW_Codierinfo_fuer_VLR "Vorhalt LDW-Codierinfo";
CM_ SG_ 919 LDW_DLC "distance to line, Abstand vom Fahrzeug zur Fahrbahnmarkierung
Der Wert gibt die Breite der Restspur zur Linie wieder (Abstand vom Fahrzeugäußerem zur Linie) (Wert POSITIV wenn Fahrzeug in der Spur - Wert NEGATIV wenn Fahrzeug über der Linie)";
CM_ SG_ 919 LDW_Frueh_Spaet "Im MMI eingestellter, aktiver Lenkeingriffszeitpunkt:
0: frueh, frueh aktiv
1: frueh, spaet aktiv
2: spaet, spaet aktiv
3: Fehler";
CM_ SG_ 919 LDW_Gong "Löst ein definiertes akustisches Signal aus.";
CM_ SG_ 919 LDW_Lernmodus "Signal dient zur Ansteuerung von Funktionsanzeigen im Mitteldisplay des Kombiinstruments (neue Funktion im MLB)";
CM_ SG_ 919 LDW_Lernmodus_seitenabhaengig "Signal dient zur Ansteuerung von Funktionsanzeigen im Mitteldisplay des Kombiinstruments für die Seitenabhänige Liniendetektion (neue Funktion ab D4)";
CM_ SG_ 919 LDW_Seite_DLCTLC "Zuordnung auf welche Seite sich LDW_DLC bzw. LDW_TLC beziehen";
CM_ SG_ 919 LDW_Status_LED_gruen " ";
CM_ SG_ 919 LDW_Texte "Bei Anzeige eines Fehlertextes im Kombi ertönt ein akustisches Signal";
CM_ SG_ 919 LDW_TLC "time to line, Zeit bis das Fahrzeug die Fahrbahnmarkierung überquert";
CM_ SG_ 919 LKS_LED_an "Ansteuerung LED auf LKS-Taste im Lichtassistenzmodul";
BA_DEF_REL_ BU_SG_REL_  "GenSigTimeoutTime" INT 0 65535;
BA_DEF_ BO_  "DiagRequest" ENUM "No", "Yes";
BA_DEF_ BO_  "DiagResponse" ENUM "No", "Yes";
BA_DEF_ BO_  "DiagState" ENUM "No", "Yes";
BA_DEF_ BO_  "GenMsgChkConstant" HEX 0 4095;
BA_DEF_ BO_  "GenMsgCycleTime" INT 0 65535;
BA_DEF_ BO_  "GenMsgCycleTimeFast" INT 0 65535;
BA_DEF_ BO_  "GenMsgDelayTime" INT 0 100000;
BA_DEF_ BO_  "GenMsgILSupport" ENUM "No", "Yes";
BA_DEF_ BO_  "GenMsgNrOfRepetition" INT 0 100;
BA_DEF_ BO_  "GenMsgPDUConstants" STRING;
BA_DEF_ BO_  "GenMsgSendType" ENUM "Cyclic", "not_used", "not_used", "not_used", "not_used", "not_used", "not_used", "IfActive", "NoMsgSendType";
BA_DEF_ BO_  "GenMsgStartDelayTime" INT 0 100000;
BA_DEF_ BO_  "NmMessage" ENUM "No", "Yes";
BA_DEF_ BO_  "NmhMessage" ENUM "No", "Yes";
BA_DEF_ BO_  "MsgType" ENUM "Application", "NM ", "NMH", "TP2.0", "ISO-TP ", "BAP", "EID", "KS";
BA_DEF_ BO_  "VAGTP20_API" HEX 0 255;
BA_DEF_ BO_  "VAGTP20_DynConnection" ENUM "No", "Yes";
BA_DEF_ BO_  "VAGTP20_DynSetup" ENUM "No", "Yes";
BA_DEF_ BO_  "VAGTP20_StatConnection" ENUM "No", "Yes";
BA_DEF_ SG_  "GenSigActiveRepetitions" INT -2147483648 2147483647;
BA_DEF_ SG_  "GenSigInactiveValue" INT -2147483648 2147483647;
BA_DEF_ SG_  "GenSigSendType" ENUM "Cyclic", "OnWrite", "OnWriteWithRepetition", "OnChange", "OnChangeWithRepetition", "IfActive", "IfActiveWithRepetition", "NoSigSendType", "OnChangeAndIfActive", "OnChangeAndIfActiveWithRepetition";
BA_DEF_ SG_  "GenSigStartValue" INT -2147483648 2147483647;
BA_DEF_ SG_  "NWM-WakeupAllowed" ENUM "No", "Yes";
BA_DEF_ SG_  "GenSigFuncType" ENUM "NoFunction", "MsgCounter", "CRC-8", "XOR", "XOR-2", "DatedBit", "SW-Kl15", "CHK", "Constant", "Protocol", "CRC-8-SAE_J1850";
BA_DEF_ SG_  "GenSigSwitchedByIgnition" ENUM "No", "Yes";
BA_DEF_ SG_  "Fehlerwert" HEX 0 2147483647;
BA_DEF_ SG_  "GenSigMissingSourceValue" HEX 0 2147483647;
BA_DEF_DEF_REL_  "GenSigTimeoutTime" 0;
BA_DEF_DEF_  "DiagRequest" "No";
BA_DEF_DEF_  "DiagResponse" "No";
BA_DEF_DEF_  "DiagState" "No";
BA_DEF_DEF_  "GenMsgChkConstant" 0;
BA_DEF_DEF_  "GenMsgCycleTime" 0;
BA_DEF_DEF_  "GenMsgCycleTimeFast" 0;
BA_DEF_DEF_  "GenMsgDelayTime" 0;
BA_DEF_DEF_  "GenMsgILSupport" "No";
BA_DEF_DEF_  "GenMsgNrOfRepetition" 0;
BA_DEF_DEF_  "GenMsgPDUConstants" "";
BA_DEF_DEF_  "GenMsgSendType" "NoMsgSendType";
BA_DEF_DEF_  "GenMsgStartDelayTime" 0;
BA_DEF_DEF_  "NmMessage" "No";
BA_DEF_DEF_  "NmhMessage" "No";
BA_DEF_DEF_  "MsgType" "Application";
BA_DEF_DEF_  "VAGTP20_API" 0;
BA_DEF_DEF_  "VAGTP20_DynConnection" "No";
BA_DEF_DEF_  "VAGTP20_DynSetup" "No";
BA_DEF_DEF_  "VAGTP20_StatConnection" "No";
BA_DEF_DEF_  "GenSigActiveRepetitions" 0;
BA_DEF_DEF_  "GenSigInactiveValue" 0;
BA_DEF_DEF_  "GenSigSendType" "NoSigSendType";
BA_DEF_DEF_  "GenSigStartValue" 0;
BA_DEF_DEF_  "NWM-WakeupAllowed" "No";
BA_DEF_DEF_  "GenSigFuncType" "NoFunction";
BA_DEF_DEF_  "GenSigSwitchedByIgnition" "Yes";
BA_DEF_DEF_  "Fehlerwert" 0;
BA_DEF_DEF_  "GenSigMissingSourceValue" 0;
BA_ "GenMsgChkConstant" BO_ 960 195;
BA_ "GenMsgCycleTime" BO_ 960 100;
BA_ "GenMsgDelayTime" BO_ 960 10;
BA_ "GenMsgILSupport" BO_ 960 1;
BA_ "GenMsgPDUConstants" BO_ 960 "0xc3,0xc3,0xc3,0xc3,0xc3,0xc3,0xc3,0xc3,0xc3,0xc3,0xc3,0xc3,0xc3,0xc3,0xc3,0xc3";
BA_ "GenMsgSendType" BO_ 960 0;
BA_ "GenMsgCycleTime" BO_ 1420 1000;
BA_ "GenMsgCycleTimeFast" BO_ 1420 100;
BA_ "GenMsgDelayTime" BO_ 1420 50;
BA_ "GenMsgILSupport" BO_ 1420 1;
BA_ "GenMsgNrOfRepetition" BO_ 1420 3;
BA_ "GenMsgPDUConstants" BO_ 1420 "0x9b,0xb5,0x9d,0x06,0x01,0xe7,0x8f,0xc1,0xd0,0x10,0x47,0xe9,0xd3,0xca,0x05,0xf0";
BA_ "GenMsgSendType" BO_ 1420 0;
BA_ "GenMsgCycleTime" BO_ 1646 2000;
BA_ "GenMsgDelayTime" BO_ 1646 200;
BA_ "GenMsgILSupport" BO_ 1646 1;
BA_ "GenMsgSendType" BO_ 1646 0;
BA_ "GenMsgCycleTime" BO_ 1663 1000;
BA_ "GenMsgDelayTime" BO_ 1663 50;
BA_ "GenMsgILSupport" BO_ 1663 1;
BA_ "GenMsgSendType" BO_ 1663 0;
BA_ "GenMsgCycleTime" BO_ 1649 2000;
BA_ "GenMsgDelayTime" BO_ 1649 200;
BA_ "GenMsgILSupport" BO_ 1649 1;
BA_ "GenMsgSendType" BO_ 1649 0;
BA_ "GenMsgCycleTime" BO_ 1608 1000;
BA_ "GenMsgDelayTime" BO_ 1608 50;
BA_ "GenMsgILSupport" BO_ 1608 1;
BA_ "GenMsgSendType" BO_ 1608 0;
BA_ "GenMsgCycleTime" BO_ 949 100;
BA_ "GenMsgILSupport" BO_ 949 1;
BA_ "GenMsgSendType" BO_ 949 0;
BA_ "GenMsgCycleTime" BO_ 1640 200;
BA_ "GenMsgCycleTimeFast" BO_ 1640 100;
BA_ "GenMsgDelayTime" BO_ 1640 25;
BA_ "GenMsgILSupport" BO_ 1640 1;
BA_ "GenMsgNrOfRepetition" BO_ 1640 5;
BA_ "GenMsgSendType" BO_ 1640 0;
BA_ "GenMsgCycleTime" BO_ 1441 500;
BA_ "GenMsgILSupport" BO_ 1441 1;
BA_ "GenMsgSendType" BO_ 1441 0;
BA_ "GenMsgCycleTime" BO_ 2589283469 1000;
BA_ "GenMsgDelayTime" BO_ 2589283469 100;
BA_ "GenMsgILSupport" BO_ 2589283469 1;
BA_ "GenMsgSendType" BO_ 2589283469 0;
BA_ "GenMsgCycleTime" BO_ 2589283621 1000;
BA_ "GenMsgDelayTime" BO_ 2589283621 100;
BA_ "GenMsgILSupport" BO_ 2589283621 1;
BA_ "GenMsgSendType" BO_ 2589283621 0;
BA_ "GenMsgCycleTime" BO_ 992 100;
BA_ "GenMsgILSupport" BO_ 992 1;
BA_ "GenMsgSendType" BO_ 992 0;
BA_ "GenMsgCycleTime" BO_ 1712 500;
BA_ "GenMsgILSupport" BO_ 1712 1;
BA_ "GenMsgSendType" BO_ 1712 0;
BA_ "GenMsgCycleTime" BO_ 1505 200;
BA_ "GenMsgILSupport" BO_ 1505 1;
BA_ "GenMsgSendType" BO_ 1505 0;
BA_ "GenMsgCycleTime" BO_ 1717 500;
BA_ "GenMsgILSupport" BO_ 1717 1;
BA_ "GenMsgSendType" BO_ 1717 0;
BA_ "GenMsgCycleTime" BO_ 1513 200;
BA_ "GenMsgILSupport" BO_ 1513 1;
BA_ "GenMsgSendType" BO_ 1513 0;
BA_ "GenMsgCycleTime" BO_ 1295 100;
BA_ "GenMsgILSupport" BO_ 1295 1;
BA_ "GenMsgSendType" BO_ 1295 0;
BA_ "GenMsgCycleTime" BO_ 2589283474 1000;
BA_ "GenMsgDelayTime" BO_ 2589283474 100;
BA_ "GenMsgILSupport" BO_ 2589283474 1;
BA_ "GenMsgSendType" BO_ 2589283474 0;
BA_ "GenMsgCycleTime" BO_ 2549088270 500;
BA_ "GenMsgILSupport" BO_ 2549088270 1;
BA_ "GenMsgSendType" BO_ 2549088270 0;
BA_ "GenMsgCycleTime" BO_ 2549088272 500;
BA_ "GenMsgILSupport" BO_ 2549088272 1;
BA_ "GenMsgSendType" BO_ 2549088272 0;
BA_ "GenMsgStartDelayTime" BO_ 2549088272 75;
BA_ "GenMsgCycleTime" BO_ 2549088326 500;
BA_ "GenMsgILSupport" BO_ 2549088326 1;
BA_ "GenMsgSendType" BO_ 2549088326 0;
BA_ "GenMsgCycleTime" BO_ 2549088345 500;
BA_ "GenMsgILSupport" BO_ 2549088345 1;
BA_ "GenMsgSendType" BO_ 2549088345 0;
BA_ "GenMsgCycleTime" BO_ 2549088452 500;
BA_ "GenMsgILSupport" BO_ 2549088452 1;
BA_ "GenMsgSendType" BO_ 2549088452 0;
BA_ "GenMsgCycleTime" BO_ 2549088453 500;
BA_ "GenMsgILSupport" BO_ 2549088453 1;
BA_ "GenMsgSendType" BO_ 2549088453 0;
BA_ "GenMsgCycleTime" BO_ 779 200;
BA_ "GenMsgDelayTime" BO_ 779 50;
BA_ "GenMsgILSupport" BO_ 779 1;
BA_ "GenMsgSendType" BO_ 779 0;
BA_ "GenMsgCycleTime" BO_ 1719 1000;
BA_ "GenMsgDelayTime" BO_ 1719 100;
BA_ "GenMsgILSupport" BO_ 1719 1;
BA_ "GenMsgSendType" BO_ 1719 0;
BA_ "MsgType" BO_ 2549874958 4;
BA_ "MsgType" BO_ 2550006030 4;
BA_ "MsgType" BO_ 2549875140 4;
BA_ "MsgType" BO_ 2550006212 4;
BA_ "MsgType" BO_ 2549875141 4;
BA_ "MsgType" BO_ 2550006213 4;
BA_ "GenMsgCycleTime" BO_ 919 80;
BA_ "GenMsgDelayTime" BO_ 919 40;
BA_ "GenMsgILSupport" BO_ 919 1;
BA_ "GenMsgSendType" BO_ 919 0;
BA_ "GenSigSendType" SG_ 960 BCM_Ausparken_Betrieb 3;
BA_ "GenSigSwitchedByIgnition" SG_ 960 BCM_Ausparken_Betrieb 0;
BA_ "GenSigSendType" SG_ 960 BCM_Remotestart_Betrieb 3;
BA_ "GenSigSwitchedByIgnition" SG_ 960 BCM_Remotestart_Betrieb 0;
BA_ "GenSigSendType" SG_ 960 BCM_Remotestart_KL15_Anf 3;
BA_ "GenSigSwitchedByIgnition" SG_ 960 BCM_Remotestart_KL15_Anf 0;
BA_ "GenSigSendType" SG_ 960 BCM_Remotestart_MO_Start 3;
BA_ "GenSigSwitchedByIgnition" SG_ 960 BCM_Remotestart_MO_Start 0;
BA_ "GenSigSendType" SG_ 960 Klemmen_Status_01_BZ 0;
BA_ "GenSigFuncType" SG_ 960 Klemmen_Status_01_BZ 1;
BA_ "GenSigSwitchedByIgnition" SG_ 960 Klemmen_Status_01_BZ 0;
BA_ "GenSigSendType" SG_ 960 Klemmen_Status_01_CRC 0;
BA_ "GenSigFuncType" SG_ 960 Klemmen_Status_01_CRC 2;
BA_ "GenSigSwitchedByIgnition" SG_ 960 Klemmen_Status_01_CRC 0;
BA_ "GenSigSendType" SG_ 960 KST_Fahrerhinweis_1 3;
BA_ "GenSigSwitchedByIgnition" SG_ 960 KST_Fahrerhinweis_1 0;
BA_ "GenSigSendType" SG_ 960 KST_Fahrerhinweis_2 3;
BA_ "GenSigSwitchedByIgnition" SG_ 960 KST_Fahrerhinweis_2 0;
BA_ "GenSigSendType" SG_ 960 KST_Fahrerhinweis_4 3;
BA_ "GenSigSwitchedByIgnition" SG_ 960 KST_Fahrerhinweis_4 0;
BA_ "GenSigSendType" SG_ 960 KST_Fahrerhinweis_5 3;
BA_ "GenSigSwitchedByIgnition" SG_ 960 KST_Fahrerhinweis_5 0;
BA_ "GenSigSendType" SG_ 960 KST_Fahrerhinweis_6 3;
BA_ "GenSigSwitchedByIgnition" SG_ 960 KST_Fahrerhinweis_6 0;
BA_ "GenSigSendType" SG_ 960 KST_Warn_P1_ZST_def 3;
BA_ "GenSigSwitchedByIgnition" SG_ 960 KST_Warn_P1_ZST_def 0;
BA_ "GenSigSendType" SG_ 960 KST_Warn_P2_ZST_def 3;
BA_ "GenSigSwitchedByIgnition" SG_ 960 KST_Warn_P2_ZST_def 0;
BA_ "GenSigSendType" SG_ 960 RSt_Fahrerhinweise 3;
BA_ "GenSigSwitchedByIgnition" SG_ 960 RSt_Fahrerhinweise 0;
BA_ "GenSigSendType" SG_ 960 ZAS_Kl_15 3;
BA_ "NWM-WakeupAllowed" SG_ 960 ZAS_Kl_15 1;
BA_ "GenSigFuncType" SG_ 960 ZAS_Kl_15 6;
BA_ "GenSigSwitchedByIgnition" SG_ 960 ZAS_Kl_15 0;
BA_ "GenSigSendType" SG_ 960 ZAS_Kl_50_Startanforderung 3;
BA_ "GenSigSwitchedByIgnition" SG_ 960 ZAS_Kl_50_Startanforderung 0;
BA_ "GenSigSendType" SG_ 960 ZAS_Kl_Infotainment 3;
BA_ "GenSigSwitchedByIgnition" SG_ 960 ZAS_Kl_Infotainment 0;
BA_ "GenSigSendType" SG_ 960 ZAS_Kl_S 3;
BA_ "GenSigSwitchedByIgnition" SG_ 960 ZAS_Kl_S 0;
BA_ "GenSigSendType" SG_ 960 ZAS_Kl_X 3;
BA_ "GenSigSwitchedByIgnition" SG_ 960 ZAS_Kl_X 0;
BA_ "GenSigSendType" SG_ 1420 Klemmen_Steuerung_01_BZ 0;
BA_ "GenSigFuncType" SG_ 1420 Klemmen_Steuerung_01_BZ 1;
BA_ "GenSigSwitchedByIgnition" SG_ 1420 Klemmen_Steuerung_01_BZ 0;
BA_ "GenSigSendType" SG_ 1420 Klemmen_Steuerung_01_CRC 0;
BA_ "GenSigFuncType" SG_ 1420 Klemmen_Steuerung_01_CRC 2;
BA_ "GenSigSwitchedByIgnition" SG_ 1420 Klemmen_Steuerung_01_CRC 0;
BA_ "GenSigSendType" SG_ 1420 KST_Anf_Klemmenfreigabe_ELV 8;
BA_ "GenSigSwitchedByIgnition" SG_ 1420 KST_Anf_Klemmenfreigabe_ELV 0;
BA_ "GenSigSendType" SG_ 1420 KST_Anf_ZV_Verriegelung 3;
BA_ "GenSigSwitchedByIgnition" SG_ 1420 KST_Anf_ZV_Verriegelung 0;
BA_ "GenSigActiveRepetitions" SG_ 1420 KST_aut_Abschaltung_Zuendung 3;
BA_ "GenSigSendType" SG_ 1420 KST_aut_Abschaltung_Zuendung 4;
BA_ "GenSigSwitchedByIgnition" SG_ 1420 KST_aut_Abschaltung_Zuendung 0;
BA_ "GenSigSendType" SG_ 1420 KST_Txt_Komfortabschaltung 3;
BA_ "GenSigSwitchedByIgnition" SG_ 1420 KST_Txt_Komfortabschaltung 0;
BA_ "GenSigSendType" SG_ 1420 KST_Txt_P_Gang 3;
BA_ "GenSigSwitchedByIgnition" SG_ 1420 KST_Txt_P_Gang 0;
BA_ "GenSigSendType" SG_ 1420 KST_Txt_Panikabschaltung 3;
BA_ "GenSigSwitchedByIgnition" SG_ 1420 KST_Txt_Panikabschaltung 0;
BA_ "GenSigSendType" SG_ 1420 KST_Unterdr_Zuendungsmeldung 3;
BA_ "GenSigSwitchedByIgnition" SG_ 1420 KST_Unterdr_Zuendungsmeldung 0;
BA_ "GenSigSendType" SG_ 1420 KST_ZAT_betaetigt 3;
BA_ "GenSigSwitchedByIgnition" SG_ 1420 KST_ZAT_betaetigt 0;
BA_ "GenSigSendType" SG_ 1420 Relais_VoKo_angesteuert 3;
BA_ "GenSigSwitchedByIgnition" SG_ 1420 Relais_VoKo_angesteuert 0;
BA_ "GenSigSendType" SG_ 1420 RSt_Anforderung_HMS 3;
BA_ "GenSigSwitchedByIgnition" SG_ 1420 RSt_Anforderung_HMS 0;
BA_ "GenSigSendType" SG_ 1646 KL_Anf_AussenspiegelHzg 3;
BA_ "GenSigSwitchedByIgnition" SG_ 1646 KL_Anf_AussenspiegelHzg 0;
BA_ "GenSigSendType" SG_ 1646 KL_BCmE_Livetip_Freigabe 3;
BA_ "GenSigSwitchedByIgnition" SG_ 1646 KL_BCmE_Livetip_Freigabe 0;
BA_ "GenSigSendType" SG_ 1646 KL_ErwVK_Anf 3;
BA_ "GenSigSwitchedByIgnition" SG_ 1646 KL_ErwVK_Anf 0;
BA_ "GenSigSendType" SG_ 1646 KL_ErwVK_Zusatzrelais 3;
BA_ "GenSigSwitchedByIgnition" SG_ 1646 KL_ErwVK_Zusatzrelais 0;
BA_ "GenSigSendType" SG_ 1646 KL_FSH_Automatikbetrieb 3;
BA_ "GenSigSwitchedByIgnition" SG_ 1646 KL_FSH_Automatikbetrieb 0;
BA_ "GenSigSendType" SG_ 1646 KL_Geblaese_Fond_Status 0;
BA_ "GenSigStartValue" SG_ 1646 KL_Geblaese_Fond_Status 14;
BA_ "GenSigSwitchedByIgnition" SG_ 1646 KL_Geblaese_Fond_Status 0;
BA_ "Fehlerwert" SG_ 1646 KL_Geblaese_Fond_Status 15;
BA_ "GenSigSendType" SG_ 1646 KL_Geblaese_Status 0;
BA_ "GenSigStartValue" SG_ 1646 KL_Geblaese_Status 14;
BA_ "GenSigSwitchedByIgnition" SG_ 1646 KL_Geblaese_Status 0;
BA_ "Fehlerwert" SG_ 1646 KL_Geblaese_Status 15;
BA_ "GenSigSendType" SG_ 1646 KL_Heizkreisventilstellung 0;
BA_ "GenSigSwitchedByIgnition" SG_ 1646 KL_Heizkreisventilstellung 0;
BA_ "Fehlerwert" SG_ 1646 KL_Heizkreisventilstellung 3;
BA_ "GenSigSendType" SG_ 1646 KL_HYB_ASV_hinten_schliessen_Anf 3;
BA_ "GenSigSwitchedByIgnition" SG_ 1646 KL_HYB_ASV_hinten_schliessen_Anf 0;
BA_ "GenSigSendType" SG_ 1646 KL_HYB_ASV_vorne_schliessen_Anf 3;
BA_ "GenSigSwitchedByIgnition" SG_ 1646 KL_HYB_ASV_vorne_schliessen_Anf 0;
BA_ "GenSigSendType" SG_ 1646 KL_I_Geblaese_Fond 3;
BA_ "GenSigSwitchedByIgnition" SG_ 1646 KL_I_Geblaese_Fond 0;
BA_ "Fehlerwert" SG_ 1646 KL_I_Geblaese_Fond 255;
BA_ "GenSigSendType" SG_ 1646 KL_Innen_Temp 0;
BA_ "GenSigStartValue" SG_ 1646 KL_Innen_Temp 254;
BA_ "GenSigSwitchedByIgnition" SG_ 1646 KL_Innen_Temp 0;
BA_ "Fehlerwert" SG_ 1646 KL_Innen_Temp 255;
BA_ "GenSigSendType" SG_ 1646 KL_Kompressorkupplung 3;
BA_ "GenSigSwitchedByIgnition" SG_ 1646 KL_Kompressorkupplung 0;
BA_ "GenSigSendType" SG_ 1646 KL_Magnetventil 3;
BA_ "GenSigSwitchedByIgnition" SG_ 1646 KL_Magnetventil 0;
BA_ "GenSigSendType" SG_ 1646 KL_Restwaerme_aktiv 3;
BA_ "GenSigSwitchedByIgnition" SG_ 1646 KL_Restwaerme_aktiv 0;
BA_ "GenSigSendType" SG_ 1646 KL_SIH_LEH_Verteilung_VL 3;
BA_ "GenSigSwitchedByIgnition" SG_ 1646 KL_SIH_LEH_Verteilung_VL 0;
BA_ "GenSigSendType" SG_ 1646 KL_SIH_LEH_Verteilung_VR 3;
BA_ "GenSigSwitchedByIgnition" SG_ 1646 KL_SIH_LEH_Verteilung_VR 0;
BA_ "GenSigSendType" SG_ 1646 KL_SIH_LEL_Verteilung_VL 3;
BA_ "GenSigSwitchedByIgnition" SG_ 1646 KL_SIH_LEL_Verteilung_VL 0;
BA_ "GenSigSendType" SG_ 1646 KL_SIH_LEL_Verteilung_VR 3;
BA_ "GenSigSwitchedByIgnition" SG_ 1646 KL_SIH_LEL_Verteilung_VR 0;
BA_ "GenSigSendType" SG_ 1646 KL_Solarluefter_aktiv 3;
BA_ "GenSigSwitchedByIgnition" SG_ 1646 KL_Solarluefter_aktiv 0;
BA_ "GenSigSendType" SG_ 1646 KL_Status_Beduftung 3;
BA_ "GenSigSwitchedByIgnition" SG_ 1646 KL_Status_Beduftung 0;
BA_ "GenSigSendType" SG_ 1646 KL_Status_Ionisator_Front 3;
BA_ "GenSigSwitchedByIgnition" SG_ 1646 KL_Status_Ionisator_Front 0;
BA_ "GenSigSendType" SG_ 1646 KL_STH_aktiv 3;
BA_ "GenSigSwitchedByIgnition" SG_ 1646 KL_STH_aktiv 0;
BA_ "GenSigSendType" SG_ 1646 KL_STH_Ansteuerung 3;
BA_ "GenSigSwitchedByIgnition" SG_ 1646 KL_STH_Ansteuerung 0;
BA_ "GenSigSendType" SG_ 1646 KL_STH_Betriebsdauer 3;
BA_ "GenSigSwitchedByIgnition" SG_ 1646 KL_STH_Betriebsdauer 0;
BA_ "GenSigSendType" SG_ 1646 KL_STH_Timer_Status 3;
BA_ "GenSigSwitchedByIgnition" SG_ 1646 KL_STH_Timer_Status 0;
BA_ "GenSigSendType" SG_ 1646 KL_STL_aktiv 3;
BA_ "GenSigSwitchedByIgnition" SG_ 1646 KL_STL_aktiv 0;
BA_ "GenSigSendType" SG_ 1646 KL_Umluft_Taste 3;
BA_ "GenSigSwitchedByIgnition" SG_ 1646 KL_Umluft_Taste 0;
BA_ "GenSigSendType" SG_ 1646 KL_WaPu 3;
BA_ "GenSigSwitchedByIgnition" SG_ 1646 KL_WaPu 0;
BA_ "GenSigSendType" SG_ 1663 KL_Absperrventil_Fond 3;
BA_ "GenSigSwitchedByIgnition" SG_ 1663 KL_Absperrventil_Fond 0;
BA_ "GenSigSendType" SG_ 1663 KL_Einheiten 3;
BA_ "GenSigSwitchedByIgnition" SG_ 1663 KL_Einheiten 0;
BA_ "GenSigSendType" SG_ 1663 KL_Fond_li_reduziert 3;
BA_ "GenSigSwitchedByIgnition" SG_ 1663 KL_Fond_li_reduziert 0;
BA_ "GenSigSendType" SG_ 1663 KL_Fond_re_reduziert 3;
BA_ "GenSigSwitchedByIgnition" SG_ 1663 KL_Fond_re_reduziert 0;
BA_ "GenSigSendType" SG_ 1663 KL_Fondbed_vorne_aktiv 3;
BA_ "GenSigSwitchedByIgnition" SG_ 1663 KL_Fondbed_vorne_aktiv 0;
BA_ "GenSigSendType" SG_ 1663 KL_Gebl_Verst_Abs_Modus 0;
BA_ "GenSigSwitchedByIgnition" SG_ 1663 KL_Gebl_Verst_Abs_Modus 0;
BA_ "GenSigSendType" SG_ 1663 KL_Geblaesespg_Fond 3;
BA_ "GenSigStartValue" SG_ 1663 KL_Geblaesespg_Fond 254;
BA_ "GenSigSwitchedByIgnition" SG_ 1663 KL_Geblaesespg_Fond 0;
BA_ "GenSigSendType" SG_ 1663 KL_Heizverbraucher_aus 3;
BA_ "GenSigSwitchedByIgnition" SG_ 1663 KL_Heizverbraucher_aus 0;
BA_ "GenSigSendType" SG_ 1663 KL_Heizverbraucher_Notaus 3;
BA_ "GenSigSwitchedByIgnition" SG_ 1663 KL_Heizverbraucher_Notaus 0;
BA_ "GenSigSendType" SG_ 1663 KL_ICO2_Sensor_defekt 3;
BA_ "GenSigSwitchedByIgnition" SG_ 1663 KL_ICO2_Sensor_defekt 0;
BA_ "GenSigSendType" SG_ 1663 KL_Kindersicherung 3;
BA_ "GenSigSwitchedByIgnition" SG_ 1663 KL_Kindersicherung 0;
BA_ "GenSigSendType" SG_ 1663 KL_Mod_Display_li 3;
BA_ "GenSigSwitchedByIgnition" SG_ 1663 KL_Mod_Display_li 0;
BA_ "GenSigSendType" SG_ 1663 KL_Mod_Display_re 3;
BA_ "GenSigSwitchedByIgnition" SG_ 1663 KL_Mod_Display_re 0;
BA_ "GenSigSendType" SG_ 1663 KL_SH_HL_Lastabschaltung 3;
BA_ "GenSigSwitchedByIgnition" SG_ 1663 KL_SH_HL_Lastabschaltung 0;
BA_ "GenSigSendType" SG_ 1663 KL_SH_HR_Lastabschaltung 3;
BA_ "GenSigSwitchedByIgnition" SG_ 1663 KL_SH_HR_Lastabschaltung 0;
BA_ "GenSigSendType" SG_ 1663 KL_Sollausblastemp_HL 3;
BA_ "GenSigStartValue" SG_ 1663 KL_Sollausblastemp_HL 1022;
BA_ "GenSigSwitchedByIgnition" SG_ 1663 KL_Sollausblastemp_HL 0;
BA_ "Fehlerwert" SG_ 1663 KL_Sollausblastemp_HL 1023;
BA_ "GenSigSendType" SG_ 1663 KL_Sollausblastemp_HR 3;
BA_ "GenSigStartValue" SG_ 1663 KL_Sollausblastemp_HR 1022;
BA_ "GenSigSwitchedByIgnition" SG_ 1663 KL_Sollausblastemp_HR 0;
BA_ "Fehlerwert" SG_ 1663 KL_Sollausblastemp_HR 1023;
BA_ "GenSigSendType" SG_ 1663 KL_Umluft 3;
BA_ "GenSigStartValue" SG_ 1663 KL_Umluft 254;
BA_ "GenSigSwitchedByIgnition" SG_ 1663 KL_Umluft 0;
BA_ "Fehlerwert" SG_ 1663 KL_Umluft 255;
BA_ "GenSigSendType" SG_ 1649 KL_Betriebsmodus_FH 3;
BA_ "GenSigSwitchedByIgnition" SG_ 1649 KL_Betriebsmodus_FH 0;
BA_ "GenSigSendType" SG_ 1649 KL_Stopp_Wiederstart_Anz_01 3;
BA_ "GenSigSwitchedByIgnition" SG_ 1649 KL_Stopp_Wiederstart_Anz_01 0;
BA_ "GenSigSendType" SG_ 1649 KL_Stopp_Wiederstart_Anz_02 3;
BA_ "GenSigSwitchedByIgnition" SG_ 1649 KL_Stopp_Wiederstart_Anz_02 0;
BA_ "GenSigSendType" SG_ 1649 KL_Stopp_Wiederstart_Anz_03 3;
BA_ "GenSigSwitchedByIgnition" SG_ 1649 KL_Stopp_Wiederstart_Anz_03 0;
BA_ "GenSigSendType" SG_ 1649 KL_Stopp_Wiederstart_Anz_04 3;
BA_ "GenSigSwitchedByIgnition" SG_ 1649 KL_Stopp_Wiederstart_Anz_04 0;
BA_ "GenSigSendType" SG_ 1649 KL_Stopp_Wiederstart_Anz_05 3;
BA_ "GenSigSwitchedByIgnition" SG_ 1649 KL_Stopp_Wiederstart_Anz_05 0;
BA_ "GenSigSendType" SG_ 1649 KL_Stopp_Wiederstart_Anz_06 3;
BA_ "GenSigSwitchedByIgnition" SG_ 1649 KL_Stopp_Wiederstart_Anz_06 0;
BA_ "GenSigSendType" SG_ 1649 KL_Stopp_Wiederstart_Anz_07 3;
BA_ "GenSigSwitchedByIgnition" SG_ 1649 KL_Stopp_Wiederstart_Anz_07 0;
BA_ "GenSigSendType" SG_ 1649 KL_Stopp_Wiederstart_Anz_08 3;
BA_ "GenSigSwitchedByIgnition" SG_ 1649 KL_Stopp_Wiederstart_Anz_08 0;
BA_ "GenSigSendType" SG_ 1649 KL_Stopp_Wiederstart_Anz_09 3;
BA_ "GenSigSwitchedByIgnition" SG_ 1649 KL_Stopp_Wiederstart_Anz_09 0;
BA_ "GenSigSendType" SG_ 1649 KL_Stopp_Wiederstart_Anz_Std1 3;
BA_ "GenSigSwitchedByIgnition" SG_ 1649 KL_Stopp_Wiederstart_Anz_Std1 0;
BA_ "GenSigSendType" SG_ 1649 KL_Stopp_Wiederstart_Anz_Std2 3;
BA_ "GenSigSwitchedByIgnition" SG_ 1649 KL_Stopp_Wiederstart_Anz_Std2 0;
BA_ "GenSigSendType" SG_ 1649 KL_ZZ_Betriebsmodus 3;
BA_ "GenSigSwitchedByIgnition" SG_ 1649 KL_ZZ_Betriebsmodus 0;
BA_ "GenSigSendType" SG_ 1649 KL_ZZ_Minute 3;
BA_ "GenSigSwitchedByIgnition" SG_ 1649 KL_ZZ_Minute 0;
BA_ "GenSigSendType" SG_ 1649 KL_ZZ_Monat 3;
BA_ "GenSigSwitchedByIgnition" SG_ 1649 KL_ZZ_Monat 0;
BA_ "GenSigSendType" SG_ 1649 KL_ZZ_Status_Timer 3;
BA_ "GenSigSwitchedByIgnition" SG_ 1649 KL_ZZ_Status_Timer 0;
BA_ "GenSigSendType" SG_ 1649 KL_ZZ_Stunde 3;
BA_ "GenSigSwitchedByIgnition" SG_ 1649 KL_ZZ_Stunde 0;
BA_ "GenSigSendType" SG_ 1649 KL_ZZ_Tag 3;
BA_ "GenSigSwitchedByIgnition" SG_ 1649 KL_ZZ_Tag 0;
BA_ "GenSigSendType" SG_ 1608 KL_AC_Fond_Soll 3;
BA_ "GenSigSwitchedByIgnition" SG_ 1608 KL_AC_Fond_Soll 0;
BA_ "GenSigSendType" SG_ 1608 KL_AUTO_HL_Soll 3;
BA_ "GenSigSwitchedByIgnition" SG_ 1608 KL_AUTO_HL_Soll 0;
BA_ "GenSigSendType" SG_ 1608 KL_AUTO_HR_Soll 3;
BA_ "GenSigSwitchedByIgnition" SG_ 1608 KL_AUTO_HR_Soll 0;
BA_ "GenSigSendType" SG_ 1608 KL_Befehlszaehler_FH 3;
BA_ "GenSigSwitchedByIgnition" SG_ 1608 KL_Befehlszaehler_FH 0;
BA_ "GenSigSendType" SG_ 1608 KL_Fondbedienung_aktiv 3;
BA_ "GenSigSwitchedByIgnition" SG_ 1608 KL_Fondbedienung_aktiv 0;
BA_ "GenSigSendType" SG_ 1608 KL_Luftmenge_HL_max 3;
BA_ "GenSigSwitchedByIgnition" SG_ 1608 KL_Luftmenge_HL_max 0;
BA_ "GenSigSendType" SG_ 1608 KL_Luftmenge_HL_offset 3;
BA_ "GenSigSwitchedByIgnition" SG_ 1608 KL_Luftmenge_HL_offset 0;
BA_ "GenSigSendType" SG_ 1608 KL_Luftmenge_HL_Soll 3;
BA_ "GenSigSwitchedByIgnition" SG_ 1608 KL_Luftmenge_HL_Soll 0;
BA_ "GenSigSendType" SG_ 1608 KL_Luftmenge_HR_max 3;
BA_ "GenSigSwitchedByIgnition" SG_ 1608 KL_Luftmenge_HR_max 0;
BA_ "GenSigSendType" SG_ 1608 KL_Luftmenge_HR_offset 3;
BA_ "GenSigSwitchedByIgnition" SG_ 1608 KL_Luftmenge_HR_offset 0;
BA_ "GenSigSendType" SG_ 1608 KL_Luftmenge_HR_Soll 3;
BA_ "GenSigSwitchedByIgnition" SG_ 1608 KL_Luftmenge_HR_Soll 0;
BA_ "GenSigSendType" SG_ 1608 KL_Luftverteilung_HL_Soll 3;
BA_ "GenSigSwitchedByIgnition" SG_ 1608 KL_Luftverteilung_HL_Soll 0;
BA_ "GenSigSendType" SG_ 1608 KL_Luftverteilung_HR_Soll 3;
BA_ "GenSigSwitchedByIgnition" SG_ 1608 KL_Luftverteilung_HR_Soll 0;
BA_ "GenSigSendType" SG_ 1608 KL_SH_HL_Soll 3;
BA_ "GenSigSwitchedByIgnition" SG_ 1608 KL_SH_HL_Soll 0;
BA_ "GenSigSendType" SG_ 1608 KL_SH_HR_Soll 3;
BA_ "GenSigSwitchedByIgnition" SG_ 1608 KL_SH_HR_Soll 0;
BA_ "GenSigSendType" SG_ 1608 KL_SL_HL_Soll 3;
BA_ "GenSigSwitchedByIgnition" SG_ 1608 KL_SL_HL_Soll 0;
BA_ "GenSigSendType" SG_ 1608 KL_SL_HR_Soll 3;
BA_ "GenSigSwitchedByIgnition" SG_ 1608 KL_SL_HR_Soll 0;
BA_ "GenSigSendType" SG_ 1608 KL_Status_Soll 3;
BA_ "GenSigSwitchedByIgnition" SG_ 1608 KL_Status_Soll 0;
BA_ "GenSigSendType" SG_ 1608 KL_Temp_HL_Soll 3;
BA_ "GenSigSwitchedByIgnition" SG_ 1608 KL_Temp_HL_Soll 0;
BA_ "GenSigSendType" SG_ 1608 KL_Temp_HR_Soll 3;
BA_ "GenSigSwitchedByIgnition" SG_ 1608 KL_Temp_HR_Soll 0;
BA_ "GenSigSendType" SG_ 949 KL_AC_Schalter 0;
BA_ "GenSigSwitchedByIgnition" SG_ 949 KL_AC_Schalter 0;
BA_ "GenSigSendType" SG_ 949 KL_Anf_KL 0;
BA_ "GenSigSwitchedByIgnition" SG_ 949 KL_Anf_KL 0;
BA_ "Fehlerwert" SG_ 949 KL_Anf_KL 255;
BA_ "GenSigSendType" SG_ 949 KL_Ausstattung_Klima 0;
BA_ "GenSigSwitchedByIgnition" SG_ 949 KL_Ausstattung_Klima 0;
BA_ "GenSigSendType" SG_ 949 KL_Charisma_FahrPr 0;
BA_ "GenSigSwitchedByIgnition" SG_ 949 KL_Charisma_FahrPr 0;
BA_ "GenSigSendType" SG_ 949 KL_Charisma_Status 0;
BA_ "GenSigSwitchedByIgnition" SG_ 949 KL_Charisma_Status 0;
BA_ "GenSigSendType" SG_ 949 KL_Drehz_Anh 0;
BA_ "GenSigSwitchedByIgnition" SG_ 949 KL_Drehz_Anh 0;
BA_ "GenSigSendType" SG_ 949 KL_el_Zuheizer_Stufe 0;
BA_ "GenSigSwitchedByIgnition" SG_ 949 KL_el_Zuheizer_Stufe 0;
BA_ "GenSigSendType" SG_ 949 KL_Freilauf_Info 0;
BA_ "GenSigSwitchedByIgnition" SG_ 949 KL_Freilauf_Info 0;
BA_ "GenSigSendType" SG_ 949 KL_Komp_Moment_alt 0;
BA_ "GenSigFuncType" SG_ 949 KL_Komp_Moment_alt 5;
BA_ "GenSigSwitchedByIgnition" SG_ 949 KL_Komp_Moment_alt 0;
BA_ "GenSigSendType" SG_ 949 KL_Kompressorkupplung_linear 0;
BA_ "GenSigStartValue" SG_ 949 KL_Kompressorkupplung_linear 254;
BA_ "GenSigSwitchedByIgnition" SG_ 949 KL_Kompressorkupplung_linear 0;
BA_ "GenSigSendType" SG_ 949 KL_Last_Kompr 0;
BA_ "GenSigSwitchedByIgnition" SG_ 949 KL_Last_Kompr 0;
BA_ "Fehlerwert" SG_ 949 KL_Last_Kompr 255;
BA_ "GenSigSendType" SG_ 949 KL_nachtr_Stopp_Anf 0;
BA_ "GenSigSwitchedByIgnition" SG_ 949 KL_nachtr_Stopp_Anf 0;
BA_ "GenSigSendType" SG_ 949 KL_Spannungs_Anf 0;
BA_ "GenSigSwitchedByIgnition" SG_ 949 KL_Spannungs_Anf 0;
BA_ "GenSigSendType" SG_ 949 KL_StartStopp_Info 0;
BA_ "GenSigSwitchedByIgnition" SG_ 949 KL_StartStopp_Info 0;
BA_ "GenSigSendType" SG_ 949 KL_T_Charge 0;
BA_ "GenSigSwitchedByIgnition" SG_ 949 KL_T_Charge 0;
BA_ "GenSigSendType" SG_ 949 KL_Thermomanagement 0;
BA_ "GenSigSwitchedByIgnition" SG_ 949 KL_Thermomanagement 0;
BA_ "GenSigSendType" SG_ 949 KL_Variante_Standheizung 0;
BA_ "GenSigSwitchedByIgnition" SG_ 949 KL_Variante_Standheizung 0;
BA_ "GenSigSendType" SG_ 949 KL_Vorwarn_Komp_ein 0;
BA_ "GenSigSwitchedByIgnition" SG_ 949 KL_Vorwarn_Komp_ein 0;
BA_ "GenSigSendType" SG_ 949 KL_Vorwarn_Zuheizer_ein 0;
BA_ "GenSigSwitchedByIgnition" SG_ 949 KL_Vorwarn_Zuheizer_ein 0;
BA_ "GenSigSendType" SG_ 949 KL_Zustand 0;
BA_ "GenSigSwitchedByIgnition" SG_ 949 KL_Zustand 0;
BA_ "GenSigActiveRepetitions" SG_ 1640 FSH_Taster 5;
BA_ "GenSigSendType" SG_ 1640 FSH_Taster 4;
BA_ "GenSigSwitchedByIgnition" SG_ 1640 FSH_Taster 0;
BA_ "GenSigActiveRepetitions" SG_ 1640 HSH_Taster 5;
BA_ "GenSigSendType" SG_ 1640 HSH_Taster 4;
BA_ "GenSigSwitchedByIgnition" SG_ 1640 HSH_Taster 0;
BA_ "GenSigSendType" SG_ 1640 KL_Beschlagsgefahr 3;
BA_ "GenSigSwitchedByIgnition" SG_ 1640 KL_Beschlagsgefahr 0;
BA_ "GenSigSendType" SG_ 1640 KL_Geblspng_Fond_Soll 0;
BA_ "GenSigSwitchedByIgnition" SG_ 1640 KL_Geblspng_Fond_Soll 0;
BA_ "Fehlerwert" SG_ 1640 KL_Geblspng_Fond_Soll 255;
BA_ "GenSigSendType" SG_ 1640 KL_Geblspng_Soll 0;
BA_ "GenSigSwitchedByIgnition" SG_ 1640 KL_Geblspng_Soll 0;
BA_ "Fehlerwert" SG_ 1640 KL_Geblspng_Soll 255;
BA_ "GenSigSendType" SG_ 1640 KL_I_Geblaese 0;
BA_ "GenSigSwitchedByIgnition" SG_ 1640 KL_I_Geblaese 0;
BA_ "Fehlerwert" SG_ 1640 KL_I_Geblaese 255;
BA_ "GenSigSendType" SG_ 1640 KL_Kompressorstrom_soll 0;
BA_ "GenSigStartValue" SG_ 1640 KL_Kompressorstrom_soll 1022;
BA_ "GenSigSwitchedByIgnition" SG_ 1640 KL_Kompressorstrom_soll 0;
BA_ "Fehlerwert" SG_ 1640 KL_Kompressorstrom_soll 1023;
BA_ "GenSigSendType" SG_ 1640 KL_LRH_Stufe 0;
BA_ "GenSigStartValue" SG_ 1640 KL_LRH_Stufe 1;
BA_ "GenSigSwitchedByIgnition" SG_ 1640 KL_LRH_Stufe 0;
BA_ "GenSigActiveRepetitions" SG_ 1640 KL_LRH_Taster 5;
BA_ "GenSigSendType" SG_ 1640 KL_LRH_Taster 4;
BA_ "GenSigSwitchedByIgnition" SG_ 1640 KL_LRH_Taster 0;
BA_ "GenSigSendType" SG_ 1640 KL_PTC_Verbauinfo 0;
BA_ "GenSigSwitchedByIgnition" SG_ 1640 KL_PTC_Verbauinfo 0;
BA_ "GenSigSendType" SG_ 1640 KL_SIH_Soll_li 3;
BA_ "GenSigSwitchedByIgnition" SG_ 1640 KL_SIH_Soll_li 0;
BA_ "GenSigSendType" SG_ 1640 KL_SIH_Soll_re 3;
BA_ "GenSigSwitchedByIgnition" SG_ 1640 KL_SIH_Soll_re 0;
BA_ "GenSigSendType" SG_ 1640 KL_SIL_Soll_li 3;
BA_ "GenSigSwitchedByIgnition" SG_ 1640 KL_SIL_Soll_li 0;
BA_ "GenSigSendType" SG_ 1640 KL_SIL_Soll_re 3;
BA_ "GenSigSwitchedByIgnition" SG_ 1640 KL_SIL_Soll_re 0;
BA_ "GenSigSendType" SG_ 1640 KL_Umluftklappe_Status 0;
BA_ "GenSigStartValue" SG_ 1640 KL_Umluftklappe_Status 14;
BA_ "GenSigSwitchedByIgnition" SG_ 1640 KL_Umluftklappe_Status 0;
BA_ "Fehlerwert" SG_ 1640 KL_Umluftklappe_Status 15;
BA_ "GenSigSendType" SG_ 1640 KL_Zuheizer_Freigabe 3;
BA_ "GenSigSwitchedByIgnition" SG_ 1640 KL_Zuheizer_Freigabe 0;
BA_ "GenSigSendType" SG_ 1640 KRH_Soll_li 3;
BA_ "GenSigSwitchedByIgnition" SG_ 1640 KRH_Soll_li 0;
BA_ "GenSigSendType" SG_ 1640 KRH_Soll_re 3;
BA_ "GenSigSwitchedByIgnition" SG_ 1640 KRH_Soll_re 0;
BA_ "GenSigSendType" SG_ 1441 KL_Frischluftklappe_Status 0;
BA_ "GenSigStartValue" SG_ 1441 KL_Frischluftklappe_Status 126;
BA_ "GenSigSwitchedByIgnition" SG_ 1441 KL_Frischluftklappe_Status 0;
BA_ "Fehlerwert" SG_ 1441 KL_Frischluftklappe_Status 127;
BA_ "GenSigSendType" SG_ 1441 KL_PTC_linear_Anf 0;
BA_ "GenSigSwitchedByIgnition" SG_ 1441 KL_PTC_linear_Anf 0;
BA_ "Fehlerwert" SG_ 1441 KL_PTC_linear_Anf 63;
BA_ "GenSigSendType" SG_ 1441 KL_SIH_LEH_Verteilung_HL 0;
BA_ "GenSigSwitchedByIgnition" SG_ 1441 KL_SIH_LEH_Verteilung_HL 0;
BA_ "GenSigSendType" SG_ 1441 KL_SIH_LEH_Verteilung_HR 0;
BA_ "GenSigSwitchedByIgnition" SG_ 1441 KL_SIH_LEH_Verteilung_HR 0;
BA_ "GenSigSendType" SG_ 1441 KL_SIH_Stufe_hl 0;
BA_ "GenSigSwitchedByIgnition" SG_ 1441 KL_SIH_Stufe_hl 0;
BA_ "GenSigSendType" SG_ 1441 KL_SIH_Stufe_hr 0;
BA_ "GenSigSwitchedByIgnition" SG_ 1441 KL_SIH_Stufe_hr 0;
BA_ "GenSigSendType" SG_ 1441 KL_SIL_LEL_Verteilung_HL 0;
BA_ "GenSigSwitchedByIgnition" SG_ 1441 KL_SIL_LEL_Verteilung_HL 0;
BA_ "GenSigSendType" SG_ 1441 KL_SIL_LEL_Verteilung_HR 0;
BA_ "GenSigSwitchedByIgnition" SG_ 1441 KL_SIL_LEL_Verteilung_HR 0;
BA_ "GenSigSendType" SG_ 1441 KL_SIL_Stufe_hl 0;
BA_ "GenSigSwitchedByIgnition" SG_ 1441 KL_SIL_Stufe_hl 0;
BA_ "GenSigSendType" SG_ 1441 KL_SIL_Stufe_hr 0;
BA_ "GenSigSwitchedByIgnition" SG_ 1441 KL_SIL_Stufe_hr 0;
BA_ "GenSigSendType" SG_ 1441 KL_Temp_Soll_hl 0;
BA_ "GenSigStartValue" SG_ 1441 KL_Temp_Soll_hl 31;
BA_ "GenSigSwitchedByIgnition" SG_ 1441 KL_Temp_Soll_hl 0;
BA_ "GenSigSendType" SG_ 1441 KL_Temp_Soll_hr 0;
BA_ "GenSigStartValue" SG_ 1441 KL_Temp_Soll_hr 31;
BA_ "GenSigSwitchedByIgnition" SG_ 1441 KL_Temp_Soll_hr 0;
BA_ "GenSigSendType" SG_ 1441 KL_Temp_Soll_vl 0;
BA_ "GenSigStartValue" SG_ 1441 KL_Temp_Soll_vl 31;
BA_ "GenSigSwitchedByIgnition" SG_ 1441 KL_Temp_Soll_vl 0;
BA_ "GenSigSendType" SG_ 1441 KL_Temp_Soll_vr 0;
BA_ "GenSigStartValue" SG_ 1441 KL_Temp_Soll_vr 31;
BA_ "GenSigSwitchedByIgnition" SG_ 1441 KL_Temp_Soll_vr 0;
BA_ "GenSigSendType" SG_ 2589283469 KL_Geblaese_erw 0;
BA_ "GenSigStartValue" SG_ 2589283469 KL_Geblaese_erw 14;
BA_ "GenSigSwitchedByIgnition" SG_ 2589283469 KL_Geblaese_erw 0;
BA_ "Fehlerwert" SG_ 2589283469 KL_Geblaese_erw 15;
BA_ "GenSigSendType" SG_ 2589283469 KL_Geblaese_Fond_erw 0;
BA_ "GenSigStartValue" SG_ 2589283469 KL_Geblaese_Fond_erw 14;
BA_ "GenSigSwitchedByIgnition" SG_ 2589283469 KL_Geblaese_Fond_erw 0;
BA_ "Fehlerwert" SG_ 2589283469 KL_Geblaese_Fond_erw 15;
BA_ "GenSigSendType" SG_ 2589283469 KL_Heizlstg_Delta_Eingriff 3;
BA_ "GenSigStartValue" SG_ 2589283469 KL_Heizlstg_Delta_Eingriff 254;
BA_ "GenSigSwitchedByIgnition" SG_ 2589283469 KL_Heizlstg_Delta_Eingriff 0;
BA_ "Fehlerwert" SG_ 2589283469 KL_Heizlstg_Delta_Eingriff 255;
BA_ "GenSigSendType" SG_ 2589283469 KL_Kuehllstg_Delta_Eingriff 3;
BA_ "GenSigStartValue" SG_ 2589283469 KL_Kuehllstg_Delta_Eingriff 254;
BA_ "GenSigSwitchedByIgnition" SG_ 2589283469 KL_Kuehllstg_Delta_Eingriff 0;
BA_ "Fehlerwert" SG_ 2589283469 KL_Kuehllstg_Delta_Eingriff 255;
BA_ "GenSigSendType" SG_ 2589283469 KL_Tempklappe_Fond 0;
BA_ "GenSigStartValue" SG_ 2589283469 KL_Tempklappe_Fond 254;
BA_ "GenSigSwitchedByIgnition" SG_ 2589283469 KL_Tempklappe_Fond 0;
BA_ "Fehlerwert" SG_ 2589283469 KL_Tempklappe_Fond 255;
BA_ "GenSigSendType" SG_ 2589283469 KL_Tempklappe_li 0;
BA_ "GenSigStartValue" SG_ 2589283469 KL_Tempklappe_li 254;
BA_ "GenSigSwitchedByIgnition" SG_ 2589283469 KL_Tempklappe_li 0;
BA_ "Fehlerwert" SG_ 2589283469 KL_Tempklappe_li 255;
BA_ "GenSigSendType" SG_ 2589283469 KL_Tempklappe_re 0;
BA_ "GenSigStartValue" SG_ 2589283469 KL_Tempklappe_re 254;
BA_ "GenSigSwitchedByIgnition" SG_ 2589283469 KL_Tempklappe_re 0;
BA_ "Fehlerwert" SG_ 2589283469 KL_Tempklappe_re 255;
BA_ "GenSigSendType" SG_ 2589283469 KL_Verdampferleistung 3;
BA_ "GenSigStartValue" SG_ 2589283469 KL_Verdampferleistung 254;
BA_ "GenSigSwitchedByIgnition" SG_ 2589283469 KL_Verdampferleistung 0;
BA_ "Fehlerwert" SG_ 2589283469 KL_Verdampferleistung 255;
BA_ "GenSigSendType" SG_ 2589283469 KL_Verdampferleistung_Faktor 3;
BA_ "GenSigSwitchedByIgnition" SG_ 2589283469 KL_Verdampferleistung_Faktor 0;
BA_ "GenSigSendType" SG_ 2589283469 KL_VK_Anf 3;
BA_ "GenSigStartValue" SG_ 2589283469 KL_VK_Anf 6;
BA_ "GenSigSwitchedByIgnition" SG_ 2589283469 KL_VK_Anf 0;
BA_ "Fehlerwert" SG_ 2589283469 KL_VK_Anf 7;
BA_ "GenSigSendType" SG_ 2589283469 KL_Vorkond_Strategie 3;
BA_ "GenSigStartValue" SG_ 2589283469 KL_Vorkond_Strategie 15;
BA_ "GenSigSwitchedByIgnition" SG_ 2589283469 KL_Vorkond_Strategie 0;
BA_ "GenSigSendType" SG_ 2589283621 KL_ACmax_Aktiv 3;
BA_ "GenSigSwitchedByIgnition" SG_ 2589283621 KL_ACmax_Aktiv 0;
BA_ "GenSigSendType" SG_ 2589283621 KL_Defrost_Aktiv 3;
BA_ "GenSigSwitchedByIgnition" SG_ 2589283621 KL_Defrost_Aktiv 0;
BA_ "GenSigSendType" SG_ 2589283621 KL_ECO_Aktiv 3;
BA_ "GenSigSwitchedByIgnition" SG_ 2589283621 KL_ECO_Aktiv 0;
BA_ "GenSigSendType" SG_ 2589283621 KL_ECO_PRO_Aktiv 3;
BA_ "GenSigSwitchedByIgnition" SG_ 2589283621 KL_ECO_PRO_Aktiv 0;
BA_ "GenSigSendType" SG_ 2589283621 KL_Eps_Innen 3;
BA_ "GenSigStartValue" SG_ 2589283621 KL_Eps_Innen 254;
BA_ "GenSigSwitchedByIgnition" SG_ 2589283621 KL_Eps_Innen 0;
BA_ "Fehlerwert" SG_ 2589283621 KL_Eps_Innen 255;
BA_ "GenSigSendType" SG_ 2589283621 KL_FlHz_Soll_HL 3;
BA_ "GenSigSwitchedByIgnition" SG_ 2589283621 KL_FlHz_Soll_HL 0;
BA_ "GenSigSendType" SG_ 2589283621 KL_FlHz_Soll_HR 3;
BA_ "GenSigSwitchedByIgnition" SG_ 2589283621 KL_FlHz_Soll_HR 0;
BA_ "GenSigSendType" SG_ 2589283621 KL_FlHz_Soll_VL 3;
BA_ "GenSigSwitchedByIgnition" SG_ 2589283621 KL_FlHz_Soll_VL 0;
BA_ "GenSigSendType" SG_ 2589283621 KL_FlHz_Soll_VR 3;
BA_ "GenSigSwitchedByIgnition" SG_ 2589283621 KL_FlHz_Soll_VR 0;
BA_ "GenSigSendType" SG_ 2589283621 KL_Kundeneingriff_Geblaese 3;
BA_ "GenSigSwitchedByIgnition" SG_ 2589283621 KL_Kundeneingriff_Geblaese 0;
BA_ "GenSigSendType" SG_ 2589283621 KL_NV_Energie_Anf 3;
BA_ "GenSigStartValue" SG_ 2589283621 KL_NV_Energie_Anf 254;
BA_ "GenSigSwitchedByIgnition" SG_ 2589283621 KL_NV_Energie_Anf 0;
BA_ "Fehlerwert" SG_ 2589283621 KL_NV_Energie_Anf 255;
BA_ "GenSigSendType" SG_ 2589283621 KL_QBit_Sonnenintensitaet 3;
BA_ "GenSigStartValue" SG_ 2589283621 KL_QBit_Sonnenintensitaet 1;
BA_ "GenSigSwitchedByIgnition" SG_ 2589283621 KL_QBit_Sonnenintensitaet 0;
BA_ "GenSigSendType" SG_ 2589283621 KL_Sonnenintensitaet 0;
BA_ "GenSigSwitchedByIgnition" SG_ 2589283621 KL_Sonnenintensitaet 0;
BA_ "Fehlerwert" SG_ 2589283621 KL_Sonnenintensitaet 255;
BA_ "GenSigSendType" SG_ 2589283621 KL_Status_Klimastil 3;
BA_ "GenSigSwitchedByIgnition" SG_ 2589283621 KL_Status_Klimastil 0;
BA_ "GenSigSendType" SG_ 2589283621 KL_Thermischer_Bedarf 3;
BA_ "GenSigStartValue" SG_ 2589283621 KL_Thermischer_Bedarf 6;
BA_ "GenSigSwitchedByIgnition" SG_ 2589283621 KL_Thermischer_Bedarf 0;
BA_ "Fehlerwert" SG_ 2589283621 KL_Thermischer_Bedarf 7;
BA_ "GenSigSendType" SG_ 2589283621 KL_Umluft_Connect_status 3;
BA_ "GenSigSwitchedByIgnition" SG_ 2589283621 KL_Umluft_Connect_status 0;
BA_ "GenSigSendType" SG_ 2589283621 KL_ZR_Anforderung 3;
BA_ "GenSigSwitchedByIgnition" SG_ 2589283621 KL_ZR_Anforderung 0;
BA_ "GenSigSendType" SG_ 992 KL_Fehler_Fussraum_Klappen 0;
BA_ "GenSigSwitchedByIgnition" SG_ 992 KL_Fehler_Fussraum_Klappen 0;
BA_ "GenSigSendType" SG_ 992 KL_Fehler_Temp_Klappen 0;
BA_ "GenSigSwitchedByIgnition" SG_ 992 KL_Fehler_Temp_Klappen 0;
BA_ "GenSigSendType" SG_ 992 KL_Fehler_Temp_MA_Klappen 0;
BA_ "GenSigSwitchedByIgnition" SG_ 992 KL_Fehler_Temp_MA_Klappen 0;
BA_ "GenSigSendType" SG_ 992 KL_Fehler_Umluft 0;
BA_ "GenSigSwitchedByIgnition" SG_ 992 KL_Fehler_Umluft 0;
BA_ "GenSigSendType" SG_ 992 KL_Fond_Absperrventil 0;
BA_ "GenSigSwitchedByIgnition" SG_ 992 KL_Fond_Absperrventil 0;
BA_ "GenSigSendType" SG_ 992 KL_Fond_Fuss_Temp_hl 0;
BA_ "GenSigStartValue" SG_ 992 KL_Fond_Fuss_Temp_hl 1022;
BA_ "GenSigSwitchedByIgnition" SG_ 992 KL_Fond_Fuss_Temp_hl 0;
BA_ "Fehlerwert" SG_ 992 KL_Fond_Fuss_Temp_hl 1023;
BA_ "GenSigSendType" SG_ 992 KL_Fond_Fuss_Temp_hr 0;
BA_ "GenSigStartValue" SG_ 992 KL_Fond_Fuss_Temp_hr 1022;
BA_ "GenSigSwitchedByIgnition" SG_ 992 KL_Fond_Fuss_Temp_hr 0;
BA_ "Fehlerwert" SG_ 992 KL_Fond_Fuss_Temp_hr 1023;
BA_ "GenSigSendType" SG_ 992 KL_Fond_KD_Fehler 0;
BA_ "GenSigSwitchedByIgnition" SG_ 992 KL_Fond_KD_Fehler 0;
BA_ "GenSigSendType" SG_ 992 KL_MA_Temp_hl 0;
BA_ "GenSigStartValue" SG_ 992 KL_MA_Temp_hl 1022;
BA_ "GenSigSwitchedByIgnition" SG_ 992 KL_MA_Temp_hl 0;
BA_ "Fehlerwert" SG_ 992 KL_MA_Temp_hl 1023;
BA_ "GenSigSendType" SG_ 992 KL_MA_Temp_hr 0;
BA_ "GenSigStartValue" SG_ 992 KL_MA_Temp_hr 1022;
BA_ "GenSigSwitchedByIgnition" SG_ 992 KL_MA_Temp_hr 0;
BA_ "Fehlerwert" SG_ 992 KL_MA_Temp_hr 1023;
BA_ "GenSigSendType" SG_ 992 KL_RAB 0;
BA_ "GenSigSwitchedByIgnition" SG_ 992 KL_RAB 0;
BA_ "GenSigSendType" SG_ 992 KL_SH_Soll_hl 0;
BA_ "GenSigSwitchedByIgnition" SG_ 992 KL_SH_Soll_hl 0;
BA_ "GenSigSendType" SG_ 992 KL_SH_Soll_hr 0;
BA_ "GenSigSwitchedByIgnition" SG_ 992 KL_SH_Soll_hr 0;
BA_ "GenSigSendType" SG_ 992 KL_SIH_Takt_hl 0;
BA_ "GenSigSwitchedByIgnition" SG_ 992 KL_SIH_Takt_hl 0;
BA_ "GenSigSendType" SG_ 992 KL_SIH_Takt_hr 0;
BA_ "GenSigSwitchedByIgnition" SG_ 992 KL_SIH_Takt_hr 0;
BA_ "GenSigSendType" SG_ 992 KL_SL_Soll_hl 0;
BA_ "GenSigSwitchedByIgnition" SG_ 992 KL_SL_Soll_hl 0;
BA_ "GenSigSendType" SG_ 992 KL_SL_Soll_hr 0;
BA_ "GenSigSwitchedByIgnition" SG_ 992 KL_SL_Soll_hr 0;
BA_ "GenSigSendType" SG_ 1712 FS_Luftfeuchte_rel 0;
BA_ "Fehlerwert" SG_ 1712 FS_Luftfeuchte_rel 255;
BA_ "GenSigMissingSourceValue" SG_ 1712 FS_Luftfeuchte_rel 255;
BA_ "GenSigSendType" SG_ 1712 FS_ResponseError 0;
BA_ "GenSigSwitchedByIgnition" SG_ 1712 FS_ResponseError 0;
BA_ "Fehlerwert" SG_ 1712 FS_ResponseError 1;
BA_ "GenSigSendType" SG_ 1712 FS_Taupunkt 0;
BA_ "Fehlerwert" SG_ 1712 FS_Taupunkt 1023;
BA_ "GenSigMissingSourceValue" SG_ 1712 FS_Taupunkt 1023;
BA_ "GenSigSendType" SG_ 1712 FS_Temp_Scheibe 0;
BA_ "Fehlerwert" SG_ 1712 FS_Temp_Scheibe 1023;
BA_ "GenSigMissingSourceValue" SG_ 1712 FS_Temp_Scheibe 1023;
BA_ "GenSigSendType" SG_ 1712 FS_Temp_Sensor 0;
BA_ "Fehlerwert" SG_ 1712 FS_Temp_Sensor 255;
BA_ "GenSigMissingSourceValue" SG_ 1712 FS_Temp_Sensor 255;
BA_ "GenSigSendType" SG_ 1505 BCM1_Aussen_Temp_ungef 0;
BA_ "GenSigStartValue" SG_ 1505 BCM1_Aussen_Temp_ungef 254;
BA_ "GenSigSwitchedByIgnition" SG_ 1505 BCM1_Aussen_Temp_ungef 0;
BA_ "Fehlerwert" SG_ 1505 BCM1_Aussen_Temp_ungef 255;
BA_ "GenSigSendType" SG_ 1505 BCM1_FStatus_Aussentemp_ungef 0;
BA_ "GenSigStartValue" SG_ 1505 BCM1_FStatus_Aussentemp_ungef 1;
BA_ "GenSigSwitchedByIgnition" SG_ 1505 BCM1_FStatus_Aussentemp_ungef 0;
BA_ "GenSigSendType" SG_ 1505 BCM1_Kompressorstrom_ist 0;
BA_ "GenSigStartValue" SG_ 1505 BCM1_Kompressorstrom_ist 254;
BA_ "GenSigSwitchedByIgnition" SG_ 1505 BCM1_Kompressorstrom_ist 0;
BA_ "Fehlerwert" SG_ 1505 BCM1_Kompressorstrom_ist 255;
BA_ "GenSigSendType" SG_ 1505 BCM1_OBD_FStatus_ATemp 0;
BA_ "GenSigSwitchedByIgnition" SG_ 1505 BCM1_OBD_FStatus_ATemp 0;
BA_ "GenSigSendType" SG_ 1505 BCM1_PTC_stufig_Status 0;
BA_ "GenSigStartValue" SG_ 1505 BCM1_PTC_stufig_Status 6;
BA_ "GenSigSwitchedByIgnition" SG_ 1505 BCM1_PTC_stufig_Status 0;
BA_ "Fehlerwert" SG_ 1505 BCM1_PTC_stufig_Status 7;
BA_ "GenSigSendType" SG_ 1505 BCM_Heizungsabsperrventil_Status 0;
BA_ "GenSigStartValue" SG_ 1505 BCM_Heizungsabsperrventil_Status 2;
BA_ "GenSigSwitchedByIgnition" SG_ 1505 BCM_Heizungsabsperrventil_Status 0;
BA_ "Fehlerwert" SG_ 1505 BCM_Heizungsabsperrventil_Status 3;
BA_ "GenSigSendType" SG_ 1505 BCM_Heizungspumpe_Status 0;
BA_ "GenSigStartValue" SG_ 1505 BCM_Heizungspumpe_Status 2;
BA_ "GenSigSwitchedByIgnition" SG_ 1505 BCM_Heizungspumpe_Status 0;
BA_ "Fehlerwert" SG_ 1505 BCM_Heizungspumpe_Status 3;
BA_ "GenSigSendType" SG_ 1505 BCM_Kompressorkupplung_Status 0;
BA_ "GenSigStartValue" SG_ 1505 BCM_Kompressorkupplung_Status 2;
BA_ "GenSigSwitchedByIgnition" SG_ 1505 BCM_Kompressorkupplung_Status 0;
BA_ "Fehlerwert" SG_ 1505 BCM_Kompressorkupplung_Status 3;
BA_ "GenSigSendType" SG_ 1717 FSA_HW 0;
BA_ "GenSigSendType" SG_ 1717 FSA_Luftfeuchte_rel 0;
BA_ "GenSigStartValue" SG_ 1717 FSA_Luftfeuchte_rel 254;
BA_ "Fehlerwert" SG_ 1717 FSA_Luftfeuchte_rel 255;
BA_ "GenSigSendType" SG_ 1717 FSA_ResponseError 0;
BA_ "Fehlerwert" SG_ 1717 FSA_ResponseError 1;
BA_ "GenSigSendType" SG_ 1717 FSA_Sensorheizung_Status 0;
BA_ "GenSigSendType" SG_ 1717 FSA_SW 0;
BA_ "GenSigSendType" SG_ 1717 FSA_Taupunkt 0;
BA_ "GenSigStartValue" SG_ 1717 FSA_Taupunkt 1022;
BA_ "GenSigSendType" SG_ 1717 FSA_Temp_Luft 0;
BA_ "GenSigStartValue" SG_ 1717 FSA_Temp_Luft 1022;
BA_ "GenSigSendType" SG_ 1717 FSA_Temp_Sensor 0;
BA_ "GenSigStartValue" SG_ 1717 FSA_Temp_Sensor 2046;
BA_ "GenSigSendType" SG_ 1513 AAU_Geblaese 0;
BA_ "GenSigStartValue" SG_ 1513 AAU_Geblaese 126;
BA_ "GenSigSwitchedByIgnition" SG_ 1513 AAU_Geblaese 0;
BA_ "Fehlerwert" SG_ 1513 AAU_Geblaese 127;
BA_ "GenSigSendType" SG_ 1513 DS_Kaeltemittel_P 0;
BA_ "GenSigStartValue" SG_ 1513 DS_Kaeltemittel_P 2046;
BA_ "GenSigSwitchedByIgnition" SG_ 1513 DS_Kaeltemittel_P 0;
BA_ "Fehlerwert" SG_ 1513 DS_Kaeltemittel_P 2047;
BA_ "GenSigSendType" SG_ 1513 DS_Status 0;
BA_ "GenSigStartValue" SG_ 1513 DS_Status 2;
BA_ "GenSigSwitchedByIgnition" SG_ 1513 DS_Status 0;
BA_ "Fehlerwert" SG_ 1513 DS_Status 3;
BA_ "GenSigSendType" SG_ 1513 ION_Status 0;
BA_ "GenSigStartValue" SG_ 1513 ION_Status 2;
BA_ "GenSigSendType" SG_ 1513 ION_Status_LED 0;
BA_ "GenSigSendType" SG_ 1513 ION_Status_Taster 0;
BA_ "GenSigSendType" SG_ 1295 KL_Heizbedarf 0;
BA_ "GenSigStartValue" SG_ 1295 KL_Heizbedarf 1022;
BA_ "GenSigSwitchedByIgnition" SG_ 1295 KL_Heizbedarf 0;
BA_ "Fehlerwert" SG_ 1295 KL_Heizbedarf 1023;
BA_ "GenSigSendType" SG_ 1295 KL_Heizenergie_instat_pred 0;
BA_ "GenSigStartValue" SG_ 1295 KL_Heizenergie_instat_pred 254;
BA_ "GenSigSwitchedByIgnition" SG_ 1295 KL_Heizenergie_instat_pred 0;
BA_ "Fehlerwert" SG_ 1295 KL_Heizenergie_instat_pred 255;
BA_ "GenSigSendType" SG_ 1295 KL_Heizleistg_stat_erw 0;
BA_ "GenSigStartValue" SG_ 1295 KL_Heizleistg_stat_erw 254;
BA_ "GenSigSwitchedByIgnition" SG_ 1295 KL_Heizleistg_stat_erw 0;
BA_ "Fehlerwert" SG_ 1295 KL_Heizleistg_stat_erw 255;
BA_ "GenSigSendType" SG_ 1295 KL_Kuehlbedarf 0;
BA_ "GenSigStartValue" SG_ 1295 KL_Kuehlbedarf 254;
BA_ "GenSigSwitchedByIgnition" SG_ 1295 KL_Kuehlbedarf 0;
BA_ "Fehlerwert" SG_ 1295 KL_Kuehlbedarf 255;
BA_ "GenSigSendType" SG_ 1295 KL_Kuehlenergie_instat_pred 0;
BA_ "GenSigStartValue" SG_ 1295 KL_Kuehlenergie_instat_pred 254;
BA_ "GenSigSwitchedByIgnition" SG_ 1295 KL_Kuehlenergie_instat_pred 0;
BA_ "Fehlerwert" SG_ 1295 KL_Kuehlenergie_instat_pred 255;
BA_ "GenSigSendType" SG_ 1295 KL_Kuehlleistg_stat_erw 0;
BA_ "GenSigStartValue" SG_ 1295 KL_Kuehlleistg_stat_erw 254;
BA_ "GenSigSwitchedByIgnition" SG_ 1295 KL_Kuehlleistg_stat_erw 0;
BA_ "Fehlerwert" SG_ 1295 KL_Kuehlleistg_stat_erw 255;
BA_ "GenSigSendType" SG_ 1295 KL_Leistungspriorisierung 0;
BA_ "GenSigSwitchedByIgnition" SG_ 1295 KL_Leistungspriorisierung 0;
BA_ "GenSigSendType" SG_ 1295 KL_PTC_ein 0;
BA_ "GenSigSwitchedByIgnition" SG_ 1295 KL_PTC_ein 0;
BA_ "GenSigSendType" SG_ 1295 KL_Verdampfertemperatur 0;
BA_ "GenSigStartValue" SG_ 1295 KL_Verdampfertemperatur 1022;
BA_ "GenSigSwitchedByIgnition" SG_ 1295 KL_Verdampfertemperatur 0;
BA_ "Fehlerwert" SG_ 1295 KL_Verdampfertemperatur 1023;
BA_ "GenSigSendType" SG_ 2589283474 KL_Eps_Innen 0;
BA_ "GenSigStartValue" SG_ 2589283474 KL_Eps_Innen 254;
BA_ "GenSigSwitchedByIgnition" SG_ 2589283474 KL_Eps_Innen 0;
BA_ "Fehlerwert" SG_ 2589283474 KL_Eps_Innen 255;
BA_ "GenSigSendType" SG_ 2589283474 KL_Temp_vor_Verdampfer 3;
BA_ "GenSigStartValue" SG_ 2589283474 KL_Temp_vor_Verdampfer 126;
BA_ "GenSigSwitchedByIgnition" SG_ 2589283474 KL_Temp_vor_Verdampfer 0;
BA_ "Fehlerwert" SG_ 2589283474 KL_Temp_vor_Verdampfer 127;
BA_ "GenSigSendType" SG_ 2589283474 KL_Tempklappe_Fond_li 0;
BA_ "GenSigStartValue" SG_ 2589283474 KL_Tempklappe_Fond_li 254;
BA_ "GenSigSwitchedByIgnition" SG_ 2589283474 KL_Tempklappe_Fond_li 0;
BA_ "Fehlerwert" SG_ 2589283474 KL_Tempklappe_Fond_li 255;
BA_ "GenSigSendType" SG_ 2589283474 KL_Tempklappe_Fond_re 0;
BA_ "GenSigStartValue" SG_ 2589283474 KL_Tempklappe_Fond_re 254;
BA_ "GenSigSwitchedByIgnition" SG_ 2589283474 KL_Tempklappe_Fond_re 0;
BA_ "Fehlerwert" SG_ 2589283474 KL_Tempklappe_Fond_re 255;
BA_ "GenSigSendType" SG_ 2549088270 BCM1_Abschaltstufe 0;
BA_ "GenSigSwitchedByIgnition" SG_ 2549088270 BCM1_Abschaltstufe 0;
BA_ "GenSigSendType" SG_ 2549088270 BCM1_KD_Fehler 0;
BA_ "GenSigSwitchedByIgnition" SG_ 2549088270 BCM1_KD_Fehler 0;
BA_ "GenSigSendType" SG_ 2549088270 BCM1_KompSchutz 0;
BA_ "GenSigSwitchedByIgnition" SG_ 2549088270 BCM1_KompSchutz 0;
BA_ "GenSigSendType" SG_ 2549088270 BCM1_Nachlauftyp 0;
BA_ "GenSigStartValue" SG_ 2549088270 BCM1_Nachlauftyp 2;
BA_ "GenSigSwitchedByIgnition" SG_ 2549088270 BCM1_Nachlauftyp 0;
BA_ "GenSigSendType" SG_ 2549088270 BCM1_SNI 0;
BA_ "GenSigStartValue" SG_ 2549088270 BCM1_SNI 14;
BA_ "GenSigSwitchedByIgnition" SG_ 2549088270 BCM1_SNI 0;
BA_ "GenSigSendType" SG_ 2549088270 BCM1_Transport_Mode 0;
BA_ "GenSigSwitchedByIgnition" SG_ 2549088270 BCM1_Transport_Mode 0;
BA_ "GenSigSendType" SG_ 2549088270 KN_BCM1_BusKnockOutTimer 0;
BA_ "GenSigSwitchedByIgnition" SG_ 2549088270 KN_BCM1_BusKnockOutTimer 0;
BA_ "GenSigSendType" SG_ 2549088270 NM_BCM1_Lokalaktiv 0;
BA_ "GenSigSwitchedByIgnition" SG_ 2549088270 NM_BCM1_Lokalaktiv 0;
BA_ "GenSigSendType" SG_ 2549088270 NM_BCM1_Subsystemaktiv 0;
BA_ "GenSigSwitchedByIgnition" SG_ 2549088270 NM_BCM1_Subsystemaktiv 0;
BA_ "GenSigSendType" SG_ 2549088270 NM_BCM1_Wakeup 0;
BA_ "NWM-WakeupAllowed" SG_ 2549088270 NM_BCM1_Wakeup 1;
BA_ "GenSigSwitchedByIgnition" SG_ 2549088270 NM_BCM1_Wakeup 0;
BA_ "GenSigSendType" SG_ 2549088272 Gateway_Abschaltstufe 0;
BA_ "GenSigSwitchedByIgnition" SG_ 2549088272 Gateway_Abschaltstufe 0;
BA_ "GenSigSendType" SG_ 2549088272 Gateway_KompSchutz 0;
BA_ "GenSigSwitchedByIgnition" SG_ 2549088272 Gateway_KompSchutz 0;
BA_ "GenSigSendType" SG_ 2549088272 Gateway_Matrix_Generation 0;
BA_ "GenSigSwitchedByIgnition" SG_ 2549088272 Gateway_Matrix_Generation 0;
BA_ "GenSigSendType" SG_ 2549088272 Gateway_Matrix_Version 0;
BA_ "GenSigSwitchedByIgnition" SG_ 2549088272 Gateway_Matrix_Version 0;
BA_ "GenSigSendType" SG_ 2549088272 Gateway_Nachlauftyp 0;
BA_ "GenSigStartValue" SG_ 2549088272 Gateway_Nachlauftyp 2;
BA_ "GenSigSwitchedByIgnition" SG_ 2549088272 Gateway_Nachlauftyp 0;
BA_ "GenSigSendType" SG_ 2549088272 Gateway_SNI 0;
BA_ "GenSigStartValue" SG_ 2549088272 Gateway_SNI 16;
BA_ "GenSigSwitchedByIgnition" SG_ 2549088272 Gateway_SNI 0;
BA_ "GenSigSendType" SG_ 2549088272 Gateway_Transport_Mode 0;
BA_ "GenSigSwitchedByIgnition" SG_ 2549088272 Gateway_Transport_Mode 0;
BA_ "GenSigSendType" SG_ 2549088272 GW_KD_Fehler 0;
BA_ "GenSigSendType" SG_ 2549088272 NM_Gateway_Lokalaktiv 0;
BA_ "GenSigSwitchedByIgnition" SG_ 2549088272 NM_Gateway_Lokalaktiv 0;
BA_ "GenSigSendType" SG_ 2549088272 NM_Gateway_Subsystemaktiv 0;
BA_ "GenSigSendType" SG_ 2549088272 NM_Gateway_Wakeup 0;
BA_ "NWM-WakeupAllowed" SG_ 2549088272 NM_Gateway_Wakeup 1;
BA_ "GenSigSwitchedByIgnition" SG_ 2549088272 NM_Gateway_Wakeup 0;
BA_ "GenSigSendType" SG_ 2549088326 KL_KD_Fehler 0;
BA_ "GenSigSwitchedByIgnition" SG_ 2549088326 KL_KD_Fehler 0;
BA_ "GenSigSendType" SG_ 2549088326 Klima_Abschaltstufe 0;
BA_ "GenSigSwitchedByIgnition" SG_ 2549088326 Klima_Abschaltstufe 0;
BA_ "GenSigSendType" SG_ 2549088326 Klima_KompSchutz 0;
BA_ "GenSigSwitchedByIgnition" SG_ 2549088326 Klima_KompSchutz 0;
BA_ "GenSigSendType" SG_ 2549088326 Klima_Nachlauftyp 0;
BA_ "GenSigStartValue" SG_ 2549088326 Klima_Nachlauftyp 2;
BA_ "GenSigSwitchedByIgnition" SG_ 2549088326 Klima_Nachlauftyp 0;
BA_ "GenSigSendType" SG_ 2549088326 Klima_SNI 0;
BA_ "GenSigStartValue" SG_ 2549088326 Klima_SNI 70;
BA_ "GenSigSwitchedByIgnition" SG_ 2549088326 Klima_SNI 0;
BA_ "GenSigSendType" SG_ 2549088326 Klima_Transport_Mode 0;
BA_ "GenSigSwitchedByIgnition" SG_ 2549088326 Klima_Transport_Mode 0;
BA_ "GenSigSendType" SG_ 2549088326 KN_Klima_BusKnockOut 0;
BA_ "GenSigSwitchedByIgnition" SG_ 2549088326 KN_Klima_BusKnockOut 0;
BA_ "GenSigSendType" SG_ 2549088326 KN_Klima_BusKnockOutTimer 0;
BA_ "GenSigSwitchedByIgnition" SG_ 2549088326 KN_Klima_BusKnockOutTimer 0;
BA_ "GenSigSendType" SG_ 2549088326 KN_Klima_ECUKnockOut 0;
BA_ "GenSigSwitchedByIgnition" SG_ 2549088326 KN_Klima_ECUKnockOut 0;
BA_ "GenSigSendType" SG_ 2549088326 KN_Klima_ECUKnockOutTimer 0;
BA_ "GenSigSwitchedByIgnition" SG_ 2549088326 KN_Klima_ECUKnockOutTimer 0;
BA_ "GenSigSendType" SG_ 2549088326 NM_Klima_Lokalaktiv 0;
BA_ "GenSigSwitchedByIgnition" SG_ 2549088326 NM_Klima_Lokalaktiv 0;
BA_ "GenSigSendType" SG_ 2549088326 NM_Klima_Subsystemaktiv 0;
BA_ "GenSigSwitchedByIgnition" SG_ 2549088326 NM_Klima_Subsystemaktiv 0;
BA_ "GenSigSendType" SG_ 2549088326 NM_Klima_Wakeup 0;
BA_ "NWM-WakeupAllowed" SG_ 2549088326 NM_Klima_Wakeup 1;
BA_ "GenSigSwitchedByIgnition" SG_ 2549088326 NM_Klima_Wakeup 0;
BA_ "GenSigSendType" SG_ 2549088345 Lift_Abschaltstufe 0;
BA_ "GenSigSendType" SG_ 2549088345 Lift_KD_Fehler 0;
BA_ "GenSigSendType" SG_ 2549088345 Lift_KompSchutz 0;
BA_ "GenSigSendType" SG_ 2549088345 Lift_Lokalaktiv 0;
BA_ "GenSigSwitchedByIgnition" SG_ 2549088345 Lift_Lokalaktiv 0;
BA_ "GenSigSendType" SG_ 2549088345 Lift_Nachlauftyp 0;
BA_ "GenSigSendType" SG_ 2549088345 Lift_SNI 0;
BA_ "GenSigStartValue" SG_ 2549088345 Lift_SNI 89;
BA_ "GenSigSendType" SG_ 2549088345 Lift_Subsystemaktiv 0;
BA_ "GenSigSwitchedByIgnition" SG_ 2549088345 Lift_Subsystemaktiv 0;
BA_ "GenSigSendType" SG_ 2549088345 Lift_Transport_Mode 0;
BA_ "GenSigSendType" SG_ 2549088345 NM_Lift_Wakeup 0;
BA_ "NWM-WakeupAllowed" SG_ 2549088345 NM_Lift_Wakeup 1;
BA_ "GenSigSwitchedByIgnition" SG_ 2549088345 NM_Lift_Wakeup 0;
BA_ "GenSigSendType" SG_ 2549088452 NM_VAS_L_Lokalaktiv 0;
BA_ "GenSigSwitchedByIgnition" SG_ 2549088452 NM_VAS_L_Lokalaktiv 0;
BA_ "GenSigSendType" SG_ 2549088452 NM_VAS_L_Wakeup 0;
BA_ "NWM-WakeupAllowed" SG_ 2549088452 NM_VAS_L_Wakeup 1;
BA_ "GenSigSwitchedByIgnition" SG_ 2549088452 NM_VAS_L_Wakeup 0;
BA_ "GenSigSendType" SG_ 2549088452 VAS_L_Abschaltstufe 0;
BA_ "GenSigSendType" SG_ 2549088452 VAS_L_KD_Fehler 0;
BA_ "GenSigSwitchedByIgnition" SG_ 2549088452 VAS_L_KD_Fehler 0;
BA_ "GenSigSendType" SG_ 2549088452 VAS_L_KompSchutz 0;
BA_ "GenSigSendType" SG_ 2549088452 VAS_L_Nachlauftyp 0;
BA_ "GenSigStartValue" SG_ 2549088452 VAS_L_Nachlauftyp 2;
BA_ "GenSigSendType" SG_ 2549088452 VAS_L_SNI 0;
BA_ "GenSigStartValue" SG_ 2549088452 VAS_L_SNI 196;
BA_ "GenSigSwitchedByIgnition" SG_ 2549088452 VAS_L_SNI 0;
BA_ "GenSigSendType" SG_ 2549088452 VAS_L_Subsystemaktiv 0;
BA_ "GenSigSwitchedByIgnition" SG_ 2549088452 VAS_L_Subsystemaktiv 0;
BA_ "GenSigSendType" SG_ 2549088452 VAS_L_Transport_Mode 0;
BA_ "GenSigSendType" SG_ 2549088453 NM_VAS_R_Lokalaktiv 0;
BA_ "GenSigSwitchedByIgnition" SG_ 2549088453 NM_VAS_R_Lokalaktiv 0;
BA_ "GenSigSendType" SG_ 2549088453 NM_VAS_R_Wakeup 0;
BA_ "NWM-WakeupAllowed" SG_ 2549088453 NM_VAS_R_Wakeup 1;
BA_ "GenSigSwitchedByIgnition" SG_ 2549088453 NM_VAS_R_Wakeup 0;
BA_ "GenSigSendType" SG_ 2549088453 VAS_R_Abschaltstufe 0;
BA_ "GenSigSendType" SG_ 2549088453 VAS_R_KD_Fehler 0;
BA_ "GenSigSwitchedByIgnition" SG_ 2549088453 VAS_R_KD_Fehler 0;
BA_ "GenSigSendType" SG_ 2549088453 VAS_R_KompSchutz 0;
BA_ "GenSigSendType" SG_ 2549088453 VAS_R_Nachlauftyp 0;
BA_ "GenSigStartValue" SG_ 2549088453 VAS_R_Nachlauftyp 2;
BA_ "GenSigSendType" SG_ 2549088453 VAS_R_SNI 0;
BA_ "GenSigStartValue" SG_ 2549088453 VAS_R_SNI 197;
BA_ "GenSigSwitchedByIgnition" SG_ 2549088453 VAS_R_SNI 0;
BA_ "GenSigSendType" SG_ 2549088453 VAS_R_Subsystemaktiv 0;
BA_ "GenSigSwitchedByIgnition" SG_ 2549088453 VAS_R_Subsystemaktiv 0;
BA_ "GenSigSendType" SG_ 2549088453 VAS_R_Transport_Mode 0;
BA_ "GenSigSendType" SG_ 779 KBI_ABS_Lampe 0;
BA_ "GenSigSwitchedByIgnition" SG_ 779 KBI_ABS_Lampe 0;
BA_ "GenSigSendType" SG_ 779 KBI_Airbag_Lampe 0;
BA_ "GenSigSwitchedByIgnition" SG_ 779 KBI_Airbag_Lampe 0;
BA_ "GenSigSendType" SG_ 779 KBI_angez_Geschw 0;
BA_ "GenSigSwitchedByIgnition" SG_ 779 KBI_angez_Geschw 0;
BA_ "GenSigSendType" SG_ 779 KBI_Anzeigefehler_LDW 0;
BA_ "GenSigSwitchedByIgnition" SG_ 779 KBI_Anzeigefehler_LDW 0;
BA_ "GenSigSendType" SG_ 779 KBI_Anzeigefehler_NV 0;
BA_ "GenSigSwitchedByIgnition" SG_ 779 KBI_Anzeigefehler_NV 0;
BA_ "GenSigSendType" SG_ 779 KBI_Anzeigefehler_SWA 0;
BA_ "GenSigSwitchedByIgnition" SG_ 779 KBI_Anzeigefehler_SWA 0;
BA_ "GenSigSendType" SG_ 779 KBI_Anzeigestatus_ACC 0;
BA_ "GenSigSwitchedByIgnition" SG_ 779 KBI_Anzeigestatus_ACC 0;
BA_ "GenSigSendType" SG_ 779 KBI_Anzeigestatus_GRA 0;
BA_ "GenSigSwitchedByIgnition" SG_ 779 KBI_Anzeigestatus_GRA 0;
BA_ "Fehlerwert" SG_ 779 KBI_Anzeigestatus_GRA 3;
BA_ "GenSigSendType" SG_ 779 KBI_Anzeigestatus_LIM 0;
BA_ "GenSigSwitchedByIgnition" SG_ 779 KBI_Anzeigestatus_LIM 0;
BA_ "Fehlerwert" SG_ 779 KBI_Anzeigestatus_LIM 3;
BA_ "GenSigSendType" SG_ 779 KBI_ARA_in_Anzeige 0;
BA_ "GenSigSwitchedByIgnition" SG_ 779 KBI_ARA_in_Anzeige 0;
BA_ "GenSigSendType" SG_ 779 KBI_BKL_Lampe 0;
BA_ "GenSigSwitchedByIgnition" SG_ 779 KBI_BKL_Lampe 0;
BA_ "GenSigSendType" SG_ 779 KBI_Einheit_Tacho 0;
BA_ "GenSigSwitchedByIgnition" SG_ 779 KBI_Einheit_Tacho 0;
BA_ "GenSigSendType" SG_ 779 KBI_ESP_Lampe 3;
BA_ "GenSigSwitchedByIgnition" SG_ 779 KBI_ESP_Lampe 0;
BA_ "GenSigSendType" SG_ 779 KBI_Fehler_Anzeige_ACC 0;
BA_ "GenSigSwitchedByIgnition" SG_ 779 KBI_Fehler_Anzeige_ACC 0;
BA_ "GenSigSendType" SG_ 779 KBI_Handbremse 0;
BA_ "GenSigSwitchedByIgnition" SG_ 779 KBI_Handbremse 0;
BA_ "GenSigSendType" SG_ 779 KBI_im_Stellgliedtest 0;
BA_ "GenSigSwitchedByIgnition" SG_ 779 KBI_im_Stellgliedtest 0;
BA_ "GenSigSendType" SG_ 779 KBI_Konsistenz_ACC 0;
BA_ "GenSigSwitchedByIgnition" SG_ 779 KBI_Konsistenz_ACC 0;
BA_ "GenSigSendType" SG_ 779 KBI_Lenkung_Lampe 3;
BA_ "GenSigSwitchedByIgnition" SG_ 779 KBI_Lenkung_Lampe 0;
BA_ "GenSigSendType" SG_ 779 KBI_MFA_v_Einheit_01 0;
BA_ "GenSigSwitchedByIgnition" SG_ 779 KBI_MFA_v_Einheit_01 0;
BA_ "GenSigSendType" SG_ 779 KBI_NV_in_Anzeige 0;
BA_ "GenSigSwitchedByIgnition" SG_ 779 KBI_NV_in_Anzeige 0;
BA_ "GenSigSendType" SG_ 779 KBI_PLA_in_Anzeige 3;
BA_ "GenSigSwitchedByIgnition" SG_ 779 KBI_PLA_in_Anzeige 0;
BA_ "GenSigSendType" SG_ 779 KBI_SILA_gueltig 0;
BA_ "GenSigSwitchedByIgnition" SG_ 779 KBI_SILA_gueltig 0;
BA_ "GenSigSendType" SG_ 779 KBI_Systemstatus 0;
BA_ "GenSigSwitchedByIgnition" SG_ 779 KBI_Systemstatus 0;
BA_ "GenSigSendType" SG_ 779 KBI_Tankwarnung 3;
BA_ "GenSigSwitchedByIgnition" SG_ 779 KBI_Tankwarnung 0;
BA_ "GenSigSendType" SG_ 779 KBI_Tankwarnung_ungueltig 0;
BA_ "GenSigStartValue" SG_ 779 KBI_Tankwarnung_ungueltig 1;
BA_ "GenSigSwitchedByIgnition" SG_ 779 KBI_Tankwarnung_ungueltig 0;
BA_ "GenSigSendType" SG_ 779 KBI_Taster_Fahrwerk 3;
BA_ "GenSigSwitchedByIgnition" SG_ 779 KBI_Taster_Fahrwerk 0;
BA_ "GenSigSendType" SG_ 779 KBI_Taster_Lift 3;
BA_ "GenSigSwitchedByIgnition" SG_ 779 KBI_Taster_Lift 0;
BA_ "GenSigSendType" SG_ 779 KBI_V_Digital 0;
BA_ "GenSigSwitchedByIgnition" SG_ 779 KBI_V_Digital 0;
BA_ "GenSigSendType" SG_ 779 KBI_Vorglueh_System_Lampe 0;
BA_ "GenSigSwitchedByIgnition" SG_ 779 KBI_Vorglueh_System_Lampe 0;
BA_ "GenSigSendType" SG_ 779 Kombi_01_BZ 0;
BA_ "GenSigFuncType" SG_ 779 Kombi_01_BZ 1;
BA_ "GenSigSwitchedByIgnition" SG_ 779 Kombi_01_BZ 0;
BA_ "GenSigSendType" SG_ 1719 KBI_aktive_Laengsfunktion 3;
BA_ "GenSigSendType" SG_ 1719 KBI_Aussen_Temp_gef 0;
BA_ "GenSigStartValue" SG_ 1719 KBI_Aussen_Temp_gef 254;
BA_ "GenSigSwitchedByIgnition" SG_ 1719 KBI_Aussen_Temp_gef 0;
BA_ "Fehlerwert" SG_ 1719 KBI_Aussen_Temp_gef 255;
BA_ "GenSigSendType" SG_ 1719 KBI_FStatus_Tank 0;
BA_ "GenSigSwitchedByIgnition" SG_ 1719 KBI_FStatus_Tank 0;
BA_ "GenSigSendType" SG_ 1719 KBI_GRA_im_ACC 3;
BA_ "GenSigSwitchedByIgnition" SG_ 1719 KBI_GRA_im_ACC 0;
BA_ "GenSigSendType" SG_ 1719 KBI_Inhalt_Tank 0;
BA_ "GenSigStartValue" SG_ 1719 KBI_Inhalt_Tank 126;
BA_ "GenSigSwitchedByIgnition" SG_ 1719 KBI_Inhalt_Tank 0;
BA_ "Fehlerwert" SG_ 1719 KBI_Inhalt_Tank 127;
BA_ "GenSigSendType" SG_ 1719 KBI_Kilometerstand 0;
BA_ "GenSigStartValue" SG_ 1719 KBI_Kilometerstand 1048574;
BA_ "GenSigSwitchedByIgnition" SG_ 1719 KBI_Kilometerstand 0;
BA_ "Fehlerwert" SG_ 1719 KBI_Kilometerstand 1048575;
BA_ "GenSigSendType" SG_ 1719 KBI_LVDS_Lock 3;
BA_ "GenSigSwitchedByIgnition" SG_ 1719 KBI_LVDS_Lock 0;
BA_ "GenSigSendType" SG_ 1719 KBI_Oelwechsel_durchgefuehrt 0;
BA_ "GenSigSwitchedByIgnition" SG_ 1719 KBI_Oelwechsel_durchgefuehrt 0;
BA_ "GenSigSendType" SG_ 1719 KBI_QBit_Aussen_Temp_gef 0;
BA_ "GenSigStartValue" SG_ 1719 KBI_QBit_Aussen_Temp_gef 1;
BA_ "GenSigSwitchedByIgnition" SG_ 1719 KBI_QBit_Aussen_Temp_gef 0;
BA_ "GenSigSendType" SG_ 1719 KBI_RDK_Kalibrier_Anf 3;
BA_ "GenSigSwitchedByIgnition" SG_ 1719 KBI_RDK_Kalibrier_Anf 0;
BA_ "GenSigSendType" SG_ 1719 KBI_Reserve_Warnung_Sek 3;
BA_ "GenSigSwitchedByIgnition" SG_ 1719 KBI_Reserve_Warnung_Sek 0;
BA_ "GenSigSendType" SG_ 1719 KBI_Standzeit_02 0;
BA_ "GenSigStartValue" SG_ 1719 KBI_Standzeit_02 131070;
BA_ "GenSigSwitchedByIgnition" SG_ 1719 KBI_Standzeit_02 0;
BA_ "Fehlerwert" SG_ 1719 KBI_Standzeit_02 131071;
BA_ "GenSigSendType" SG_ 2549874958 KS_BCM1_Req_Data 3;
BA_ "GenSigFuncType" SG_ 2549874958 KS_BCM1_Req_Data 9;
BA_ "GenSigSwitchedByIgnition" SG_ 2549874958 KS_BCM1_Req_Data 0;
BA_ "GenSigSendType" SG_ 2550006030 KS_BCM1_Resp_Data 3;
BA_ "GenSigFuncType" SG_ 2550006030 KS_BCM1_Resp_Data 9;
BA_ "GenSigSwitchedByIgnition" SG_ 2550006030 KS_BCM1_Resp_Data 0;
BA_ "GenSigSendType" SG_ 2549875140 KS_VAS_L_Req_Data 3;
BA_ "GenSigSwitchedByIgnition" SG_ 2549875140 KS_VAS_L_Req_Data 0;
BA_ "GenSigSendType" SG_ 2550006212 KS_VAS_L_Resp_Data 3;
BA_ "GenSigSwitchedByIgnition" SG_ 2550006212 KS_VAS_L_Resp_Data 0;
BA_ "GenSigSendType" SG_ 2549875141 KS_VAS_R_Req_Data 3;
BA_ "GenSigSwitchedByIgnition" SG_ 2549875141 KS_VAS_R_Req_Data 0;
BA_ "GenSigSendType" SG_ 2550006213 KS_VAS_R_Resp_Data 3;
BA_ "GenSigSwitchedByIgnition" SG_ 2550006213 KS_VAS_R_Resp_Data 0;
BA_ "GenSigSendType" SG_ 919 aLDW_FoD_Status 3;
BA_ "GenSigSwitchedByIgnition" SG_ 919 aLDW_FoD_Status 0;
BA_ "GenSigSendType" SG_ 919 EA_Warnblinken 0;
BA_ "GenSigSendType" SG_ 919 HC_Uss_Anforderung 0;
BA_ "GenSigSwitchedByIgnition" SG_ 919 HC_Uss_Anforderung 0;
BA_ "GenSigSendType" SG_ 919 LDW_Codierinfo_fuer_VLR 0;
BA_ "GenSigSendType" SG_ 919 LDW_DLC 0;
BA_ "GenSigStartValue" SG_ 919 LDW_DLC 250;
BA_ "GenSigSendType" SG_ 919 LDW_Frueh_Spaet 0;
BA_ "GenSigStartValue" SG_ 919 LDW_Frueh_Spaet 2;
BA_ "Fehlerwert" SG_ 919 LDW_Frueh_Spaet 3;
BA_ "GenSigSendType" SG_ 919 LDW_Gong 0;
BA_ "GenSigSendType" SG_ 919 LDW_Lernmodus 0;
BA_ "GenSigSendType" SG_ 919 LDW_Lernmodus_seitenabhaengig 3;
BA_ "GenSigSendType" SG_ 919 LDW_Seite_DLCTLC 0;
BA_ "GenSigSendType" SG_ 919 LDW_Status_LED_gelb 0;
BA_ "GenSigSendType" SG_ 919 LDW_Status_LED_gruen 0;
BA_ "GenSigSendType" SG_ 919 LDW_Texte 0;
BA_ "GenSigSendType" SG_ 919 LDW_TLC 0;
BA_ "GenSigStartValue" SG_ 919 LDW_TLC 31;
BA_ "GenSigSendType" SG_ 919 LKS_LED_an 0;
BA_REL_ "GenSigTimeoutTime" BU_SG_REL_ BCM1 SG_ 960 Klemmen_Status_01_CRC 1000;
BA_REL_ "GenSigTimeoutTime" BU_SG_REL_ BCM1 SG_ 960 Klemmen_Status_01_BZ 1000;
BA_REL_ "GenSigTimeoutTime" BU_SG_REL_ BCM1 SG_ 960 ZAS_Kl_S 1000;
BA_REL_ "GenSigTimeoutTime" BU_SG_REL_ BCM1 SG_ 960 ZAS_Kl_15 1000;
BA_REL_ "GenSigTimeoutTime" BU_SG_REL_ BCM1 SG_ 960 ZAS_Kl_50_Startanforderung 1000;
BA_REL_ "GenSigTimeoutTime" BU_SG_REL_ BCM1 SG_ 960 BCM_Remotestart_Betrieb 1000;
BA_REL_ "GenSigTimeoutTime" BU_SG_REL_ BCM1 SG_ 960 BCM_Remotestart_KL15_Anf 1000;
BA_REL_ "GenSigTimeoutTime" BU_SG_REL_ BCM1 SG_ 1420 KST_aut_Abschaltung_Zuendung 5000;
BA_REL_ "GenSigTimeoutTime" BU_SG_REL_ BCM1 SG_ 1420 Relais_VoKo_angesteuert 5000;
BA_REL_ "GenSigTimeoutTime" BU_SG_REL_ BCM1 SG_ 1646 KL_STH_aktiv 5000;
BA_REL_ "GenSigTimeoutTime" BU_SG_REL_ BCM1 SG_ 1646 KL_Geblaese_Fond_Status 5000;
BA_REL_ "GenSigTimeoutTime" BU_SG_REL_ BCM1 SG_ 1646 KL_Geblaese_Status 5000;
BA_REL_ "GenSigTimeoutTime" BU_SG_REL_ BCM1 SG_ 1646 KL_Kompressorkupplung 5000;
BA_REL_ "GenSigTimeoutTime" BU_SG_REL_ BCM1 SG_ 1646 KL_ErwVK_Anf 5000;
BA_REL_ "GenSigTimeoutTime" BU_SG_REL_ BCM1 SG_ 1646 KL_Innen_Temp 5000;
BA_REL_ "GenSigTimeoutTime" BU_SG_REL_ BCM1 SG_ 1646 KL_SIH_LEH_Verteilung_VL 5000;
BA_REL_ "GenSigTimeoutTime" BU_SG_REL_ BCM1 SG_ 1646 KL_SIH_LEL_Verteilung_VL 5000;
BA_REL_ "GenSigTimeoutTime" BU_SG_REL_ BCM1 SG_ 1646 KL_SIH_LEH_Verteilung_VR 5000;
BA_REL_ "GenSigTimeoutTime" BU_SG_REL_ BCM1 SG_ 1646 KL_SIH_LEL_Verteilung_VR 5000;
BA_REL_ "GenSigTimeoutTime" BU_SG_REL_ BCM1 SG_ 1608 KL_SL_HL_Soll 5000;
BA_REL_ "GenSigTimeoutTime" BU_SG_REL_ BCM1 SG_ 1608 KL_SL_HR_Soll 5000;
BA_REL_ "GenSigTimeoutTime" BU_SG_REL_ BCM1 SG_ 1608 KL_SH_HR_Soll 5000;
BA_REL_ "GenSigTimeoutTime" BU_SG_REL_ BCM1 SG_ 1608 KL_SH_HL_Soll 5000;
BA_REL_ "GenSigTimeoutTime" BU_SG_REL_ BCM1 SG_ 949 KL_Kompressorkupplung_linear 1000;
BA_REL_ "GenSigTimeoutTime" BU_SG_REL_ BCM1 SG_ 949 KL_el_Zuheizer_Stufe 1000;
BA_REL_ "GenSigTimeoutTime" BU_SG_REL_ BCM1 SG_ 949 KL_Ausstattung_Klima 1000;
BA_REL_ "GenSigTimeoutTime" BU_SG_REL_ BCM1 SG_ 1640 KL_SIH_Soll_li 2000;
BA_REL_ "GenSigTimeoutTime" BU_SG_REL_ BCM1 SG_ 1640 KL_SIH_Soll_re 2000;
BA_REL_ "GenSigTimeoutTime" BU_SG_REL_ BCM1 SG_ 1640 KL_SIL_Soll_li 2000;
BA_REL_ "GenSigTimeoutTime" BU_SG_REL_ BCM1 SG_ 1640 KL_SIL_Soll_re 2000;
BA_REL_ "GenSigTimeoutTime" BU_SG_REL_ BCM1 SG_ 1640 KL_Kompressorstrom_soll 2000;
BA_REL_ "GenSigTimeoutTime" BU_SG_REL_ BCM1 SG_ 1441 KL_Temp_Soll_hl 5000;
BA_REL_ "GenSigTimeoutTime" BU_SG_REL_ BCM1 SG_ 1441 KL_Temp_Soll_hr 5000;
BA_REL_ "GenSigTimeoutTime" BU_SG_REL_ BCM1 SG_ 1441 KL_Temp_Soll_vl 5000;
BA_REL_ "GenSigTimeoutTime" BU_SG_REL_ BCM1 SG_ 1441 KL_Temp_Soll_vr 5000;
BA_REL_ "GenSigTimeoutTime" BU_SG_REL_ BCM1 SG_ 1441 KL_SIH_Stufe_hl 5000;
BA_REL_ "GenSigTimeoutTime" BU_SG_REL_ BCM1 SG_ 1441 KL_SIH_Stufe_hr 5000;
BA_REL_ "GenSigTimeoutTime" BU_SG_REL_ BCM1 SG_ 1441 KL_SIL_Stufe_hl 5000;
BA_REL_ "GenSigTimeoutTime" BU_SG_REL_ BCM1 SG_ 1441 KL_SIL_Stufe_hr 5000;
BA_REL_ "GenSigTimeoutTime" BU_SG_REL_ BCM1 SG_ 1441 KL_SIL_LEL_Verteilung_HR 5000;
BA_REL_ "GenSigTimeoutTime" BU_SG_REL_ BCM1 SG_ 1441 KL_SIL_LEL_Verteilung_HL 5000;
BA_REL_ "GenSigTimeoutTime" BU_SG_REL_ BCM1 SG_ 1441 KL_SIH_LEH_Verteilung_HR 5000;
BA_REL_ "GenSigTimeoutTime" BU_SG_REL_ BCM1 SG_ 1441 KL_SIH_LEH_Verteilung_HL 5000;
BA_REL_ "GenSigTimeoutTime" BU_SG_REL_ BCM1 SG_ 2589283621 KL_FlHz_Soll_VL 5000;
BA_REL_ "GenSigTimeoutTime" BU_SG_REL_ BCM1 SG_ 2589283621 KL_FlHz_Soll_HL 5000;
BA_REL_ "GenSigTimeoutTime" BU_SG_REL_ BCM1 SG_ 2589283621 KL_FlHz_Soll_VR 5000;
BA_REL_ "GenSigTimeoutTime" BU_SG_REL_ BCM1 SG_ 2589283621 KL_FlHz_Soll_HR 5000;
BA_REL_ "GenSigTimeoutTime" BU_SG_REL_ BCM1 SG_ 992 KL_SL_Soll_hl 1000;
BA_REL_ "GenSigTimeoutTime" BU_SG_REL_ BCM1 SG_ 992 KL_SL_Soll_hr 1000;
BA_REL_ "GenSigTimeoutTime" BU_SG_REL_ BCM1 SG_ 992 KL_SH_Soll_hl 1000;
BA_REL_ "GenSigTimeoutTime" BU_SG_REL_ BCM1 SG_ 992 KL_SH_Soll_hr 1000;
BA_REL_ "GenSigTimeoutTime" BU_SG_REL_ BCM1 SG_ 779 KBI_ESP_Lampe 2000;
BA_REL_ "GenSigTimeoutTime" BU_SG_REL_ BCM1 SG_ 779 KBI_Tankwarnung 2000;
BA_REL_ "GenSigTimeoutTime" BU_SG_REL_ BCM1 SG_ 779 KBI_PLA_in_Anzeige 2000;
BA_REL_ "GenSigTimeoutTime" BU_SG_REL_ BCM1 SG_ 779 KBI_ARA_in_Anzeige 2000;
BA_REL_ "GenSigTimeoutTime" BU_SG_REL_ BCM1 SG_ 1719 KBI_Standzeit_02 5000;
BA_REL_ "GenSigTimeoutTime" BU_SG_REL_ BCM1 SG_ 1719 KBI_QBit_Aussen_Temp_gef 5000;
BA_REL_ "GenSigTimeoutTime" BU_SG_REL_ BCM1 SG_ 1719 KBI_Aussen_Temp_gef 5000;
BA_REL_ "GenSigTimeoutTime" BU_SG_REL_ BCM1 SG_ 919 HC_Uss_Anforderung 800;
BA_REL_ "GenSigTimeoutTime" BU_SG_REL_ BCM1 SG_ 919 LKS_LED_an 800;
BA_REL_ "GenSigTimeoutTime" BU_SG_REL_ Gateway SG_ 1646 KL_STH_aktiv 5000;
BA_REL_ "GenSigTimeoutTime" BU_SG_REL_ Gateway SG_ 1646 KL_Geblaese_Fond_Status 5000;
BA_REL_ "GenSigTimeoutTime" BU_SG_REL_ Gateway SG_ 1646 KL_Geblaese_Status 5000;
BA_REL_ "GenSigTimeoutTime" BU_SG_REL_ Gateway SG_ 1646 KL_BCmE_Livetip_Freigabe 5000;
BA_REL_ "GenSigTimeoutTime" BU_SG_REL_ Gateway SG_ 1646 KL_Status_Beduftung 5000;
BA_REL_ "GenSigTimeoutTime" BU_SG_REL_ Gateway SG_ 1646 KL_Status_Ionisator_Front 5000;
BA_REL_ "GenSigTimeoutTime" BU_SG_REL_ Gateway SG_ 1646 KL_ErwVK_Anf 5000;
BA_REL_ "GenSigTimeoutTime" BU_SG_REL_ Gateway SG_ 1646 KL_Innen_Temp 5000;
BA_REL_ "GenSigTimeoutTime" BU_SG_REL_ Gateway SG_ 1646 KL_SIH_LEH_Verteilung_VL 5000;
BA_REL_ "GenSigTimeoutTime" BU_SG_REL_ Gateway SG_ 1646 KL_SIH_LEL_Verteilung_VL 5000;
BA_REL_ "GenSigTimeoutTime" BU_SG_REL_ Gateway SG_ 1646 KL_SIH_LEH_Verteilung_VR 5000;
BA_REL_ "GenSigTimeoutTime" BU_SG_REL_ Gateway SG_ 1646 KL_SIH_LEL_Verteilung_VR 5000;
BA_REL_ "GenSigTimeoutTime" BU_SG_REL_ Gateway SG_ 1649 KL_Stopp_Wiederstart_Anz_01 5000;
BA_REL_ "GenSigTimeoutTime" BU_SG_REL_ Gateway SG_ 1649 KL_Stopp_Wiederstart_Anz_02 5000;
BA_REL_ "GenSigTimeoutTime" BU_SG_REL_ Gateway SG_ 1649 KL_Stopp_Wiederstart_Anz_03 5000;
BA_REL_ "GenSigTimeoutTime" BU_SG_REL_ Gateway SG_ 1649 KL_Stopp_Wiederstart_Anz_04 5000;
BA_REL_ "GenSigTimeoutTime" BU_SG_REL_ Gateway SG_ 1649 KL_Stopp_Wiederstart_Anz_05 5000;
BA_REL_ "GenSigTimeoutTime" BU_SG_REL_ Gateway SG_ 1649 KL_Stopp_Wiederstart_Anz_06 5000;
BA_REL_ "GenSigTimeoutTime" BU_SG_REL_ Gateway SG_ 1649 KL_Stopp_Wiederstart_Anz_07 5000;
BA_REL_ "GenSigTimeoutTime" BU_SG_REL_ Gateway SG_ 1649 KL_Stopp_Wiederstart_Anz_08 5000;
BA_REL_ "GenSigTimeoutTime" BU_SG_REL_ Gateway SG_ 1649 KL_Stopp_Wiederstart_Anz_09 5000;
BA_REL_ "GenSigTimeoutTime" BU_SG_REL_ Gateway SG_ 1649 KL_Stopp_Wiederstart_Anz_Std1 5000;
BA_REL_ "GenSigTimeoutTime" BU_SG_REL_ Gateway SG_ 1649 KL_Stopp_Wiederstart_Anz_Std2 5000;
BA_REL_ "GenSigTimeoutTime" BU_SG_REL_ Gateway SG_ 1608 KL_SL_HL_Soll 5000;
BA_REL_ "GenSigTimeoutTime" BU_SG_REL_ Gateway SG_ 1608 KL_SL_HR_Soll 5000;
BA_REL_ "GenSigTimeoutTime" BU_SG_REL_ Gateway SG_ 1608 KL_SH_HR_Soll 5000;
BA_REL_ "GenSigTimeoutTime" BU_SG_REL_ Gateway SG_ 1608 KL_SH_HL_Soll 5000;
BA_REL_ "GenSigTimeoutTime" BU_SG_REL_ Gateway SG_ 949 KL_AC_Schalter 1000;
BA_REL_ "GenSigTimeoutTime" BU_SG_REL_ Gateway SG_ 949 KL_Zustand 1000;
BA_REL_ "GenSigTimeoutTime" BU_SG_REL_ Gateway SG_ 949 KL_Charisma_FahrPr 1000;
BA_REL_ "GenSigTimeoutTime" BU_SG_REL_ Gateway SG_ 949 KL_Charisma_Status 1000;
BA_REL_ "GenSigTimeoutTime" BU_SG_REL_ Gateway SG_ 949 KL_Spannungs_Anf 1000;
BA_REL_ "GenSigTimeoutTime" BU_SG_REL_ Gateway SG_ 949 KL_StartStopp_Info 1000;
BA_REL_ "GenSigTimeoutTime" BU_SG_REL_ Gateway SG_ 949 KL_Anf_KL 1000;
BA_REL_ "GenSigTimeoutTime" BU_SG_REL_ Gateway SG_ 949 KL_el_Zuheizer_Stufe 1000;
BA_REL_ "GenSigTimeoutTime" BU_SG_REL_ Gateway SG_ 949 KL_Ausstattung_Klima 1000;
BA_REL_ "GenSigTimeoutTime" BU_SG_REL_ Gateway SG_ 1640 KL_LRH_Taster 2000;
BA_REL_ "GenSigTimeoutTime" BU_SG_REL_ Gateway SG_ 1640 KL_LRH_Stufe 2000;
BA_REL_ "GenSigTimeoutTime" BU_SG_REL_ Gateway SG_ 1640 HSH_Taster 2000;
BA_REL_ "GenSigTimeoutTime" BU_SG_REL_ Gateway SG_ 1640 FSH_Taster 2000;
BA_REL_ "GenSigTimeoutTime" BU_SG_REL_ Gateway SG_ 1640 KL_SIH_Soll_li 2000;
BA_REL_ "GenSigTimeoutTime" BU_SG_REL_ Gateway SG_ 1640 KL_SIH_Soll_re 2000;
BA_REL_ "GenSigTimeoutTime" BU_SG_REL_ Gateway SG_ 1640 KRH_Soll_li 2000;
BA_REL_ "GenSigTimeoutTime" BU_SG_REL_ Gateway SG_ 1640 KL_SIL_Soll_li 2000;
BA_REL_ "GenSigTimeoutTime" BU_SG_REL_ Gateway SG_ 1640 KL_SIL_Soll_re 2000;
BA_REL_ "GenSigTimeoutTime" BU_SG_REL_ Gateway SG_ 1640 KRH_Soll_re 2000;
BA_REL_ "GenSigTimeoutTime" BU_SG_REL_ Gateway SG_ 1640 KL_I_Geblaese 2000;
BA_REL_ "GenSigTimeoutTime" BU_SG_REL_ Gateway SG_ 1441 KL_SIH_Stufe_hl 5000;
BA_REL_ "GenSigTimeoutTime" BU_SG_REL_ Gateway SG_ 1441 KL_SIH_Stufe_hr 5000;
BA_REL_ "GenSigTimeoutTime" BU_SG_REL_ Gateway SG_ 1441 KL_SIL_Stufe_hl 5000;
BA_REL_ "GenSigTimeoutTime" BU_SG_REL_ Gateway SG_ 1441 KL_SIL_Stufe_hr 5000;
BA_REL_ "GenSigTimeoutTime" BU_SG_REL_ Gateway SG_ 1441 KL_PTC_linear_Anf 5000;
BA_REL_ "GenSigTimeoutTime" BU_SG_REL_ Gateway SG_ 2589283469 KL_VK_Anf 5000;
BA_REL_ "GenSigTimeoutTime" BU_SG_REL_ Gateway SG_ 2589283469 KL_Geblaese_Fond_erw 5000;
BA_REL_ "GenSigTimeoutTime" BU_SG_REL_ Gateway SG_ 2589283469 KL_Geblaese_erw 5000;
BA_REL_ "GenSigTimeoutTime" BU_SG_REL_ Gateway SG_ 2589283469 KL_Vorkond_Strategie 5000;
BA_REL_ "GenSigTimeoutTime" BU_SG_REL_ Gateway SG_ 2589283621 KL_NV_Energie_Anf 5000;
BA_REL_ "GenSigTimeoutTime" BU_SG_REL_ Gateway SG_ 2589283621 KL_FlHz_Soll_VL 5000;
BA_REL_ "GenSigTimeoutTime" BU_SG_REL_ Gateway SG_ 2589283621 KL_FlHz_Soll_HL 5000;
BA_REL_ "GenSigTimeoutTime" BU_SG_REL_ Gateway SG_ 2589283621 KL_FlHz_Soll_VR 5000;
BA_REL_ "GenSigTimeoutTime" BU_SG_REL_ Gateway SG_ 2589283621 KL_FlHz_Soll_HR 5000;
BA_REL_ "GenSigTimeoutTime" BU_SG_REL_ Gateway SG_ 2589283621 KL_ACmax_Aktiv 5000;
BA_REL_ "GenSigTimeoutTime" BU_SG_REL_ Gateway SG_ 2589283621 KL_ECO_Aktiv 5000;
BA_REL_ "GenSigTimeoutTime" BU_SG_REL_ Gateway SG_ 992 KL_SL_Soll_hl 1000;
BA_REL_ "GenSigTimeoutTime" BU_SG_REL_ Gateway SG_ 992 KL_SL_Soll_hr 1000;
BA_REL_ "GenSigTimeoutTime" BU_SG_REL_ Gateway SG_ 992 KL_SH_Soll_hl 1000;
BA_REL_ "GenSigTimeoutTime" BU_SG_REL_ Gateway SG_ 992 KL_SH_Soll_hr 1000;
BA_REL_ "GenSigTimeoutTime" BU_SG_REL_ Gateway SG_ 1505 BCM1_Aussen_Temp_ungef 2000;
BA_REL_ "GenSigTimeoutTime" BU_SG_REL_ Gateway SG_ 1505 BCM1_PTC_stufig_Status 2000;
BA_REL_ "GenSigTimeoutTime" BU_SG_REL_ Gateway SG_ 1513 DS_Kaeltemittel_P 2000;
BA_REL_ "GenSigTimeoutTime" BU_SG_REL_ Gateway SG_ 1513 ION_Status 2000;
BA_REL_ "GenSigTimeoutTime" BU_SG_REL_ Gateway SG_ 1513 ION_Status_LED 2000;
BA_REL_ "GenSigTimeoutTime" BU_SG_REL_ Gateway SG_ 1513 AAU_Geblaese 2000;
BA_REL_ "GenSigTimeoutTime" BU_SG_REL_ Gateway SG_ 1513 ION_Status_Taster 2000;
BA_REL_ "GenSigTimeoutTime" BU_SG_REL_ Gateway SG_ 1295 KL_Kuehlleistg_stat_erw 1000;
BA_REL_ "GenSigTimeoutTime" BU_SG_REL_ Gateway SG_ 2549088270 BCM1_Nachlauftyp 5000;
BA_REL_ "GenSigTimeoutTime" BU_SG_REL_ Gateway SG_ 2549088270 BCM1_SNI 5000;
BA_REL_ "GenSigTimeoutTime" BU_SG_REL_ Gateway SG_ 2549088270 KN_BCM1_BusKnockOutTimer 5000;
BA_REL_ "GenSigTimeoutTime" BU_SG_REL_ Gateway SG_ 2549088270 NM_BCM1_Lokalaktiv 5000;
BA_REL_ "GenSigTimeoutTime" BU_SG_REL_ Gateway SG_ 2549088270 NM_BCM1_Subsystemaktiv 5000;
BA_REL_ "GenSigTimeoutTime" BU_SG_REL_ Gateway SG_ 2549088270 BCM1_KD_Fehler 2500;
BA_REL_ "GenSigTimeoutTime" BU_SG_REL_ Gateway SG_ 2549088326 Klima_Nachlauftyp 5000;
BA_REL_ "GenSigTimeoutTime" BU_SG_REL_ Gateway SG_ 2549088326 Klima_SNI 5000;
BA_REL_ "GenSigTimeoutTime" BU_SG_REL_ Gateway SG_ 2549088326 KN_Klima_ECUKnockOutTimer 5000;
BA_REL_ "GenSigTimeoutTime" BU_SG_REL_ Gateway SG_ 2549088326 KN_Klima_BusKnockOut 5000;
BA_REL_ "GenSigTimeoutTime" BU_SG_REL_ Gateway SG_ 2549088326 KN_Klima_BusKnockOutTimer 5000;
BA_REL_ "GenSigTimeoutTime" BU_SG_REL_ Gateway SG_ 2549088326 KN_Klima_ECUKnockOut 5000;
BA_REL_ "GenSigTimeoutTime" BU_SG_REL_ Gateway SG_ 2549088326 NM_Klima_Lokalaktiv 5000;
BA_REL_ "GenSigTimeoutTime" BU_SG_REL_ Gateway SG_ 2549088326 NM_Klima_Subsystemaktiv 5000;
BA_REL_ "GenSigTimeoutTime" BU_SG_REL_ Gateway SG_ 2549088326 KL_KD_Fehler 2500;
BA_REL_ "GenSigTimeoutTime" BU_SG_REL_ Gateway SG_ 2549088345 Lift_Nachlauftyp 5000;
BA_REL_ "GenSigTimeoutTime" BU_SG_REL_ Gateway SG_ 2549088345 Lift_SNI 5000;
BA_REL_ "GenSigTimeoutTime" BU_SG_REL_ Gateway SG_ 2549088345 Lift_Lokalaktiv 5000;
BA_REL_ "GenSigTimeoutTime" BU_SG_REL_ Gateway SG_ 2549088345 Lift_Subsystemaktiv 5000;
BA_REL_ "GenSigTimeoutTime" BU_SG_REL_ Gateway SG_ 2549088345 Lift_KD_Fehler 2500;
BA_REL_ "GenSigTimeoutTime" BU_SG_REL_ Gateway SG_ 2549088452 VAS_L_Nachlauftyp 5000;
BA_REL_ "GenSigTimeoutTime" BU_SG_REL_ Gateway SG_ 2549088452 VAS_L_SNI 5000;
BA_REL_ "GenSigTimeoutTime" BU_SG_REL_ Gateway SG_ 2549088452 NM_VAS_L_Lokalaktiv 5000;
BA_REL_ "GenSigTimeoutTime" BU_SG_REL_ Gateway SG_ 2549088452 VAS_L_KD_Fehler 2500;
BA_REL_ "GenSigTimeoutTime" BU_SG_REL_ Gateway SG_ 2549088453 VAS_R_Nachlauftyp 5000;
BA_REL_ "GenSigTimeoutTime" BU_SG_REL_ Gateway SG_ 2549088453 VAS_R_SNI 5000;
BA_REL_ "GenSigTimeoutTime" BU_SG_REL_ Gateway SG_ 2549088453 NM_VAS_R_Lokalaktiv 5000;
BA_REL_ "GenSigTimeoutTime" BU_SG_REL_ Gateway SG_ 2549088453 VAS_R_KD_Fehler 2500;
BA_REL_ "GenSigTimeoutTime" BU_SG_REL_ Klima_MSB SG_ 960 ZAS_Kl_S 1000;
BA_REL_ "GenSigTimeoutTime" BU_SG_REL_ Klima_MSB SG_ 960 ZAS_Kl_15 1000;
BA_REL_ "GenSigTimeoutTime" BU_SG_REL_ Klima_MSB SG_ 960 ZAS_Kl_50_Startanforderung 1000;
BA_REL_ "GenSigTimeoutTime" BU_SG_REL_ Klima_MSB SG_ 960 BCM_Remotestart_Betrieb 1000;
BA_REL_ "GenSigTimeoutTime" BU_SG_REL_ Klima_MSB SG_ 1712 FS_Taupunkt 5000;
BA_REL_ "GenSigTimeoutTime" BU_SG_REL_ Klima_MSB SG_ 1712 FS_ResponseError 5000;
BA_REL_ "GenSigTimeoutTime" BU_SG_REL_ Klima_MSB SG_ 1712 FS_Temp_Scheibe 5000;
BA_REL_ "GenSigTimeoutTime" BU_SG_REL_ Klima_MSB SG_ 1712 FS_Temp_Sensor 5000;
BA_REL_ "GenSigTimeoutTime" BU_SG_REL_ Klima_MSB SG_ 1712 FS_Luftfeuchte_rel 5000;
BA_REL_ "GenSigTimeoutTime" BU_SG_REL_ Klima_MSB SG_ 1505 BCM1_Aussen_Temp_ungef 2000;
BA_REL_ "GenSigTimeoutTime" BU_SG_REL_ Klima_MSB SG_ 1505 BCM_Heizungsabsperrventil_Status 2000;
BA_REL_ "GenSigTimeoutTime" BU_SG_REL_ Klima_MSB SG_ 1505 BCM_Heizungspumpe_Status 2000;
BA_REL_ "GenSigTimeoutTime" BU_SG_REL_ Klima_MSB SG_ 1505 BCM_Kompressorkupplung_Status 2000;
BA_REL_ "GenSigTimeoutTime" BU_SG_REL_ Klima_MSB SG_ 1505 BCM1_PTC_stufig_Status 2000;
BA_REL_ "GenSigTimeoutTime" BU_SG_REL_ Klima_MSB SG_ 1505 BCM1_FStatus_Aussentemp_ungef 2000;
BA_REL_ "GenSigTimeoutTime" BU_SG_REL_ Klima_MSB SG_ 1505 BCM1_Kompressorstrom_ist 2000;
BA_REL_ "GenSigTimeoutTime" BU_SG_REL_ Klima_MSB SG_ 1505 BCM1_OBD_FStatus_ATemp 2000;
BA_REL_ "GenSigTimeoutTime" BU_SG_REL_ Klima_MSB SG_ 779 KBI_Tankwarnung 2000;
BA_REL_ "GenSigTimeoutTime" BU_SG_REL_ Klima_MSB SG_ 1719 KBI_Standzeit_02 5000;
BA_REL_ "GenSigTimeoutTime" BU_SG_REL_ Klima_MSB SG_ 1719 KBI_QBit_Aussen_Temp_gef 5000;
BA_REL_ "GenSigTimeoutTime" BU_SG_REL_ Klima_MSB SG_ 1719 KBI_Aussen_Temp_gef 5000;
BA_REL_ "GenSigTimeoutTime" BU_SG_REL_ Lift_VA SG_ 960 Klemmen_Status_01_CRC 1000;
BA_REL_ "GenSigTimeoutTime" BU_SG_REL_ Lift_VA SG_ 960 Klemmen_Status_01_BZ 1000;
BA_REL_ "GenSigTimeoutTime" BU_SG_REL_ Lift_VA SG_ 960 ZAS_Kl_15 1000;
BA_REL_ "GenSigTimeoutTime" BU_SG_REL_ Lift_VA SG_ 1719 KBI_Aussen_Temp_gef 5000;
BA_REL_ "GenSigTimeoutTime" BU_SG_REL_ VAS_L SG_ 960 ZAS_Kl_S 1000;
BA_REL_ "GenSigTimeoutTime" BU_SG_REL_ VAS_L SG_ 960 ZAS_Kl_15 1000;
BA_REL_ "GenSigTimeoutTime" BU_SG_REL_ VAS_L SG_ 1505 BCM1_Aussen_Temp_ungef 2000;
BA_REL_ "GenSigTimeoutTime" BU_SG_REL_ VAS_L SG_ 1505 BCM1_FStatus_Aussentemp_ungef 2000;
BA_REL_ "GenSigTimeoutTime" BU_SG_REL_ VAS_L SG_ 1719 KBI_Aussen_Temp_gef 5000;
BA_REL_ "GenSigTimeoutTime" BU_SG_REL_ VAS_R SG_ 960 ZAS_Kl_S 1000;
BA_REL_ "GenSigTimeoutTime" BU_SG_REL_ VAS_R SG_ 960 ZAS_Kl_15 1000;
BA_REL_ "GenSigTimeoutTime" BU_SG_REL_ VAS_R SG_ 1505 BCM1_Aussen_Temp_ungef 2000;
BA_REL_ "GenSigTimeoutTime" BU_SG_REL_ VAS_R SG_ 1505 BCM1_FStatus_Aussentemp_ungef 2000;
BA_REL_ "GenSigTimeoutTime" BU_SG_REL_ VAS_R SG_ 1719 KBI_Kilometerstand 5000;
BA_REL_ "GenSigTimeoutTime" BU_SG_REL_ VAS_R SG_ 1719 KBI_Aussen_Temp_gef 5000;
VAL_ 960 RSt_Fahrerhinweise 0 "Init" 1 "Fahreruebernahme_Hinweis_ZAT_Automat_ohne_Gong" 2 "Fahreruebernahme_Hinweis_ZAT_Automat_mit_Gong" 3 "Fahreruebernahme_Hinweis_ZAT_Handschalter_ohne_Gong" 4 "Fahreruebernahme_Hinweis_ZAT_Handschalter_mit_Gong" 5 "Fahreruebernahme_Hinweis_ZAS_Automat_ohne_Gong" 6 "Fahreruebernahme_Hinweis_ZAS_Automat_mit_Gong" 7 "Fahreruebernahme_Hinweis_ZAS_Handschalter_ohne_Gong" 8 "Fahreruebernahme_Hinweis_ZAS_Handschalter_mit_Gong" 9 "RemoteStart_aktiv_ohne_Gong" 10 "RemoteStart_aktiv_mit_Gong" 11 "void" 12 "void" 13 "void" 14 "void" 15 "void" ;
VAL_ 960 ZAS_Kl_S 0 "aus" 1 "S_Kontakt_ein" ;
VAL_ 960 ZAS_Kl_15 0 "aus" 1 "ein" ;
VAL_ 960 ZAS_Kl_X 0 "aus" 1 "ein" ;
VAL_ 960 ZAS_Kl_50_Startanforderung 0 "aus" 1 "KL50_ein_Startwunsch_Fahrer" ;
VAL_ 960 BCM_Remotestart_Betrieb 0 "kein_RS_Betrieb" 1 "RS_Betrieb" ;
VAL_ 960 ZAS_Kl_Infotainment 0 "inaktiv" 1 "aktiv" ;
VAL_ 960 BCM_Remotestart_KL15_Anf 0 "inaktiv" 1 "aktiv" ;
VAL_ 960 BCM_Remotestart_MO_Start 0 "nicht_angefordert" 1 "angefordert" ;
VAL_ 960 KST_Warn_P1_ZST_def 0 "nicht_defekt" 1 "defekt" ;
VAL_ 960 KST_Warn_P2_ZST_def 0 "nicht_defekt" 1 "defekt" ;
VAL_ 960 KST_Fahrerhinweis_1 0 "inaktiv" 1 "aktiv" ;
VAL_ 960 KST_Fahrerhinweis_2 0 "inaktiv" 1 "aktiv" ;
VAL_ 960 BCM_Ausparken_Betrieb 0 "kein_Betrieb" 1 "Ausparkvorgang_aktiv" ;
VAL_ 960 KST_Fahrerhinweis_4 0 "inaktiv" 1 "aktiv" ;
VAL_ 960 KST_Fahrerhinweis_5 0 "inaktiv" 1 "aktiv" ;
VAL_ 960 KST_Fahrerhinweis_6 0 "inaktiv" 1 "aktiv" ;
VAL_ 1420 KST_Txt_P_Gang 0 "Aus" 1 "Ein" ;
VAL_ 1420 KST_Txt_Panikabschaltung 0 "Aus" 1 "Ein" ;
VAL_ 1420 KST_Anf_Klemmenfreigabe_ELV 0 "nicht_angefordert" 1 "angefordert" ;
VAL_ 1420 KST_Txt_Komfortabschaltung 0 "inaktiv" 1 "aktiv" ;
VAL_ 1420 KST_Unterdr_Zuendungsmeldung 0 "keine_Unterdr_der_Zuendungsmeldung" 1 "Unterdr_der_Zuendungsmeldung_aktiv" ;
VAL_ 1420 KST_aut_Abschaltung_Zuendung 0 "Zuendung_wird_bei_Verl_nicht_deaktiviert" 1 "Zuendung_wird_bei_Verl_deaktiviert" ;
VAL_ 1420 KST_Anf_ZV_Verriegelung 0 "inaktiv" 1 "aktiv" ;
VAL_ 1420 Relais_VoKo_angesteuert 0 "nicht_angesteuert" 1 "angesteuert" ;
VAL_ 1420 RSt_Anforderung_HMS 0 "keine_Anforderung" 1 "halten" 2 "parken" 3 "halten_Standby" 4 "anfahren" 5 "Loesen_ueber_Rampe" 6 "Parken_mit_P" ;
VAL_ 1646 KL_STL_aktiv 0 "Standlueftung_nicht_aktiv" 1 "Standlueftung_aktiv" ;
VAL_ 1646 KL_STH_aktiv 0 "Standheizung_nicht_aktiv" 1 "Standheizung_aktiv" ;
VAL_ 1646 KL_Solarluefter_aktiv 0 "Solarluefter_nicht_aktiv" 1 "Solarluefter_aktiv__auto" ;
VAL_ 1646 KL_Umluft_Taste 0 "Taste_nicht_gedrueckt" 1 "Taste_gedrueckt" ;
VAL_ 1646 KL_Geblaese_Fond_Status 0 "Geblaese_aus" 1 "Geblaesestufe_10" 2 "Geblaesestufe_20" 3 "Geblaesestufe_30" 4 "Geblaesestufe_40" 5 "Geblaesestufe_50" 6 "Geblaesestufe_60" 7 "Geblaesestufe_70" 8 "Geblaesestufe_80" 9 "Geblaesestufe_90" 10 "Geblaesestufe_100" 14 "Init" 15 "Fehler" ;
VAL_ 1646 KL_STH_Ansteuerung 0 "Aus" 1 "Ein" 2 "Ein_mit_Motorvorwaermung" 3 "Heizleistung_reduziert" ;
VAL_ 1646 KL_Magnetventil 0 "Aus" 1 "Ein" ;
VAL_ 1646 KL_WaPu 0 "Wasserpumpe_aus" 1 "Wasserpumpe_aktiv" ;
VAL_ 1646 KL_Geblaese_Status 0 "Geblaese_aus" 1 "Geblaesestufe_10" 2 "Geblaesestufe_20" 3 "Geblaesestufe_30" 4 "Geblaesestufe_40" 5 "Geblaesestufe_50" 6 "Geblaesestufe_60" 7 "Geblaesestufe_70" 8 "Geblaesestufe_80" 9 "Geblaesestufe_90" 10 "Geblaesestufe_100" 14 "Init" 15 "Fehler" ;
VAL_ 1646 KL_Restwaerme_aktiv 0 "inaktiv" 1 "aktiv" ;
VAL_ 1646 KL_Kompressorkupplung 0 "oeffnen" 1 "schliessen" ;
VAL_ 1646 KL_BCmE_Livetip_Freigabe 0 "Anzeige_Livetip_nicht_zulaessig" 1 "Anzeige_Livetip_zulaessig" ;
VAL_ 1646 KL_HYB_ASV_hinten_schliessen_Anf 0 "keine_Anforderung" 1 "Ventil_schliessen" ;
VAL_ 1646 KL_HYB_ASV_vorne_schliessen_Anf 0 "keine_Anforderung" 1 "Ventil_schliessen" ;
VAL_ 1646 KL_ErwVK_Zusatzrelais 0 "nicht_angefordert" 1 "angefordert" ;
VAL_ 1646 KL_Status_Beduftung 0 "inaktiv" 1 "aktiv" ;
VAL_ 1646 KL_Status_Ionisator_Front 0 "inaktiv" 1 "aktiv" ;
VAL_ 1646 KL_STH_Timer_Status 0 "TimerInaktiv" 1 "TimerAktiv" ;
VAL_ 1646 KL_ErwVK_Anf 0 "nicht_angefordert" 1 "angefordert" ;
VAL_ 1646 KL_Innen_Temp 253 "nicht_verbaut" 254 "nicht_verfuegbar" 255 "Fehler" ;
VAL_ 1646 KL_I_Geblaese_Fond 255 "Fehler" ;
VAL_ 1646 KL_Anf_AussenspiegelHzg 0 "nicht_angefordert" 1 "angefordert" ;
VAL_ 1646 KL_Heizkreisventilstellung 0 "Init" 1 "Ventilstellung_gem_Anforderung" 2 "Ventilstellung_abweichend_Anf" 3 "Fehler" ;
VAL_ 1646 KL_FSH_Automatikbetrieb 0 "aus" 1 "angefordert_durch_Regelung" ;
VAL_ 1646 KL_SIH_LEH_Verteilung_VL 0 "gleichmaessige_Verteilung" 1 "Sitz_Prio_Hoch" 2 "Sitz_Prio_Mittel" 3 "Sitz_Prio_Niedrig" 4 "Lehne_Prio_Niedrig" 5 "Lehne_Prio_Mittel" 6 "Lehne_Prio_Hoch" ;
VAL_ 1646 KL_SIH_LEL_Verteilung_VL 0 "gleichmaessige_Verteilung" 1 "Sitz_Prio_Hoch" 2 "Sitz_Prio_Mittel" 3 "Sitz_Prio_Niedrig" 4 "Lehne_Prio_Niedrig" 5 "Lehne_Prio_Mittel" 6 "Lehne_Prio_Hoch" ;
VAL_ 1646 KL_SIH_LEH_Verteilung_VR 0 "gleichmaessige_Verteilung" 1 "Sitz_Prio_Hoch" 2 "Sitz_Prio_Mittel" 3 "Sitz_Prio_Niedrig" 4 "Lehne_Prio_Niedrig" 5 "Lehne_Prio_Mittel" 6 "Lehne_Prio_Hoch" ;
VAL_ 1646 KL_SIH_LEL_Verteilung_VR 0 "gleichmaessige_Verteilung" 1 "Sitz_Prio_Hoch" 2 "Sitz_Prio_Mittel" 3 "Sitz_Prio_Niedrig" 4 "Lehne_Prio_Niedrig" 5 "Lehne_Prio_Mittel" 6 "Lehne_Prio_Hoch" ;
VAL_ 1663 KL_Mod_Display_li 0 "Solltemperatur" 1 "Luftverteilung" 2 "Sitzheizung" 3 "Sitzlueftung" 4 "Luftmenge" 9 "OBD" 10 "Display_off" ;
VAL_ 1663 KL_Mod_Display_re 0 "Solltemperatur" 1 "Luftverteilung" 2 "Sitzheizung" 3 "Sitzlueftung" 4 "Luftmenge" 9 "OBD" 10 "Display_off" ;
VAL_ 1663 KL_Fondbed_vorne_aktiv 0 "nicht_aktiv" 1 "Bedienung_von_vorne_ist_aktiv" ;
VAL_ 1663 KL_Fond_re_reduziert 1 "Leistungsreduzierung" ;
VAL_ 1663 KL_Fond_li_reduziert 1 "Leistungsreduzierung" ;
VAL_ 1663 KL_Absperrventil_Fond 0 "nicht_ansteuern" 1 "ansteuern" ;
VAL_ 1663 KL_SH_HL_Lastabschaltung 0 "keine_Einschraenkung" 1 "Taktung" 2 "Abschaltung" ;
VAL_ 1663 KL_SH_HR_Lastabschaltung 0 "keine_Einschraenkung" 1 "Taktung" 2 "Abschaltung" ;
VAL_ 1663 KL_Sollausblastemp_HL 1023 "Fehler" ;
VAL_ 1663 KL_Einheiten 0 "°C" 1 "°F" ;
VAL_ 1663 KL_Kindersicherung 0 "nicht_aktiv" 1 "aktiv" ;
VAL_ 1663 KL_Heizverbraucher_aus 0 "keine_Einschraenkung" 1 "Heizverbraucher_deaktivieren" ;
VAL_ 1663 KL_Heizverbraucher_Notaus 0 "keine_Einschraenkung" 1 "Heizverbraucher_sofort_deaktivieren" ;
VAL_ 1663 KL_Gebl_Verst_Abs_Modus 0 "Aus" 1 "Ein" ;
VAL_ 1663 KL_Sollausblastemp_HR 1023 "Fehler" ;
VAL_ 1663 KL_ICO2_Sensor_defekt 0 "Init" 1 "nicht_defekt" 2 "defekt" 3 "CO2_Warnung" ;
VAL_ 1663 KL_Umluft 254 "Init" 255 "Fehler" ;
VAL_ 1649 KL_ZZ_Status_Timer 0 "Timer_n_aktiv_bzw_loeschen" 1 "Timer_aktiv_bzw_aktivieren" ;
VAL_ 1649 KL_ZZ_Monat 0 "Init" ;
VAL_ 1649 KL_ZZ_Betriebsmodus 0 "Do_not_Care" 1 "ECO" 2 "Standard" 3 "Standard_plus" 4 "Comfort" ;
VAL_ 1649 KL_ZZ_Tag 0 "Init" ;
VAL_ 1649 KL_Betriebsmodus_FH 0 "undefined__init" 1 "Klemme15" 2 "Standheizung" 3 "Restwaerme" 4 "Nachlauf" 5 "Standlueften" 6 "Betriebsart_X" 7 "Betriebsart_Y" ;
VAL_ 1649 KL_Stopp_Wiederstart_Anz_01 0 "keine_Anzeige" 1 "Geblaese" ;
VAL_ 1649 KL_Stopp_Wiederstart_Anz_02 0 "keine_Anzeige" 1 "Differenz_Soll_Ausblas_zu_Ist_Ausblastemperatur" ;
VAL_ 1649 KL_Stopp_Wiederstart_Anz_03 0 "keine_Anzeige" 1 "Beschlagsgefahr" ;
VAL_ 1649 KL_Stopp_Wiederstart_Anz_04 0 "keine_Anzeige" 1 "Differenz_Soll_Innentemperatur_zu_Ist_Innenraumtemperatur" ;
VAL_ 1649 KL_Stopp_Wiederstart_Anz_05 0 "keine_Anzeige" 1 "Komfortfeuchte" ;
VAL_ 1649 KL_Stopp_Wiederstart_Anz_06 0 "keine_Anzeige" 1 "Aussentemperatur" ;
VAL_ 1649 KL_Stopp_Wiederstart_Anz_07 0 "keine_Anzeige" 1 "Defrost" ;
VAL_ 1649 KL_Stopp_Wiederstart_Anz_08 0 "keine_Anzeige" 1 "High_Low" ;
VAL_ 1649 KL_Stopp_Wiederstart_Anz_09 0 "keine_Anzeige" 1 "Frontscheibenheizung" ;
VAL_ 1649 KL_Stopp_Wiederstart_Anz_Std1 0 "keine_Anzeige" 1 "maxA/C" ;
VAL_ 1649 KL_Stopp_Wiederstart_Anz_Std2 0 "keine_Anzeige" 1 "Sitzlueftung" ;
VAL_ 1608 KL_AUTO_HL_Soll 0 "AUTO_nicht_aktiv" 1 "AUTO_aktiv" ;
VAL_ 1608 KL_AUTO_HR_Soll 0 "AUTO_nicht_aktiv" 1 "AUTO_aktiv" ;
VAL_ 1608 KL_AC_Fond_Soll 0 "AC_nicht_aktiv" 1 "AC_aktiv" ;
VAL_ 1608 KL_Fondbedienung_aktiv 0 "nicht_aktiv" 1 "aktiv" ;
VAL_ 1608 KL_Status_Soll 0 "AUS" 1 "EIN" ;
VAL_ 1608 KL_Luftverteilung_HR_Soll 0 "MA" 1 "Fussraum" 2 "PfostenB" 3 "MA+Fuß" 4 "MA+PfostenB" 5 "Fuß+PfostenB" 6 "MA+Fuß+PfostenB" 7 "AUTO-LV" ;
VAL_ 1608 KL_Luftverteilung_HL_Soll 0 "MA" 1 "Fussraum" 2 "PfostenB" 3 "MA+Fuß" 4 "MA+PfostenB" 5 "Fuß+PfostenB" 6 "MA+Fuß+PfostenB" 7 "AUTO-LV" ;
VAL_ 949 KL_Drehz_Anh 0 "keine_Anhebung" 1 "Drehzahlanhebung_vom_Motor_angefordert" ;
VAL_ 949 KL_Vorwarn_Komp_ein 0 "Init" 1 "Vorwarnung_Kompressor_ein" ;
VAL_ 949 KL_AC_Schalter 0 "aus" 1 "ein" ;
VAL_ 949 KL_Komp_Moment_alt 1 "veraltet_bzw_Ermittlung_des_Moments_nicht_moeglich__zB_keine_Drehzahl_kein_Kaeltemitteldruck" ;
VAL_ 949 KL_Vorwarn_Zuheizer_ein 0 "keine_Vorwarnung" 1 "Vorwarnung_Zuheizer_ein" ;
VAL_ 949 KL_Zustand 0 "Aus" 1 "Ein" ;
VAL_ 949 KL_Kompressorkupplung_linear 253 "volle_Ansteuerung" 254 "Init__nicht_bedient" ;
VAL_ 949 KL_Charisma_FahrPr 0 "keine_Funktion" 1 "Programm_1" 2 "Programm_2" 3 "Programm_3" 4 "Programm_4" 5 "Programm_5" 6 "Programm_6" 7 "Programm_7" 8 "Programm_8" 9 "Programm_9" 10 "Programm_10" 11 "Programm_11" 12 "Programm_12" 13 "Programm_13" 14 "Programm_14" 15 "Programm_15" ;
VAL_ 949 KL_Charisma_Status 0 "Init" 1 "verfuegbar" 2 "nicht_verfuegbar" 3 "asynchron_durch_Fahrerwunsch" ;
VAL_ 949 KL_nachtr_Stopp_Anf 0 "nicht_angefordert" 1 "angefordert" ;
VAL_ 949 KL_T_Charge 0 "Taster_nicht_betaetigt" 1 "Taster_betaetigt" ;
VAL_ 949 KL_Last_Kompr 255 "Fehler" ;
VAL_ 949 KL_Spannungs_Anf 0 "keine_Anforderung" 1 "Anforderung_Stufe_1" 2 "Anforderung_Stufe_2" 3 "Anforderung_Stufe_3" ;
VAL_ 949 KL_Thermomanagement 0 "keine_Freigabe_TMM__max_Heizbedarf" 1 "kleine_Freigabe_TMM" 2 "mittlere_Freigabe_TMM" 3 "volle_Freigabe_TMM__kein_Heizbedarf" ;
VAL_ 949 KL_StartStopp_Info 0 "Motorlauf_nicht_notwendig_(Stoppfreigabe)" 1 "Motoranlauf_nicht_zwingend_notwendig_(Stoppverbot,keine_Startanforderung)" 2 "Motoranlauf_zwingend_notwendig_(Startanforderung)" 3 "Systemfehler" ;
VAL_ 949 KL_Freilauf_Info 0 "Freilauf_freigegeben" 1 "Uebergang_in_Freilauf_unzulaessig" 2 "Freilauf_nicht_freigegeben_Abbruch" 3 "Freilauf_Anforderung" ;
VAL_ 949 KL_Anf_KL 255 "Fehler" ;
VAL_ 949 KL_el_Zuheizer_Stufe 0 "Aus" 1 "Stufe_1" 2 "Stufe_2" 3 "Stufe_3" ;
VAL_ 949 KL_Ausstattung_Klima 0 "Heizung_elektrisch" 1 "Klimamanuell_elektrisch" 2 "Climatic__1_Zone" 3 "Climatronic__1_Zone" 4 "Climatronic__2_Zonen" 5 "Climatronic__3_Zonen" 6 "Climatronic__4_Zonen" 7 "reserviert" ;
VAL_ 949 KL_Variante_Standheizung 0 "Wasserstandheizung_60_min_Laufzeit" 1 "Luftstandheizung_120_min_Laufzeit" 2 "Wasserstandheizung_120_min_Laufzeit" 3 "Wasser_und_Luftstandheizung_120_min_Laufzeit" ;
VAL_ 1640 KL_LRH_Taster 0 "nicht_betaetigt" 1 "betaetigt" ;
VAL_ 1640 KL_LRH_Stufe 0 "Stufe_niedrig" 1 "Stufe_mittel" 2 "Stufe_hoch" 3 "AUS" ;
VAL_ 1640 HSH_Taster 0 "nicht_betaetigt" 1 "short_push" 2 "long_push" 3 "tbd" ;
VAL_ 1640 FSH_Taster 0 "nicht_betaetigt" 1 "betaetigt" ;
VAL_ 1640 KL_Zuheizer_Freigabe 0 "keine_Freigabe_Zuheizer" 1 "Zuheizerfreigabe" ;
VAL_ 1640 KL_Beschlagsgefahr 0 "keine_Beschlagsgefahr" 1 "Beschlagsgefahr" ;
VAL_ 1640 KRH_Soll_li 0 "aus" 1 "Stufe_1" 2 "Stufe_2" 3 "Stufe_3" ;
VAL_ 1640 KRH_Soll_re 0 "aus" 1 "Stufe_1" 2 "Stufe_2" 3 "Stufe_3" ;
VAL_ 1640 KL_Geblspng_Soll 0 "0V_Motorspannung" 252 "0V_sofort_Abschalten" 253 "0V_senken_mit_Rampe" 254 "reserviert" 255 "Fehler" ;
VAL_ 1640 KL_Geblspng_Fond_Soll 0 "0V_Motorspannung" 252 "0V_sofort_Abschalten" 253 "0V_senken_mit_Rampe" 254 "reserviert" 255 "Fehler" ;
VAL_ 1640 KL_I_Geblaese 255 "Fehler" ;
VAL_ 1640 KL_Kompressorstrom_soll 1022 "Init" 1023 "Fehler" ;
VAL_ 1640 KL_Umluftklappe_Status 0 "Frischluft" 1 "Teilumluft_10" 2 "Teilumluft_20" 3 "Teilumluft_30" 4 "Teilumluft_40" 5 "Teilumluft_50" 6 "Teilumluft_60" 7 "Teilumluft_70" 8 "Teilumluft_80" 9 "Teilumluft_90" 10 "Umluft" 14 "Init" 15 "Fehler" ;
VAL_ 1640 KL_PTC_Verbauinfo 0 "kein_PTC" 1 "600W_geschaltet" 2 "1000W_geschaltet" 3 "1400W_LIN" ;
VAL_ 1441 KL_Temp_Soll_hl 30 "Klima_OFF" 31 "Init" ;
VAL_ 1441 KL_Temp_Soll_hr 30 "Klima_OFF" 31 "Init" ;
VAL_ 1441 KL_Temp_Soll_vl 30 "Klima_OFF" 31 "Init" ;
VAL_ 1441 KL_Temp_Soll_vr 30 "Klima_OFF" 31 "Init" ;
VAL_ 1441 KL_SIH_Stufe_hl 7 "nicht_verbaut" ;
VAL_ 1441 KL_SIH_Stufe_hr 7 "nicht_verbaut" ;
VAL_ 1441 KL_SIL_Stufe_hl 7 "nicht_verbaut" ;
VAL_ 1441 KL_SIL_Stufe_hr 7 "nicht_verbaut" ;
VAL_ 1441 KL_SIL_LEL_Verteilung_HR 0 "gleichmaessige_Verteilung" 1 "Sitz_Prio_Hoch" 2 "Sitz_Prio_Mittel" 3 "Sitz_Prio_Niedrig" 4 "Lehne_Prio_Niedrig" 5 "Lehne_Prio_Mittel" 6 "Lehne_Prio_Hoch" ;
VAL_ 1441 KL_SIL_LEL_Verteilung_HL 0 "gleichmaessige_Verteilung" 1 "Sitz_Prio_Hoch" 2 "Sitz_Prio_Mittel" 3 "Sitz_Prio_Niedrig" 4 "Lehne_Prio_Niedrig" 5 "Lehne_Prio_Mittel" 6 "Lehne_Prio_Hoch" ;
VAL_ 1441 KL_SIH_LEH_Verteilung_HR 0 "gleichmaessige_Verteilung" 1 "Sitz_Prio_Hoch" 2 "Sitz_Prio_Mittel" 3 "Sitz_Prio_Niedrig" 4 "Lehne_Prio_Niedrig" 5 "Lehne_Prio_Mittel" 6 "Lehne_Prio_Hoch" ;
VAL_ 1441 KL_PTC_linear_Anf 0 "Init" 63 "Fehler" ;
VAL_ 1441 KL_SIH_LEH_Verteilung_HL 0 "gleichmaessige_Verteilung" 1 "Sitz_Prio_Hoch" 2 "Sitz_Prio_Mittel" 3 "Sitz_Prio_Niedrig" 4 "Lehne_Prio_Niedrig" 5 "Lehne_Prio_Mittel" 6 "Lehne_Prio_Hoch" ;
VAL_ 1441 KL_Frischluftklappe_Status 126 "Init" 127 "Fehler" ;
VAL_ 2589283469 KL_Verdampferleistung 254 "Init" 255 "Fehler" ;
VAL_ 2589283469 KL_VK_Anf 0 "keine_Startanf_von_Climatronic" 1 "Startanf_via_FFB" 2 "Startanf_via_Sofortheiztaste" 3 "VK_Strategie_STH" 4 "Startanf_via_ZV_FFB" 5 "VK_Abbruch" 6 "Init" 7 "Fehler" ;
VAL_ 2589283469 KL_Verdampferleistung_Faktor 0 "Faktor_1" 1 "Faktor_2" ;
VAL_ 2589283469 KL_Geblaese_Fond_erw 0 "Geblaese_aus" 1 "Geblaesestufe_10" 2 "Geblaesestufe_20" 3 "Geblaesestufe_30" 4 "Geblaesestufe_40" 5 "Geblaesestufe_50" 6 "Geblaesestufe_60" 7 "Geblaesestufe_70" 8 "Geblaesestufe_80" 9 "Geblaesestufe_90" 10 "Geblaesestufe_100" 14 "Init" 15 "Fehler" ;
VAL_ 2589283469 KL_Geblaese_erw 0 "Geblaese_aus" 1 "Geblaesestufe_10" 2 "Geblaesestufe_20" 3 "Geblaesestufe_30" 4 "Geblaesestufe_40" 5 "Geblaesestufe_50" 6 "Geblaesestufe_60" 7 "Geblaesestufe_70" 8 "Geblaesestufe_80" 9 "Geblaesestufe_90" 10 "Geblaesestufe_100" 14 "Init" 15 "Fehler" ;
VAL_ 2589283469 KL_Vorkond_Strategie 0 "Aus" 1 "Spülen" 2 "Kanalkühlung" 3 "Kühlwasserzirkulation" 4 "Aktive Kühlung" 5 "Heizen" 6 "Reheat" 7 "Heizen_elektrisch" 8 "Heizen_verbrennungstechnisch" 13 "Strategie_nicht_berechnet" 14 "Konditionierung_nicht_moeglich" 15 "Init" ;
VAL_ 2589283469 KL_Tempklappe_re 254 "Init" 255 "Fehler" ;
VAL_ 2589283469 KL_Tempklappe_li 254 "Init" 255 "Fehler" ;
VAL_ 2589283469 KL_Tempklappe_Fond 254 "Init" 255 "Fehler" ;
VAL_ 2589283469 KL_Kuehllstg_Delta_Eingriff 254 "Init" 255 "Fehler" ;
VAL_ 2589283469 KL_Heizlstg_Delta_Eingriff 254 "Init" 255 "Fehler" ;
VAL_ 2589283621 KL_NV_Energie_Anf 254 "Init" 255 "Fehler" ;
VAL_ 2589283621 KL_Umluft_Connect_status 0 "Keine_Umluft" 1 "Umluft_Kundenwunsch" 2 "Umluft_AQS" 3 "Umluft_Backend_Empfehlung" 4 "Umluft_Navi_Daten" ;
VAL_ 2589283621 KL_ECO_PRO_Aktiv 0 "inaktiv" 1 "aktiv" ;
VAL_ 2589283621 KL_QBit_Sonnenintensitaet 0 "gueltiger_Wert" 1 "Ersatz_Init_oder_Fehlerwert" ;
VAL_ 2589283621 KL_ZR_Anforderung 0 "init" 1 "inaktiv" 2 "aktiv" 3 "reserviert" ;
VAL_ 2589283621 KL_ACmax_Aktiv 0 "inaktiv" 1 "aktiv" ;
VAL_ 2589283621 KL_Defrost_Aktiv 0 "inaktiv" 1 "aktiv" ;
VAL_ 2589283621 KL_ECO_Aktiv 0 "inaktiv" 1 "aktiv" ;
VAL_ 2589283621 KL_Status_Klimastil 0 "Modus_1" 1 "Modus_2" 2 "Modus_3" 3 "Modus_4" ;
VAL_ 2589283621 KL_Kundeneingriff_Geblaese 0 "Kein_Kundeneingriff_Geblaese" 1 "Kundeneingriff_Geblaese_aktiv" ;
VAL_ 2589283621 KL_Thermischer_Bedarf 0 "Aus" 1 "Heizen" 2 "Nachlauf_Heizen" 3 "Lueften" 4 "Kuehlen" 6 "Init" 7 "Fehler" ;
VAL_ 2589283621 KL_Eps_Innen 254 "Init" 255 "Fehler" ;
VAL_ 2589283621 KL_Sonnenintensitaet 255 "Fehler" ;
VAL_ 992 KL_Fond_Fuss_Temp_hl 1022 "Init" 1023 "Fehler" ;
VAL_ 992 KL_Fond_Fuss_Temp_hr 1022 "Init" 1023 "Fehler" ;
VAL_ 992 KL_MA_Temp_hl 1022 "Init" 1023 "Fehler" ;
VAL_ 992 KL_SIH_Takt_hl 0 "Aus" 1 "Ein" ;
VAL_ 992 KL_SIH_Takt_hr 0 "Aus" 1 "Ein" ;
VAL_ 992 KL_Fehler_Umluft 0 "Umluftklappe_iO" 1 "Umluftklappe_niO" ;
VAL_ 992 KL_RAB 0 "keine_Auswirkung_auf_Klimasystem" 1 "Fehler_hat_Auswirkung_auf_die_Klimatisierung" ;
VAL_ 992 KL_Fond_Absperrventil 0 "nicht angesteuert" 1 "wird angesteuert" ;
VAL_ 992 KL_Fond_KD_Fehler 0 "kein_KD_Fehler" 1 "KD_Fehler" ;
VAL_ 992 KL_MA_Temp_hr 1022 "Init" 1023 "Fehler" ;
VAL_ 992 KL_Fehler_Fussraum_Klappen 0 "kein_Fehler" 1 "Fehler_Fuss_li" 2 "Fehler_Fuss_re" 3 "Beide_Klappen_defekt" ;
VAL_ 992 KL_Fehler_Temp_Klappen 0 "kein_Fehler" 1 "Fehler_Temp_li" 2 "Fehler_Temp_re" 3 "Beide_Klappen_defekt" ;
VAL_ 992 KL_Fehler_Temp_MA_Klappen 0 "kein_Fehler" 1 "Fehler_MA_li" 2 "Fehler_MA_re" 3 "Beide_Klappen_defekt" ;
VAL_ 1712 FS_Taupunkt 0 "nicht verfuegbar" 1023 "Fehler" ;
VAL_ 1712 FS_ResponseError 0 "normal" 1 "Fehler" ;
VAL_ 1712 FS_Temp_Scheibe 0 "nicht verfuegbar" 1023 "Fehler" ;
VAL_ 1712 FS_Temp_Sensor 0 "nicht verfuegbar" 255 "Fehler" ;
VAL_ 1712 FS_Luftfeuchte_rel 0 "nicht verfuegbar" 255 "Fehler" ;
VAL_ 1505 BCM1_Aussen_Temp_ungef 253 "nicht_verbaut" 254 "Initwert" 255 "Fehler" ;
VAL_ 1505 BCM_Heizungsabsperrventil_Status 0 "HAV_offen" 1 "HAV_geschlossen" 2 "Init_oder_nicht_verbaut" 3 "Fehler" ;
VAL_ 1505 BCM_Heizungspumpe_Status 0 "Pumpe_aus" 1 "Pumpe_aktiv_und_Stauts_iO" 2 "Init_oder_nicht_verbaut" 3 "Fehler" ;
VAL_ 1505 BCM_Kompressorkupplung_Status 0 "Kupplung_offen" 1 "Kupplung_geschlossen" 2 "Init_oder_nicht_verbaut" 3 "Fehler" ;
VAL_ 1505 BCM1_PTC_stufig_Status 0 "Aus" 1 "Stufe_1_aktiv" 2 "Stufe_2_aktiv" 3 "Stufe_3_aktiv" 6 "Init_oder_nicht_verbaut" 7 "Fehler" ;
VAL_ 1505 BCM1_FStatus_Aussentemp_ungef 0 "iO" 1 "niO" ;
VAL_ 1505 BCM1_Kompressorstrom_ist 254 "Init, bzw. nicht verfuegbar" 255 "Fehler" ;
VAL_ 1505 BCM1_OBD_FStatus_ATemp 0 "kein Fehler / Init / nicht verbaut" 1 "KS- (Kurzschluss nach minus)" 2 "KS+ (Kurzschluss nach plus)" 3 "OC (Leitungsunterbrechung)" 4 "OOR+ (Signal zu gross)" 5 "OOR- (Signal zu klein)" 6 "RC+ (Signal unplausibel zu gross)" 7 "RC- (Signal unplausibel zu klein)" 8 "KS+/OC (Kurzschluss nach plus/Unterbrechung)" 9 "KS-/OC  (Kurzschluss nach minus/Unterbrechung)" 10 "KS-/KS+  (Kurzschluss nach minus/plus)" 11 "KS-/KS+/OC (Kurzschluss nach minus/plus/Unterbrechung)" 12 "frei" 13 "frei" 14 "frei" 15 "frei" ;
VAL_ 1717 FSA_Taupunkt 1021 "nicht_verbaut" 1022 "Init" 1023 "Fehler" ;
VAL_ 1717 FSA_ResponseError 0 "normal" 1 "Fehler" ;
VAL_ 1717 FSA_Temp_Luft 1021 "nicht_verbaut" 1022 "Init" 1023 "Fehler" ;
VAL_ 1717 FSA_Luftfeuchte_rel 253 "nicht_verbaut" 254 "Init" 255 "Fehler" ;
VAL_ 1717 FSA_Temp_Sensor 2045 "nicht_verbaut" 2046 "Init" 2047 "Fehler" ;
VAL_ 1717 FSA_Sensorheizung_Status 0 "inaktiv" 1 "aktiv" ;
VAL_ 1513 DS_Kaeltemittel_P 2046 "Init" 2047 "Fehler" ;
VAL_ 1513 DS_Status 0 "i.O." 1 "t.b.d." 2 "Init bzw. nicht verfügbar" 3 "Fehler" ;
VAL_ 1513 ION_Status 0 "Hochspannung_ausgeschaltet" 1 "Hochspannung_eingeschaltet" 2 "Init" ;
VAL_ 1513 ION_Status_LED 0 "Aus" 1 "Ein" ;
VAL_ 1513 AAU_Geblaese 126 "Init" 127 "Fehler" ;
VAL_ 1513 ION_Status_Taster 0 "nicht_betaetigt" 1 "betaetigt" ;
VAL_ 1295 KL_Kuehlenergie_instat_pred 254 "Init" 255 "Fehler" ;
VAL_ 1295 KL_Heizenergie_instat_pred 254 "Init" 255 "Fehler" ;
VAL_ 1295 KL_PTC_ein 0 "Aus" 1 "Ein" ;
VAL_ 1295 KL_Leistungspriorisierung 0 "keine_Priorisierung" 1 "PullDown" 2 "Beschlagsgefahr" 3 "Defrost_aktiv" ;
VAL_ 1295 KL_Verdampfertemperatur 1022 "Init" 1023 "Fehler" ;
VAL_ 1295 KL_Heizbedarf 0 "Kein_Heizbedarf" 1022 "Init" 1023 "Fehler" ;
VAL_ 1295 KL_Kuehlbedarf 253 "Kein_Kuehlbedarf" 254 "Init" 255 "Fehler" ;
VAL_ 1295 KL_Kuehlleistg_stat_erw 254 "Init" 255 "Fehler" ;
VAL_ 1295 KL_Heizleistg_stat_erw 254 "Init" 255 "Fehler" ;
VAL_ 2589283474 KL_Temp_vor_Verdampfer 126 "Init" 127 "Fehler" ;
VAL_ 2589283474 KL_Eps_Innen 254 "Init" 255 "Fehler" ;
VAL_ 2589283474 KL_Tempklappe_Fond_li 254 "Init" 255 "Fehler" ;
VAL_ 2589283474 KL_Tempklappe_Fond_re 254 "Init" 255 "Fehler" ;
VAL_ 2549088270 BCM1_KompSchutz 0 "inaktiv" 1 "aktiv" ;
VAL_ 2549088270 BCM1_Abschaltstufe 0 "keine_Einschraenkung" 1 "Funktionseinschraenkung" ;
VAL_ 2549088270 BCM1_Transport_Mode 0 "keine_Einschraenkung" 1 "Funktionseinschraenkung" ;
VAL_ 2549088270 BCM1_Nachlauftyp 0 "Komm_bei_KL15_EIN" 1 "Komm_nach_KL15_AUS" 2 "Komm_bei_KL15_AUS" ;
VAL_ 2549088270 BCM1_SNI 14 "BCM1" ;
VAL_ 2549088270 KN_BCM1_BusKnockOutTimer 255 "BusKnockOut_deaktiviert" ;
VAL_ 2549088270 NM_BCM1_Wakeup 0 "Peripherie_Wakeup__Ursache_nicht_bekannt" 1 "CAN_Wakeup" 2 "KL15_HW" 3 "KL30" 4 "KL58_xs_xt_xd" 5 "Warnblinktaster_EIN" 6 "LDS_Standlicht" 7 "Klemme_S" 8 "Lock_Unlock_Taster" 9 "Heckdeckel_Grifftaster" 10 "Funkbefehl" 11 "Drehfalle_HL" 12 "Drehfalle_HR" 13 "Motorhaubenkontakt" 14 "Heckdeckel_Vorraste" 15 "Heckdeckel_Hauptraste" 16 "LDS_Abblendlicht" 17 "Drehfalle_FT" 18 "Drehfalle_BT" 19 "Kessy_Schluessel_erkannt" 20 "Heckdeckel_Entriegelungstaster" 21 "Schlossrueckmeldung_HL" 22 "Schlossrueckmeldung_HR" 23 "Lichthupe" 25 "DWA_Heckscheibenbruch" 26 "LIN1" 27 "LIN2" 28 "LIN3" 29 "LIN4" 30 "LIN5" 31 "LIN6" 36 "LDS_Nebellicht_Nebelschlusslicht" 37 "Valet_Taster" 38 "Scheinwerferdiebstahlueberwachung" 39 "Versorgung_Innenlicht_KL30g" 40 "Display_Taster" 41 "RearMode_Taster" 42 "SAD_Taster" 43 "Rollo_Taster" 44 "bCall_Taster" 45 "eCall_Taster" 46 "Sitzpneumatikregler" 47 "Signalhorn" 48 "Zustandswechsel_ZV_BEV_PHEV" 49 "Ladesteckerentriegelung_BEV_PHEV" 50 "LIN10_WakeUp" 51 "Taster_Laderaumschliessung" 52 "STH_Taster" 53 "Defrost_Taster_Betaetigt" 54 "Ladesteckerverriegelung_BEV_PHEV" 128 "ZV_Wiederverriegelung" 129 "Coming_Home_Ende" 130 "Leaving_Home_Ende" 131 "Softtouch_Freigabe_entziehen" 132 "Fensterheber_Freigabe_entziehen" 133 "Schiebedach_Freigabe_entziehen" 134 "Verdeck_Freigabe_entziehen" 135 "ELV_Freigabe" 136 "KL58xt_Ende" 137 "IRUE_Ausloesung" 138 "NGS_Ausloesung" 139 "Sounder_Alarm" 140 "Regenschliessen" 141 "Remotestart" 142 "Lichtwarnung_Ende" 143 "DWA_Alarm" 144 "Innenlicht" 145 "Tankklappe_wurde_geschlossen" 146 "Parklicht" 147 "Klimafunktion" 148 "Standlicht" 254 "Watchdog_Test" 255 "Entwicklungsursache" ;
VAL_ 2549088270 NM_BCM1_Lokalaktiv 0 "war_nicht_lokal_aktiv" 1 "war_lokal_aktiv" ;
VAL_ 2549088270 NM_BCM1_Subsystemaktiv 0 "Subsystem_war_nicht_lokalaktiv" 1 "war_lokalaktiv" ;
VAL_ 2549088270 BCM1_KD_Fehler 0 "kein_KD_Fehler" 1 "KD_Fehler" ;
VAL_ 2549088272 Gateway_KompSchutz 0 "inaktiv" 1 "aktiv" ;
VAL_ 2549088272 Gateway_Abschaltstufe 0 "keine_Einschraenkung" 1 "Funktionseinschraenkung" ;
VAL_ 2549088272 Gateway_Transport_Mode 0 "keine_Einschraenkung" 1 "Funktionseinschraenkung" ;
VAL_ 2549088272 Gateway_Nachlauftyp 0 "Komm_bei_KL15_EIN" 1 "Komm_nach_KL15_AUS" 2 "Komm_bei_KL15_AUS" ;
VAL_ 2549088272 Gateway_SNI 16 "Gateway" ;
VAL_ 2549088272 NM_Gateway_Wakeup 0 "Peripherie_Wakeup__Ursache_nicht_bekannt" 1 "Bus_Wakeup" 2 "KL15_HW" 3 "ACAN_Wakeup" 4 "FCAN_Wakeup" 5 "KCAN_Wakeup" 6 "ICAN_Wakeup" 7 "DiagCAN_Wakeup" 8 "ECAN_Wakeup" 9 "Energie_LIN_Wakeup" 10 "Bedien_LIN_Wakeup" 11 "HybridCAN_Wakeup" 12 "Flexray_Wakeup" 13 "MFL_WakeUp" 14 "Ethernet" 15 "DCAN_Wakeup" 16 "K2CAN_Wakeup" 32 "FlexRay_Branch1_WakeUp" 33 "FlexRay_Branch2_WakeUp" 34 "FlexRay_Branch3_WakeUp" 35 "FlexRay_Branch4_WakeUp" 36 "FlexRay_Branch5_WakeUp" 37 "FlexRay_Branch6_WakeUp" 38 "FlexRay_Branch7_WakeUp" 39 "FlexRay_Branch8_WakeUp" 40 "FlexRay_Branch9_WakeUp" 41 "FlexRay_Branch10_WakeUp" 42 "FlexRay_Branch11_WakeUp" 43 "FlexRay_Branch12_WakeUp" 44 "FlexRay_Branch13_WakeUp" 45 "FlexRay_Branch14_WakeUp" 46 "FlexRay_Branch15_WakeUp" 47 "FlexRay_Branch16_WakeUp" 128 "Energiemanagement" 129 "Funktionswakeup_OBDC" 130 "Hochvoltenergiemanagement" 131 "CWU_empfangen" 132 "Fuer_Bus_relevanten_FC_empfangen" 133 "OnlineDienst_empfangen" 134 "HV_Aktivieren" 135 "HV_Deaktivieren" 136 "VTS_Suche_DriverCard" 137 "VTS_Hupen_Blinken" 138 "Remote_Vehicle_Status" 139 "Plug_and_Charge" 140 "VTS_Wakeup_Infotainment" ;
VAL_ 2549088272 NM_Gateway_Lokalaktiv 0 "war_nicht_lokal_aktiv" 1 "war_lokal_aktiv" ;
VAL_ 2549088272 NM_Gateway_Subsystemaktiv 0 "Subsystem_war_nicht_lokalaktiv" 1 "war_lokalaktiv" ;
VAL_ 2549088272 GW_KD_Fehler 0 "kein_KD_Fehler" 1 "KD_Fehler" ;
VAL_ 2549088326 Klima_KompSchutz 0 "inaktiv" 1 "aktiv" ;
VAL_ 2549088326 Klima_Abschaltstufe 0 "keine_Einschraenkung" 1 "Funktionseinschraenkung" ;
VAL_ 2549088326 Klima_Transport_Mode 0 "keine_Einschraenkung" 1 "Funktionseinschraenkung" ;
VAL_ 2549088326 Klima_Nachlauftyp 0 "Komm_bei_KL15_EIN" 1 "Komm_nach_KL15_AUS" 2 "Komm_bei_KL15_AUS" ;
VAL_ 2549088326 Klima_SNI 70 "Klima" ;
VAL_ 2549088326 KN_Klima_ECUKnockOutTimer 63 "ECUKnockOut_deaktiviert" ;
VAL_ 2549088326 KN_Klima_BusKnockOut 0 "Funktion_nicht_ausgeloest" 1 "Veto_aktiv" 2 "Funktion_ausgeloest" 3 "Funktion_deaktiviert" ;
VAL_ 2549088326 KN_Klima_BusKnockOutTimer 255 "BusKnockOut_deaktiviert" ;
VAL_ 2549088326 NM_Klima_Wakeup 0 "Peripherie_Wakeup__Ursache_nicht_bekannt" 1 "Bus_Wakeup" 2 "KL15_HW" 3 "KL30_Reset" 4 "STH_Taste" 5 "Restwaerme_Menuauswahl" 128 "STH_Ein__Zielzeitlogik" 129 "Standfunktion_Funk_EIN" 130 "Umentscheidung_STL_nach_STH" 131 "Ablauf_der_max_Betriebsdauer" 132 "Geblaese_aus_ein" ;
VAL_ 2549088326 KN_Klima_ECUKnockOut 0 "Funktion_nicht_ausgeloest" 1 "Veto_war_aktiv" 2 "Funktion_ausgeloest" 3 "Funktion_deaktiviert" ;
VAL_ 2549088326 NM_Klima_Lokalaktiv 0 "war_nicht_lokal_aktiv" 1 "war_lokal_aktiv" ;
VAL_ 2549088326 NM_Klima_Subsystemaktiv 0 "Subsystem_war_nicht_lokalaktiv" 1 "war_lokalaktiv" ;
VAL_ 2549088326 KL_KD_Fehler 0 "kein_KD_Fehler" 1 "KD_Fehler" ;
VAL_ 2549088345 Lift_KompSchutz 0 "inaktiv" 1 "aktiv" ;
VAL_ 2549088345 Lift_Abschaltstufe 0 "keine_Einschraenkung" 1 "Funktionseinschraenkung" ;
VAL_ 2549088345 Lift_Transport_Mode 0 "keine_Einschraenkung" 1 "Funktionseinschraenkung" ;
VAL_ 2549088345 Lift_Nachlauftyp 0 "Komm_bei_KL15_EIN" 1 "Komm_nach_KL15_AUS" 2 "Komm_bei_KL15_AUS" ;
VAL_ 2549088345 Lift_SNI 89 "Lift" ;
VAL_ 2549088345 NM_Lift_Wakeup 0 "Peripherie_Wakeup__Ursache_nicht_bekannt" 1 "Bus_Wakeup" 2 "KL15_HW" ;
VAL_ 2549088345 Lift_Lokalaktiv 0 "war_nicht_lokal_aktiv" 1 "war_lokal_aktiv" ;
VAL_ 2549088345 Lift_Subsystemaktiv 0 "Subsystem_war_nicht_lokalaktiv" 1 "war_lokalaktiv" ;
VAL_ 2549088345 Lift_KD_Fehler 0 "kein_KD_Fehler" 1 "KD_Fehler" ;
VAL_ 2549088452 VAS_L_KompSchutz 0 "inaktiv" 1 "aktiv" ;
VAL_ 2549088452 VAS_L_Abschaltstufe 0 "keine_Einschraenkung" 1 "Funktionseinschraenkung" ;
VAL_ 2549088452 VAS_L_Transport_Mode 0 "keine_Einschraenkung" 1 "Funktionseinschraenkung" ;
VAL_ 2549088452 VAS_L_Nachlauftyp 0 "Komm_bei_KL15_EIN" 1 "Komm_nach_KL15_AUS" 2 "Komm_bei_KL15_AUS" ;
VAL_ 2549088452 VAS_L_SNI 196 "VAS_L" ;
VAL_ 2549088452 NM_VAS_L_Wakeup 0 "Peripherie_Wakeup__Ursache_nicht_bekannt" 1 "Bus_Wakeup" 2 "KL15_HW" 3 "Kameraverstellung" ;
VAL_ 2549088452 NM_VAS_L_Lokalaktiv 0 "war_nicht_lokal_aktiv" 1 "war_lokal_aktiv" ;
VAL_ 2549088452 VAS_L_Subsystemaktiv 0 "Subsystem_war_nicht_lokalaktiv" 1 "war_lokalaktiv" ;
VAL_ 2549088452 VAS_L_KD_Fehler 0 "kein_KD_Fehler" 1 "KD_Fehler" ;
VAL_ 2549088453 VAS_R_KompSchutz 0 "inaktiv" 1 "aktiv" ;
VAL_ 2549088453 VAS_R_Abschaltstufe 0 "keine_Einschraenkung" 1 "Funktionseinschraenkung" ;
VAL_ 2549088453 VAS_R_Transport_Mode 0 "keine_Einschraenkung" 1 "Funktionseinschraenkung" ;
VAL_ 2549088453 VAS_R_Nachlauftyp 0 "Komm_bei_KL15_EIN" 1 "Komm_nach_KL15_AUS" 2 "Komm_bei_KL15_AUS" ;
VAL_ 2549088453 VAS_R_SNI 197 "VAS_R" ;
VAL_ 2549088453 NM_VAS_R_Wakeup 0 "Peripherie_Wakeup__Ursache_nicht_bekannt" 1 "Bus_Wakeup" 2 "KL15_HW" 3 "Kameraverstellung" ;
VAL_ 2549088453 NM_VAS_R_Lokalaktiv 0 "war_nicht_lokal_aktiv" 1 "war_lokal_aktiv" ;
VAL_ 2549088453 VAS_R_Subsystemaktiv 0 "Subsystem_war_nicht_lokalaktiv" 1 "war_lokalaktiv" ;
VAL_ 2549088453 VAS_R_KD_Fehler 0 "kein_KD_Fehler" 1 "KD_Fehler" ;
VAL_ 779 KBI_ABS_Lampe 0 "ABS Lampe aus" 1 "ABS Lampe ein" ;
VAL_ 779 KBI_ESP_Lampe 0 "ESP Lampe aus" 1 "ESP Lampe ein" ;
VAL_ 779 KBI_BKL_Lampe 0 "BKL aus" 1 "BKL ein" ;
VAL_ 779 KBI_Airbag_Lampe 0 "Airbag Lampe aus" 1 "Airbag Lampe ein" ;
VAL_ 779 KBI_SILA_gueltig 0 "ungueltig" 1 "gueltig" ;
VAL_ 779 KBI_Vorglueh_System_Lampe 0 "Lampe aus" 1 "Lampe ein" ;
VAL_ 779 KBI_NV_in_Anzeige 0 "NV_nicht_in_Anzeige" 1 "NV_in_Anzeige" ;
VAL_ 779 KBI_Anzeigestatus_ACC 0 "keine_ACC_Anzeige" 1 "ACC_Anzeige_aktiv" ;
VAL_ 779 KBI_Anzeigestatus_GRA 0 "nicht_vorhanden" 1 "Anzeigemoeglichkeit_vorhanden" 2 "reserviert" 3 "Fehler" ;
VAL_ 779 KBI_Tankwarnung 0 "Lampe aus" 1 "Lampe ein" ;
VAL_ 779 KBI_MFA_v_Einheit_01 0 "kmh" 1 "mph" ;
VAL_ 779 KBI_im_Stellgliedtest 0 "kein Stellgliedtest" 1 "Kombi im Stellgliedtest" ;
VAL_ 779 KBI_Anzeigefehler_LDW 0 "nicht vorhanden bzw. unterstützt" 1 "Anzeige iO" 2 "Anzeigefehler" 3 "nicht definiert" ;
VAL_ 779 KBI_Tankwarnung_ungueltig 0 "KBI_Tankwarnung_gueltig" 1 "KBI_Tankwarnung_ungueltig" ;
VAL_ 779 KBI_Handbremse 0 "nicht_angezogen" 1 "angezogen" ;
VAL_ 779 KBI_PLA_in_Anzeige 0 "PLA_nicht_in_Anzeige" 1 "PLA_in_Anzeige" ;
VAL_ 779 KBI_Anzeigefehler_NV 0 "kein_Anzeigefehler" 1 "Anzeigefehler" ;
VAL_ 779 KBI_Anzeigestatus_LIM 0 "nicht_vorhanden" 1 "Anzeigemoeglichkeit_vorhanden" 2 "reserviert" 3 "Fehler" ;
VAL_ 779 KBI_ARA_in_Anzeige 0 "ARA nicht in Anzeige" 1 "ARA in Anzeige" ;
VAL_ 779 KBI_Taster_Lift 0 "nicht_betaetigt" 1 "betaetigt" ;
VAL_ 779 KBI_Taster_Fahrwerk 0 "nicht_betaetigt" 1 "betaetigt" ;
VAL_ 779 KBI_Einheit_Tacho 0 "km/h" 1 "mph" ;
VAL_ 779 KBI_Konsistenz_ACC 0 "ACC Botschaft konsistent" 1 "ACC Botschaft inkonsistent" ;
VAL_ 779 KBI_Fehler_Anzeige_ACC 0 " iO" 1 "Anzeigefehler ACC" ;
VAL_ 779 KBI_Anzeigefehler_SWA 0 "nicht vorhanden bzw. unterstützt" 1 "Anzeige iO" 2 "Anzeigefehler" 3 "nicht definiert" ;
VAL_ 779 KBI_Systemstatus 0 "KBI_IO" 1 "KBI_System_Failure" ;
VAL_ 1719 KBI_Kilometerstand 1048574 "Init" 1048575 "Fehler" ;
VAL_ 1719 KBI_Standzeit_02 131069 "nicht_verfuegbar" 131070 "Init" 131071 "Fehler" ;
VAL_ 1719 KBI_LVDS_Lock 0 "Init_LVDS_nicht_gelockt" 1 "LVDS_gelockt" ;
VAL_ 1719 KBI_Reserve_Warnung_Sek 0 "Keine_Warnung" 1 "Sekundaere_Reservewarnung" ;
VAL_ 1719 KBI_RDK_Kalibrier_Anf 0 "keine_Kalibrieranforderung" 1 "Kalibrieranforderung" ;
VAL_ 1719 KBI_Inhalt_Tank 126 "Init" 127 "Fehler" ;
VAL_ 1719 KBI_FStatus_Tank 0 "Tankfüllstand i.O." 1 "Tankfüllstand n.i.O" ;
VAL_ 1719 KBI_aktive_Laengsfunktion 0 "Init" 1 "Speedlimiter" 2 "GRA_oder_ACC" 3 "PACCh" 4 "HDC" 5 "p_GRA" 6 "p_Lim" 7 "Umschaltung_GRA_Limiter" ;
VAL_ 1719 KBI_GRA_im_ACC 0 "GRA_im_ACC_nicht_ausgewaehlt" 1 "GRA_im_ACC_ausgewaehlt" ;
VAL_ 1719 KBI_Oelwechsel_durchgefuehrt 0 "Oelwechsel_nicht_durchgefuehrt" 1 "Oelwechsel_durchgefuehrt" ;
VAL_ 1719 KBI_QBit_Aussen_Temp_gef 0 "gueltiger_Wert" 1 "Ersatz_Init_oder_Fehlerwert" ;
VAL_ 1719 KBI_Aussen_Temp_gef 253 "nicht verbaut" 254 "Init" 255 "Fehler" ;
VAL_ 919 LDW_Gong 0 "kein akustisches Signal" 1 "Gong_1" 2 "Gong_2" 3 "nicht definiert" ;
VAL_ 919 LDW_Frueh_Spaet 0 "frueh_frueh_aktiv" 1 "frueh_spaet_aktiv" 2 "spaet_spaet_aktiv" 3 "Fehler" ;
VAL_ 919 LDW_Texte 0 "keine_Anzeige" 1 "Laneassist_zur_Zeit_n_verfuegbar" 2 "Laneassist_Systemfehler" 3 "Laneassist_zur_Zeit_keine_SSicht" 4 "Laneassist_Fahreruebernahme" 6 "Emergency_Alert_Fahreruebernahme" 7 "Laneassist_FahreruebernahmeLeise" 8 "Laneassist_FahreruebernahmeStumm" 9 "EA_Fahrstreifenwechsel" 10 "Laneassist_Deaktiviert" ;
VAL_ 919 LDW_Seite_DLCTLC 0 "links" 1 "rechts" ;
VAL_ 919 LDW_Lernmodus 0 "LDW aus" 1 "LDW an/inaktiv" 2 "LDW an/aktiv" 3 "Warnung rechts" 4 "Warnung links" 5 "nicht definiert" 6 "nicht definiert" 7 "nicht definiert" ;
VAL_ 919 LDW_Lernmodus_seitenabhaengig 0 "links_aus__rechts_aus" 1 "HCCA_links_an__rechts_an" 2 "HCCA_links_an__rechts_Warnung" 3 "HCCA_links_Warnung__rechts_an" 4 "links_gestrichelt_rechts_Warnung" 5 "links_outlined__rechts_outlined" 6 "links_outlined__rechts_an" 7 "links_outlined__rechts_Warnung" 8 "links_Warnung_rechts_gestrichel" 9 "links_an__rechts_outlined" 10 "links_an__rechts_an" 11 "links_an__rechts_Warnung" 12 "links_und_rechts_gestrichelt" 13 "links_Warnung__rechts_outlined" 14 "links_Warnung__rechts_an" 15 "links_Warnung__rechts_Warnung" ;
VAL_ 919 LDW_TLC 31 "Init" ;
VAL_ 919 HC_Uss_Anforderung 0 "Ultraschallsensoren Aus" 1 "Ultraschallsensoren An" ;
VAL_ 919 EA_Warnblinken 0 "aus" 1 "Statisch" 2 "Taster" 3 "Statisch_ohne_WBT" ;
VAL_ 919 aLDW_FoD_Status 0 "Init" 1 "Funktion_inaktiv" 2 "Funktion_aktiv" ;
VAL_ 919 LDW_Codierinfo_fuer_VLR 0 "ohne VLR, ohne Akustik" 1 "HMI-Variante VLR" 2 "HMI-Variante VLR + Akustik" 3 "HMI-Variante Akustik" ;
VAL_ 919 LDW_Status_LED_gelb 0 "LDW-Status gelb aus" 1 "LDW-Status gelb aktiv" ;
VAL_ 919 LDW_Status_LED_gruen 0 "LDW-Status gruen aus" 1 "LDW-Status gruen aktiv" ;
VAL_ 919 LKS_LED_an 0 "LED_aus" 1 "LED_ein" ;
